VERSION "HNNBNNNYNNNNNNNNNNNNNNNNNNNNNNNNNNNNNNNNNN/4/%%%/4/'%**4NNN///"

NS_ :

BS_ :

BU_:  Airbag BAP_Tester ICAS1_Gateway ICAS1_KommunikationsServer LE1 LE2 Motor_BEV Schaltbetaetigung

BO_ 333 ACC_18: 32 ICAS1_Gateway
 SG_ ACC_18_CRC  : 0|8@1+ (1.000000,0.000000) [0.000000|255.000000] "" Motor_BEV
 SG_ ACC_18_BZ  : 8|4@1+ (1.000000,0.000000) [0.000000|15.000000] "" Motor_BEV
 SG_ ACC_limitierte_Anfahrdyn  : 12|1@1+ (1.000000,0.000000) [0.000000|1.000000] "" Motor_BEV
 SG_ ACC_nachtr_Stopp_Anf  : 13|1@1+ (1.000000,0.000000) [0.000000|1.000000] "" Vector__XXX
 SG_ ACC_DynErhoehung  : 14|1@1+ (1.000000,0.000000) [0.000000|1.000000] "" Motor_BEV
 SG_ ACC_Freilaufstrategie_TSK  : 15|1@1+ (1.000000,0.000000) [0.000000|1.000000] "" Motor_BEV
 SG_ ACC_zul_Regelabw_unten  : 16|6@1+ (0.024000,0.000000) [0.000000|1.512000] "Unit_MeterPerSeconSquar" Motor_BEV
 SG_ ACC_StartStopp_Info  : 22|2@1+ (1.000000,0.000000) [0.000000|3.000000] "" Vector__XXX
 SG_ ACC_Sollbeschleunigung_02  : 24|11@1+ (0.005000,-7.220000) [-7.220000|3.005000] "Unit_MeterPerSeconSquar" Motor_BEV
 SG_ ACC_zul_Regelabw_oben  : 35|5@1+ (0.062500,0.000000) [0.000000|1.937500] "Unit_MeterPerSeconSquar" Motor_BEV
 SG_ ACC_neg_Sollbeschl_Grad_02  : 40|8@1+ (0.050000,0.000000) [0.000000|12.750000] "Unit_MeterPerCubicSecon" Motor_BEV
 SG_ ACC_pos_Sollbeschl_Grad_02  : 48|8@1+ (0.050000,0.000000) [0.000000|12.750000] "Unit_MeterPerCubicSecon" Motor_BEV
 SG_ ACC_Anfahren  : 56|1@1+ (1.000000,0.000000) [0.000000|1.000000] "" Motor_BEV
 SG_ ACC_Anhalten  : 57|1@1+ (1.000000,0.000000) [0.000000|1.000000] "" Motor_BEV
 SG_ ACC_Typ  : 58|2@1+ (1.000000,0.000000) [0.000000|3.000000] "" Motor_BEV
 SG_ ACC_Status_ACC  : 60|3@1+ (1.000000,0.000000) [0.000000|7.000000] "" Motor_BEV
 SG_ ACC_Minimale_Bremsung  : 63|1@1+ (1.000000,0.000000) [0.000000|1.000000] "" Motor_BEV
 SG_ ACC_Anhalteweg  : 64|11@1+ (0.010000,0.000000) [0.000000|20.450000] "Unit_Meter" Vector__XXX
 SG_ ACC_Boost  : 75|1@1+ (1.000000,0.000000) [0.000000|1.000000] "" Vector__XXX
 SG_ ACC_Freilauf_Anf  : 76|1@1+ (1.000000,0.000000) [0.000000|1.000000] "" Vector__XXX
 SG_ ACC_Anforderung_HMS  : 77|3@1+ (1.000000,0.000000) [0.000000|7.000000] "" Vector__XXX
 SG_ ACC_Folgebeschl  : 80|8@1+ (0.030000,-4.600000) [-4.600000|2.990000] "Unit_MeterPerSeconSquar" Motor_BEV
 SG_ ACC_Freilauf_Info  : 88|2@1+ (1.000000,0.000000) [0.000000|3.000000] "" Motor_BEV
 SG_ ACC_Tempolimitassistent_Ein  : 90|1@1+ (1.000000,0.000000) [0.000000|1.000000] "" Vector__XXX
 SG_ ACC_FoD_Status  : 91|2@1+ (1.000000,0.000000) [0.000000|3.000000] "" Motor_BEV
 SG_ vESC_Verz_Anf  : 232|4@1+ (0.500000,0.000000) [0.000000|3.500000] "Unit_MeterPerSeconSquar" Vector__XXX
 SG_ RDR_v_ueber_Grund  : 236|12@1+ (0.100000,0.000000) [0.000000|409.000000] "Unit_KiloMeterPerHour" Vector__XXX
 SG_ RDR_v_ueber_Grund_Genauigkeit  : 248|6@1+ (0.100000,0.000000) [0.000000|6.000000] "Unit_KiloMeterPerHour" Vector__XXX
 SG_ RDR_v_ueber_Grund_Fahrtrichtung  : 254|2@1+ (1.000000,0.000000) [0.000000|3.000000] "" Vector__XXX

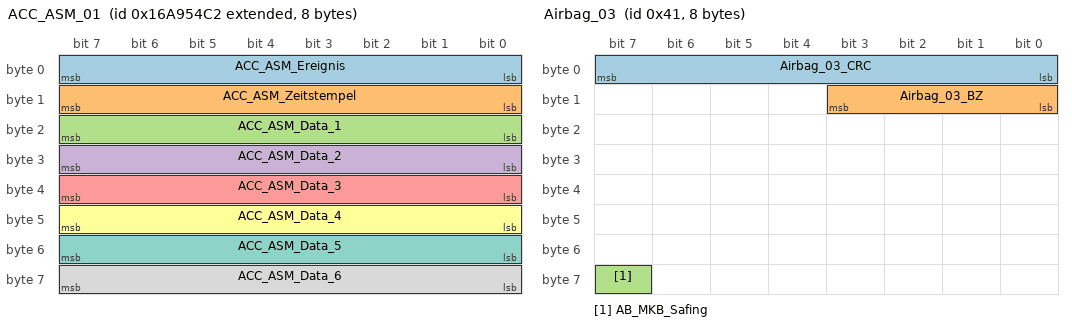
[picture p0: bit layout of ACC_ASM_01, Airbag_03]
BO_ 2527679682 ACC_ASM_01: 8 ICAS1_Gateway
 SG_ ACC_ASM_Ereignis  : 0|8@1+ (1.000000,0.000000) [1.000000|254.000000] "" Airbag
 SG_ ACC_ASM_Zeitstempel  : 8|8@1+ (0.080000,0.000000) [0.000000|20.320000] "Unit_Secon" Airbag
 SG_ ACC_ASM_Data_1  : 16|8@1+ (1.000000,0.000000) [0.000000|255.000000] "" Airbag
 SG_ ACC_ASM_Data_2  : 24|8@1+ (1.000000,0.000000) [0.000000|255.000000] "" Airbag
 SG_ ACC_ASM_Data_3  : 32|8@1+ (1.000000,0.000000) [0.000000|255.000000] "" Airbag
 SG_ ACC_ASM_Data_4  : 40|8@1+ (1.000000,0.000000) [0.000000|255.000000] "" Airbag
 SG_ ACC_ASM_Data_5  : 48|8@1+ (1.000000,0.000000) [0.000000|255.000000] "" Airbag
 SG_ ACC_ASM_Data_6  : 56|8@1+ (1.000000,0.000000) [0.000000|255.000000] "" Airbag

BO_ 64 Airbag_01: 8 Airbag
 SG_ Airbag_01_CRC  : 0|8@1+ (1.000000,0.000000) [0.000000|255.000000] "" ICAS1_Gateway LE1 LE2 Motor_BEV
 SG_ Airbag_01_BZ  : 8|4@1+ (1.000000,0.000000) [0.000000|15.000000] "" ICAS1_Gateway LE1 LE2 Motor_BEV
 SG_ AB_RGS_Anst  : 12|4@1+ (1.000000,0.000000) [0.000000|15.000000] "" ICAS1_Gateway ICAS1_KommunikationsServer
 SG_ AB_Front_Crash  : 16|1@1+ (1.000000,0.000000) [0.000000|1.000000] "" ICAS1_Gateway
 SG_ AB_Heck_Crash  : 17|1@1+ (1.000000,0.000000) [0.000000|1.000000] "" ICAS1_Gateway
 SG_ AB_SF_Crash  : 18|1@1+ (1.000000,0.000000) [0.000000|1.000000] "" ICAS1_Gateway
 SG_ AB_SB_Crash  : 19|1@1+ (1.000000,0.000000) [0.000000|1.000000] "" ICAS1_Gateway
 SG_ AB_Rollover_Crash  : 20|1@1+ (1.000000,0.000000) [0.000000|1.000000] "" ICAS1_Gateway
 SG_ AB_Crash_Int  : 21|3@1+ (1.000000,0.000000) [0.000000|7.000000] "" ICAS1_Gateway ICAS1_KommunikationsServer Motor_BEV
 SG_ AB_Lampe  : 24|1@1+ (1.000000,0.000000) [0.000000|1.000000] "" ICAS1_Gateway ICAS1_KommunikationsServer
 SG_ AB_Deaktiviert  : 25|1@1+ (1.000000,0.000000) [0.000000|1.000000] "" ICAS1_Gateway
 SG_ AB_VB_deaktiviert  : 26|1@1+ (1.000000,0.000000) [0.000000|1.000000] "" ICAS1_Gateway
 SG_ AB_Systemfehler  : 27|1@1+ (1.000000,0.000000) [0.000000|1.000000] "" ICAS1_Gateway ICAS1_KommunikationsServer
 SG_ AB_Diagnose  : 28|1@1+ (1.000000,0.000000) [0.000000|1.000000] "" ICAS1_Gateway
 SG_ AB_Stellgliedtest  : 29|1@1+ (1.000000,0.000000) [0.000000|1.000000] "" ICAS1_Gateway
 SG_ AB_Erh_Auf_VB  : 30|2@1+ (1.000000,0.000000) [0.000000|3.000000] "" ICAS1_Gateway
 SG_ AB_Gurtwarn_VF  : 32|1@1+ (1.000000,0.000000) [0.000000|1.000000] "" ICAS1_Gateway ICAS1_KommunikationsServer
 SG_ AB_Gurtwarn_VB  : 33|1@1+ (1.000000,0.000000) [0.000000|1.000000] "" ICAS1_Gateway ICAS1_KommunikationsServer
 SG_ AB_Anzeige_Fussg  : 34|2@1+ (1.000000,0.000000) [0.000000|3.000000] "" ICAS1_Gateway
 SG_ AB_Texte_AKS  : 36|2@1+ (1.000000,0.000000) [0.000000|3.000000] "" ICAS1_Gateway
 SG_ AB_PAO_Leuchte_Anf  : 38|1@1+ (1.000000,0.000000) [0.000000|1.000000] "" ICAS1_Gateway
 SG_ AB_MKB_gueltig  : 39|1@1+ (1.000000,0.000000) [0.000000|1.000000] "" ICAS1_Gateway
 SG_ AB_MKB_Anforderung  : 40|1@1+ (1.000000,0.000000) [0.000000|1.000000] "" ICAS1_Gateway
 SG_ AB_Versorgungsspannung  : 41|1@1+ (1.000000,0.000000) [0.000000|1.000000] "" ICAS1_Gateway
 SG_ AB_Deaktivierung_HV  : 42|3@1+ (1.000000,0.000000) [0.000000|7.000000] "" ICAS1_Gateway ICAS1_KommunikationsServer LE1 LE2 Motor_BEV
 SG_ AB_EDR_Trigger  : 45|2@1+ (1.000000,0.000000) [0.000000|3.000000] "" ICAS1_Gateway
 SG_ AB_Belegung_VF  : 47|2@1+ (1.000000,0.000000) [0.000000|3.000000] "" ICAS1_Gateway
 SG_ AB_Gurtschloss_FA_ext  : 49|3@1+ (1.000000,0.000000) [0.000000|7.000000] "" ICAS1_Gateway
 SG_ AB_Belegung_VF_ext  : 52|3@1+ (1.000000,0.000000) [0.000000|7.000000] "" ICAS1_Gateway
 SG_ ASM_Masterzeit  : 56|8@1+ (0.080000,0.000000) [0.000000|20.320000] "Unit_Secon" ICAS1_Gateway

BO_ 1312 Airbag_02: 8 Airbag
 SG_ Airbag_02_CRC  : 0|8@1+ (1.000000,0.000000) [0.000000|255.000000] "" ICAS1_Gateway Motor_BEV
 SG_ Airbag_02_BZ  : 8|4@1+ (1.000000,0.000000) [0.000000|15.000000] "" ICAS1_Gateway Motor_BEV
 SG_ LoGeWa_Event_Kombiwarnung  : 12|4@1+ (1.000000,0.000000) [0.000000|15.000000] "" ICAS1_Gateway
 SG_ AB_Anforderung_eCall  : 16|1@1+ (1.000000,0.000000) [0.000000|1.000000] "" ICAS1_Gateway
 SG_ AB_Anprall_Seite_Beifahrer  : 17|1@1+ (1.000000,0.000000) [0.000000|1.000000] "" ICAS1_Gateway ICAS1_KommunikationsServer
 SG_ AB_Anprall_Rollover  : 18|1@1+ (1.000000,0.000000) [0.000000|1.000000] "" ICAS1_Gateway ICAS1_KommunikationsServer
 SG_ AB_Anprall_FGS  : 19|1@1+ (1.000000,0.000000) [0.000000|1.000000] "" ICAS1_Gateway ICAS1_KommunikationsServer
 SG_ AB_Anprall_Front_Beifahrer  : 20|1@1+ (1.000000,0.000000) [0.000000|1.000000] "" ICAS1_Gateway ICAS1_KommunikationsServer
 SG_ AB_Anprall_Front_Fahrer  : 21|1@1+ (1.000000,0.000000) [0.000000|1.000000] "" ICAS1_Gateway ICAS1_KommunikationsServer
 SG_ AB_Anprall_Heck_Beifahrer  : 22|1@1+ (1.000000,0.000000) [0.000000|1.000000] "" ICAS1_Gateway ICAS1_KommunikationsServer
 SG_ AB_Anprall_Heck_Fahrer  : 23|1@1+ (1.000000,0.000000) [0.000000|1.000000] "" ICAS1_Gateway ICAS1_KommunikationsServer
 SG_ AB_Wickelklappung_Reihe2_MI  : 24|2@1+ (1.000000,0.000000) [0.000000|3.000000] "" ICAS1_Gateway
 SG_ AB_Belegung_VB  : 26|2@1+ (1.000000,0.000000) [0.000000|3.000000] "" ICAS1_Gateway
 SG_ AB_Abschaltanf_SIH_BF  : 28|1@1+ (1.000000,0.000000) [0.000000|1.000000] "" ICAS1_Gateway
 SG_ AB_Anprall_Seite_Fahrer  : 29|1@1+ (1.000000,0.000000) [0.000000|1.000000] "" ICAS1_Gateway ICAS1_KommunikationsServer
 SG_ SC_PAO_Schriftzug_Anf  : 30|2@1+ (1.000000,0.000000) [0.000000|3.000000] "" ICAS1_Gateway
 SG_ SC_PAO_ON_Anf  : 32|2@1+ (1.000000,0.000000) [0.000000|3.000000] "" ICAS1_Gateway
 SG_ SC_PAO_OFF_Anf  : 34|2@1+ (1.000000,0.000000) [0.000000|3.000000] "" ICAS1_Gateway
 SG_ AB_Crashschwere  : 36|3@1+ (1.000000,0.000000) [0.000000|7.000000] "" ICAS1_Gateway ICAS1_KommunikationsServer
 SG_ AB_Anforderung_USM  : 39|1@1+ (1.000000,0.000000) [0.000000|1.000000] "" ICAS1_Gateway
 SG_ AB_Gurtschloss_FA  : 40|2@1+ (1.000000,0.000000) [0.000000|3.000000] "" ICAS1_Gateway ICAS1_KommunikationsServer Motor_BEV
 SG_ AB_Gurtschloss_BF  : 42|2@1+ (1.000000,0.000000) [0.000000|3.000000] "" ICAS1_Gateway ICAS1_KommunikationsServer
 SG_ AB_Gurtschloss_Reihe2_FA  : 44|2@1+ (1.000000,0.000000) [0.000000|3.000000] "" ICAS1_Gateway ICAS1_KommunikationsServer
 SG_ AB_Gurtschloss_Reihe2_MI  : 46|2@1+ (1.000000,0.000000) [0.000000|3.000000] "" ICAS1_Gateway ICAS1_KommunikationsServer
 SG_ AB_Gurtschloss_Reihe2_BF  : 48|2@1+ (1.000000,0.000000) [0.000000|3.000000] "" ICAS1_Gateway ICAS1_KommunikationsServer
 SG_ AB_Gurtschloss_Reihe3_FA  : 50|2@1+ (1.000000,0.000000) [0.000000|3.000000] "" ICAS1_Gateway ICAS1_KommunikationsServer
 SG_ AB_Gurtschloss_Reihe3_MI  : 52|2@1+ (1.000000,0.000000) [0.000000|3.000000] "" ICAS1_Gateway ICAS1_KommunikationsServer
 SG_ AB_Gurtschloss_Reihe3_BF  : 54|2@1+ (1.000000,0.000000) [0.000000|3.000000] "" ICAS1_Gateway ICAS1_KommunikationsServer
 SG_ AB_Sitzpos_Sens_FA  : 56|2@1+ (1.000000,0.000000) [0.000000|3.000000] "" ICAS1_Gateway
 SG_ AB_Sitzpos_Sens_BF  : 58|2@1+ (1.000000,0.000000) [0.000000|3.000000] "" ICAS1_Gateway
 SG_ AB_Wickelklappung_Reihe2_BF  : 60|2@1+ (1.000000,0.000000) [0.000000|3.000000] "" ICAS1_Gateway
 SG_ AB_Wickelklappung_Reihe2_FA  : 62|2@1+ (1.000000,0.000000) [0.000000|3.000000] "" ICAS1_Gateway

BO_ 65 Airbag_03: 8 Airbag
 SG_ Airbag_03_CRC  : 0|8@1+ (1.000000,0.000000) [0.000000|255.000000] "" ICAS1_Gateway
 SG_ Airbag_03_BZ  : 8|4@1+ (1.000000,0.000000) [0.000000|15.000000] "" ICAS1_Gateway
 SG_ AB_MKB_Safing  : 63|1@1+ (1.000000,0.000000) [0.000000|1.000000] "" ICAS1_Gateway

BO_ 1349 Airbag_04: 8 Airbag
 SG_ AB_Gurtwarn_Reihe4_FA  : 14|2@1+ (1.000000,0.000000) [0.000000|3.000000] "" ICAS1_Gateway ICAS1_KommunikationsServer
 SG_ AB_Gurtwarn_Reihe4_BF  : 16|2@1+ (1.000000,0.000000) [0.000000|3.000000] "" ICAS1_Gateway ICAS1_KommunikationsServer
 SG_ AB_Gurtwarn_Reihe4_MI  : 18|2@1+ (1.000000,0.000000) [0.000000|3.000000] "" ICAS1_Gateway ICAS1_KommunikationsServer
 SG_ AB_Gurtwarn_Reihe2_FA  : 20|2@1+ (1.000000,0.000000) [0.000000|3.000000] "" ICAS1_Gateway ICAS1_KommunikationsServer
 SG_ AB_Gurtwarn_Reihe2_BF  : 22|2@1+ (1.000000,0.000000) [0.000000|3.000000] "" ICAS1_Gateway ICAS1_KommunikationsServer
 SG_ AbstWarn_MV_FAS_Fkt_Status  : 24|2@1+ (1.000000,0.000000) [0.000000|3.000000] "" ICAS1_Gateway
 SG_ WarnBrems_Charisma_Status  : 26|2@1+ (1.000000,0.000000) [0.000000|3.000000] "" ICAS1_Gateway
 SG_ WarnBrems_Charisma_FahrPr  : 28|4@1+ (1.000000,0.000000) [0.000000|15.000000] "" ICAS1_Gateway
 SG_ AB_Gurtwarn_Reihe2_MI  : 32|2@1+ (1.000000,0.000000) [0.000000|3.000000] "" ICAS1_Gateway ICAS1_KommunikationsServer
 SG_ AB_Gurtwarn_Reihe3_FA  : 34|2@1+ (1.000000,0.000000) [0.000000|3.000000] "" ICAS1_Gateway ICAS1_KommunikationsServer
 SG_ AB_Gurtwarn_Reihe3_MI  : 36|2@1+ (1.000000,0.000000) [0.000000|3.000000] "" ICAS1_Gateway ICAS1_KommunikationsServer
 SG_ AB_Gurtwarn_Reihe3_BF  : 38|2@1+ (1.000000,0.000000) [0.000000|3.000000] "" ICAS1_Gateway ICAS1_KommunikationsServer
 SG_ LGI_FAS_Fkt_Status  : 40|2@1+ (1.000000,0.000000) [0.000000|3.000000] "" ICAS1_Gateway
 SG_ PreCrash_FAS_Fkt_Status  : 42|3@1+ (1.000000,0.000000) [0.000000|7.000000] "" ICAS1_Gateway
 SG_ AB_SBR_hinten_verbau  : 48|2@1+ (1.000000,0.000000) [0.000000|3.000000] "" ICAS1_Gateway ICAS1_KommunikationsServer
 SG_ AWV_Einstellung_System_ASG  : 51|1@1+ (1.000000,0.000000) [0.000000|1.000000] "" ICAS1_Gateway
 SG_ AWV_Einstellung_Warnung_ASG  : 52|3@1+ (1.000000,0.000000) [0.000000|7.000000] "" ICAS1_Gateway
 SG_ SC_PreSense_Modus_Warnung_NV  : 55|3@1+ (1.000000,0.000000) [0.000000|7.000000] "" ICAS1_Gateway
 SG_ SC_PreSense_Modus_Warnung_MV  : 58|3@1+ (1.000000,0.000000) [0.000000|7.000000] "" ICAS1_Gateway
 SG_ SC_PreSense_Modus_System_MV  : 61|1@1+ (1.000000,0.000000) [0.000000|1.000000] "" ICAS1_Gateway
 SG_ SC_PreSense_Modus_System_NV  : 62|1@1+ (1.000000,0.000000) [0.000000|1.000000] "" ICAS1_Gateway
 SG_ SC_PreSense_Modus_System_KAS  : 63|1@1+ (1.000000,0.000000) [0.000000|1.000000] "" ICAS1_Gateway

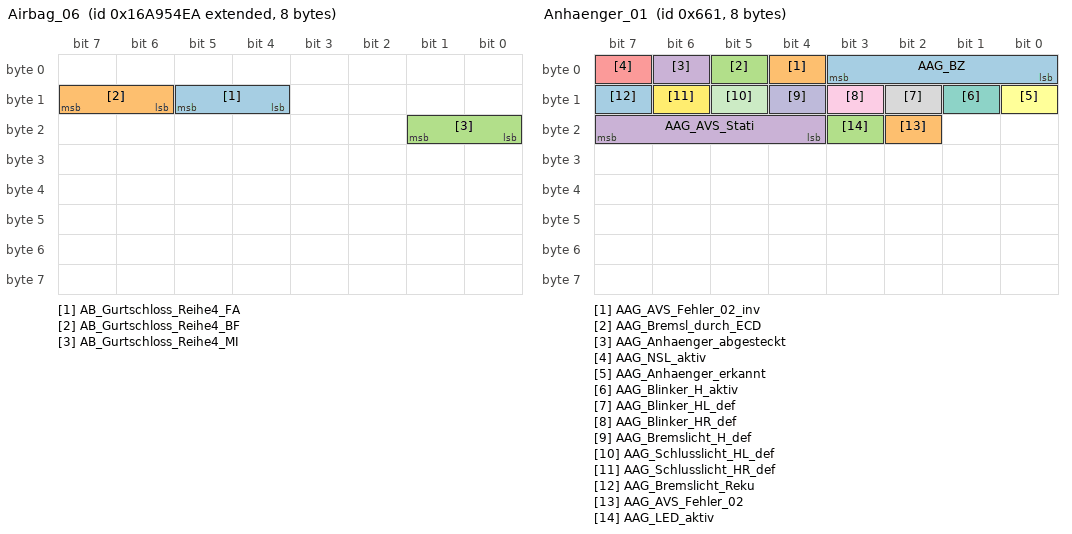
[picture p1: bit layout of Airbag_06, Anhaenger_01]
BO_ 2527679722 Airbag_06: 8 Airbag
 SG_ AB_Gurtschloss_Reihe4_FA  : 12|2@1+ (1.000000,0.000000) [0.000000|3.000000] "" ICAS1_Gateway ICAS1_KommunikationsServer
 SG_ AB_Gurtschloss_Reihe4_BF  : 14|2@1+ (1.000000,0.000000) [0.000000|3.000000] "" ICAS1_Gateway ICAS1_KommunikationsServer
 SG_ AB_Gurtschloss_Reihe4_MI  : 16|2@1+ (1.000000,0.000000) [0.000000|3.000000] "" ICAS1_Gateway ICAS1_KommunikationsServer

BO_ 1633 Anhaenger_01: 8 ICAS1_Gateway
 SG_ AAG_BZ  : 0|4@1+ (1.000000,0.000000) [0.000000|15.000000] "" Vector__XXX
 SG_ AAG_AVS_Fehler_02_inv  : 4|1@1+ (1.000000,0.000000) [0.000000|1.000000] "" Vector__XXX
 SG_ AAG_Bremsl_durch_ECD  : 5|1@1+ (1.000000,0.000000) [0.000000|1.000000] "" Motor_BEV
 SG_ AAG_Anhaenger_abgesteckt  : 6|1@1+ (1.000000,0.000000) [0.000000|1.000000] "" Motor_BEV
 SG_ AAG_NSL_aktiv  : 7|1@1+ (1.000000,0.000000) [0.000000|1.000000] "" Vector__XXX
 SG_ AAG_Anhaenger_erkannt  : 8|1@1+ (1.000000,0.000000) [0.000000|1.000000] "" Motor_BEV
 SG_ AAG_Blinker_H_aktiv  : 9|1@1+ (1.000000,0.000000) [0.000000|1.000000] "" Vector__XXX
 SG_ AAG_Blinker_HL_def  : 10|1@1+ (1.000000,0.000000) [0.000000|1.000000] "" Vector__XXX
 SG_ AAG_Blinker_HR_def  : 11|1@1+ (1.000000,0.000000) [0.000000|1.000000] "" Vector__XXX
 SG_ AAG_Bremslicht_H_def  : 12|1@1+ (1.000000,0.000000) [0.000000|1.000000] "" Motor_BEV
 SG_ AAG_Schlusslicht_HL_def  : 13|1@1+ (1.000000,0.000000) [0.000000|1.000000] "" Vector__XXX
 SG_ AAG_Schlusslicht_HR_def  : 14|1@1+ (1.000000,0.000000) [0.000000|1.000000] "" Vector__XXX
 SG_ AAG_Bremslicht_Reku  : 15|1@1+ (1.000000,0.000000) [0.000000|1.000000] "" Vector__XXX
 SG_ AAG_AVS_Fehler_02  : 18|1@1+ (1.000000,0.000000) [0.000000|1.000000] "" Vector__XXX
 SG_ AAG_LED_aktiv  : 19|1@1+ (1.000000,0.000000) [0.000000|1.000000] "" Vector__XXX
 SG_ AAG_AVS_Stati  : 20|4@1+ (1.000000,0.000000) [0.000000|15.000000] "" Vector__XXX

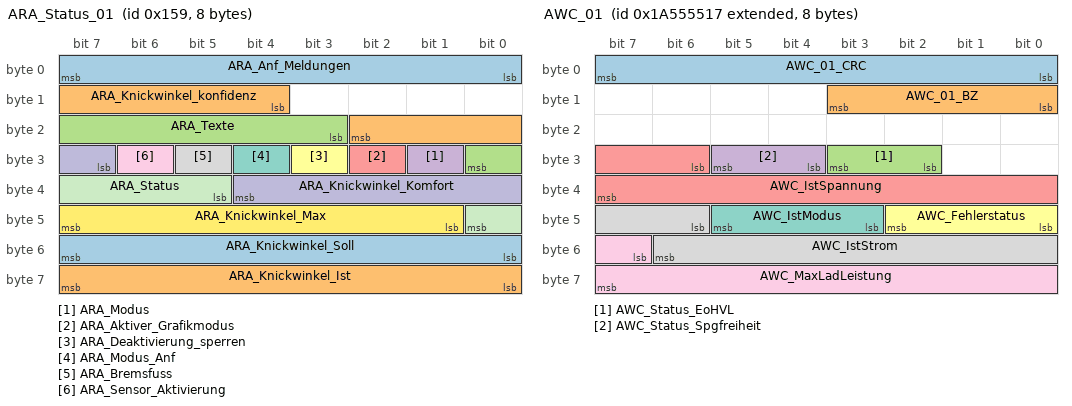
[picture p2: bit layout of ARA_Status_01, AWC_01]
BO_ 345 ARA_Status_01: 8 ICAS1_Gateway
 SG_ ARA_Anf_Meldungen  : 0|8@1+ (1.000000,0.000000) [0.000000|255.000000] "" Vector__XXX
 SG_ ARA_Knickwinkel_konfidenz  : 12|7@1+ (1.000000,0.000000) [0.000000|120.000000] "Unit_DegreOfArc" Vector__XXX
 SG_ ARA_Texte  : 19|6@1+ (1.000000,0.000000) [0.000000|63.000000] "" Vector__XXX
 SG_ ARA_Modus  : 25|1@1+ (1.000000,0.000000) [0.000000|1.000000] "" Vector__XXX
 SG_ ARA_Aktiver_Grafikmodus  : 26|1@1+ (1.000000,0.000000) [0.000000|1.000000] "" Vector__XXX
 SG_ ARA_Deaktivierung_sperren  : 27|1@1+ (1.000000,0.000000) [0.000000|1.000000] "" Vector__XXX
 SG_ ARA_Modus_Anf  : 28|1@1+ (1.000000,0.000000) [0.000000|1.000000] "" Vector__XXX
 SG_ ARA_Bremsfuss  : 29|1@1+ (1.000000,0.000000) [0.000000|1.000000] "" Vector__XXX
 SG_ ARA_Sensor_Aktivierung  : 30|1@1+ (1.000000,0.000000) [0.000000|1.000000] "" Vector__XXX
 SG_ ARA_Knickwinkel_Komfort  : 31|6@1+ (1.000000,0.000000) [0.000000|60.000000] "Unit_DegreOfArc" Vector__XXX
 SG_ ARA_Status  : 37|4@1+ (1.000000,0.000000) [0.000000|15.000000] "" Motor_BEV
 SG_ ARA_Knickwinkel_Max  : 41|7@1+ (1.000000,0.000000) [0.000000|120.000000] "Unit_DegreOfArc" Vector__XXX
 SG_ ARA_Knickwinkel_Soll  : 48|8@1+ (1.000000,-125.000000) [-125.000000|126.000000] "Unit_DegreOfArc" Vector__XXX
 SG_ ARA_Knickwinkel_Ist  : 56|8@1+ (1.000000,-125.000000) [-125.000000|126.000000] "Unit_DegreOfArc" Vector__XXX

BO_ 2589283607 AWC_01: 8 ICAS1_Gateway
 SG_ AWC_01_CRC  : 0|8@1+ (1.000000,0.000000) [0.000000|255.000000] "" Vector__XXX
 SG_ AWC_01_BZ  : 8|4@1+ (1.000000,0.000000) [0.000000|15.000000] "" Vector__XXX
 SG_ AWC_Status_EoHVL  : 26|2@1+ (1.000000,0.000000) [0.000000|3.000000] "" Motor_BEV
 SG_ AWC_Status_Spgfreiheit  : 28|2@1+ (1.000000,0.000000) [0.000000|3.000000] "" Vector__XXX
 SG_ AWC_IstSpannung  : 30|10@1+ (1.000000,0.000000) [0.000000|1021.000000] "Unit_Volt" Vector__XXX
 SG_ AWC_Fehlerstatus  : 40|3@1+ (1.000000,0.000000) [0.000000|7.000000] "" Vector__XXX
 SG_ AWC_IstModus  : 43|3@1+ (1.000000,0.000000) [0.000000|7.000000] "" Vector__XXX
 SG_ AWC_IstStrom  : 46|9@1+ (0.100000,0.000000) [0.000000|50.900000] "Unit_Amper" Vector__XXX
 SG_ AWC_MaxLadLeistung  : 55|9@1+ (25.000000,0.000000) [0.000000|12725.000000] "Unit_Watt" Vector__XXX

BO_ 219 AWV_03: 48 ICAS1_Gateway
 SG_ AWV_03_CRC  : 0|8@1+ (1.000000,0.000000) [0.000000|255.000000] "" Airbag
 SG_ AWV_03_BZ  : 8|4@1+ (1.000000,0.000000) [0.000000|15.000000] "" Airbag
 SG_ PCF_Freigabe  : 12|1@1+ (1.000000,0.000000) [0.000000|1.000000] "" Airbag
 SG_ SDF_PSF_Objektstatus  : 13|3@1+ (1.000000,0.000000) [0.000000|7.000000] "" Airbag
 SG_ SDF_PSF_CU_Status  : 16|1@1+ (1.000000,0.000000) [0.000000|1.000000] "" Airbag
 SG_ SDF_PSF_CW  : 17|7@1+ (1.000000,0.000000) [0.000000|100.000000] "" Airbag
 SG_ SDF_PSF_Fahrer_aktiv  : 24|1@1+ (1.000000,0.000000) [0.000000|1.000000] "" Airbag
 SG_ SDF_PSF_Guete  : 25|2@1+ (1.000000,0.000000) [0.000000|3.000000] "" Airbag
 SG_ SDF_PSF_Kollisionsueberdeckung  : 27|5@1+ (0.100000,0.000000) [0.100000|2.800000] "Unit_Meter" Airbag
 SG_ SDF_PSF_Time_To_Collision  : 32|8@1+ (0.010000,0.000000) [0.000000|2.500000] "Unit_Secon" Vector__XXX
 SG_ SDF_PSF_v_rel  : 40|8@1+ (0.400000,0.000000) [0.400000|101.200000] "Unit_MeterPerSecon" Airbag
 SG_ AWV_Eingriff_Sendeart  : 64|1@1+ (1.000000,0.000000) [0.000000|1.000000] "" Airbag
 SG_ AWV_Verz_Freigabe  : 65|1@1+ (1.000000,0.000000) [0.000000|1.000000] "" Airbag
 SG_ AWV_Verz_Anf  : 66|10@1+ (0.024000,-20.016000) [-20.016000|4.512000] "Unit_MeterPerSeconSquar" Airbag
 SG_ AWV_Anf_Prefill  : 76|1@1+ (1.000000,0.000000) [0.000000|1.000000] "" Airbag
 SG_ AWV_Ruckprofil  : 77|3@1+ (1.000000,0.000000) [0.000000|7.000000] "" Vector__XXX
 SG_ AWV_Time_to_collision  : 80|8@1+ (0.010000,0.000000) [0.000000|2.500000] "Unit_Secon" Airbag
 SG_ AWV_HBA_Param  : 88|2@1+ (1.000000,0.000000) [0.000000|3.000000] "" Vector__XXX
 SG_ AWV_Verz_Anf_ASIL  : 90|3@1+ (1.000000,0.000000) [0.000000|7.000000] "" Vector__XXX
 SG_ AWV_Time_to_brake  : 93|7@1+ (10.000000,0.000000) [0.000000|1240.000000] "Unit_MilliSecon" Vector__XXX
 SG_ AWV_Zielobjekttyp  : 100|4@1+ (1.000000,0.000000) [0.000000|15.000000] "" Airbag
 SG_ AWV_QFK_KruemmSoll  : 104|15@1+ (0.000007,0.000000) [0.000000|0.219539] "Unit_MeterInver" Vector__XXX
 SG_ AWV_QFK_KruemmSoll_VZ  : 119|1@1+ (1.000000,0.000000) [0.000000|1.000000] "" Vector__XXX
 SG_ AWV_QFK_Spuerb  : 120|8@1+ (0.400000,0.000000) [0.000000|100.000000] "Unit_PerCent" Vector__XXX
 SG_ AWV_QFK_AnfStat  : 128|4@1+ (1.000000,0.000000) [0.000000|15.000000] "" Airbag
 SG_ AWV_QFK_Signal1  : 132|10@1+ (1.000000,0.000000) [0.000000|1023.000000] "" Vector__XXX
 SG_ AWV_QFK_Art1  : 142|3@1+ (1.000000,0.000000) [0.000000|7.000000] "" Vector__XXX
 SG_ AWV_QFK_Art2  : 145|3@1+ (1.000000,0.000000) [0.000000|7.000000] "" Vector__XXX
 SG_ AWV_QFK_Signal2  : 148|10@1+ (1.000000,0.000000) [0.000000|1023.000000] "" Vector__XXX

BO_ 2536767264 BAP_Debug_Cmd: 8 BAP_Tester
 SG_ BAP_Debug_Cmd  : 0|16@1+ (1.000000,0.000000) [0.000000|65535.000000] "" Motor_BEV

BO_ 2536767280 BAP_Debug_Data: 8 Motor_BEV
 SG_ BAP_Debug_Data  : 0|64@1+ (1.000000,0.000000) [0.000000|18446744073709551616.000000] "" BAP_Tester

BO_ 2536717313 BAP_EfficiencyAssist_ASG_02: 8 ICAS1_Gateway
 SG_ BAP_EfficAssist_ASG_02_Header  : 0|64@1+ (1.000000,0.000000) [0.000000|18446744073709551616.000000] "" Motor_BEV

BO_ 2536717314 BAP_EfficiencyAssist_ASG_03: 8 ICAS1_Gateway
 SG_ BAP_EfficAssist_ASG_03_Header  : 0|8@1+ (1.000000,0.000000) [0.000000|255.000000] "" Motor_BEV

BO_ 2536717328 BAP_EfficiencyAssist_FSG_01: 8 Motor_BEV
 SG_ BAP_EfficAssist_FSG_01_Header  : 0|8@1+ (1.000000,0.000000) [0.000000|255.000000] "" ICAS1_Gateway

BO_ 2536709120 BAP_Hybrid_ASG_01: 8 ICAS1_Gateway
 SG_ BAP_Hybrid_ASG_01_Header  : 0|8@1+ (1.000000,0.000000) [0.000000|255.000000] "" Motor_BEV

BO_ 2536709136 BAP_Hybrid_FSG_01: 8 Motor_BEV
 SG_ BAP_Hybrid_FSG_01_Header  : 0|8@1+ (1.000000,0.000000) [0.000000|255.000000] "" ICAS1_Gateway

BO_ 869 BEM_05: 8 ICAS1_Gateway
 SG_ BEM_UBDM  : 0|8@1+ (0.050000,5.000000) [5.050000|17.700000] "Unit_Volt" Vector__XXX
 SG_ NVEM_Ladefreigabe  : 8|2@1+ (1.000000,0.000000) [0.000000|3.000000] "" Vector__XXX
 SG_ NVEM_FMAus_Info  : 10|2@1+ (1.000000,0.000000) [0.000000|3.000000] "" Vector__XXX
 SG_ NVEM_PTC_Sollstufe  : 12|2@1+ (1.000000,0.000000) [0.000000|3.000000] "" Vector__XXX
 SG_ NVEM_P_Generator_Status  : 15|1@1+ (1.000000,0.000000) [0.000000|1.000000] "" Vector__XXX
 SG_ BEM_P_Generator  : 16|8@1+ (50.000000,0.000000) [0.000000|12700.000000] "Unit_Watt" Vector__XXX
 SG_ BEM_n_LLA  : 24|2@1+ (1.000000,0.000000) [0.000000|3.000000] "" Vector__XXX
 SG_ BEM_01_Abschaltstufen  : 26|3@1+ (1.000000,0.000000) [0.000000|7.000000] "" Vector__XXX
 SG_ BEM_Anf_KL  : 29|1@1+ (1.000000,0.000000) [0.000000|1.000000] "" Vector__XXX
 SG_ BEM_StartStopp_Info  : 30|2@1+ (1.000000,0.000000) [0.000000|3.000000] "" Vector__XXX
 SG_ BEM_DFM  : 32|5@1+ (3.225000,0.025000) [0.025000|100.000000] "" Vector__XXX
 SG_ BEM_EMLIN_ungueltig  : 37|1@1+ (1.000000,0.000000) [0.000000|1.000000] "" Vector__XXX
 SG_ BEM_Batt_Ab  : 38|1@1+ (1.000000,0.000000) [0.000000|1.000000] "" Motor_BEV
 SG_ NVEM_FMAus_I_Verbrauch  : 39|5@1+ (5.000000,0.000000) [0.000000|145.000000] "Unit_Amper" Vector__XXX
 SG_ NVEM_Freilauf_Info  : 44|2@1+ (1.000000,0.000000) [0.000000|3.000000] "" Vector__XXX
 SG_ BEM_NV_NachladAnf  : 46|2@1+ (1.000000,0.000000) [0.000000|3.000000] "" Vector__XXX
 SG_ BEM_Segel_Info  : 48|2@1+ (1.000000,0.000000) [0.000000|3.000000] "" Vector__XXX
 SG_ BEM_HYB_DC_uSollLV  : 50|6@1+ (0.100000,10.600000) [10.600000|16.000000] "Unit_Volt" Vector__XXX
 SG_ BEM_HYB_DC_uMinLV  : 56|8@1+ (0.100000,0.000000) [0.000000|25.300000] "Unit_Volt" Vector__XXX

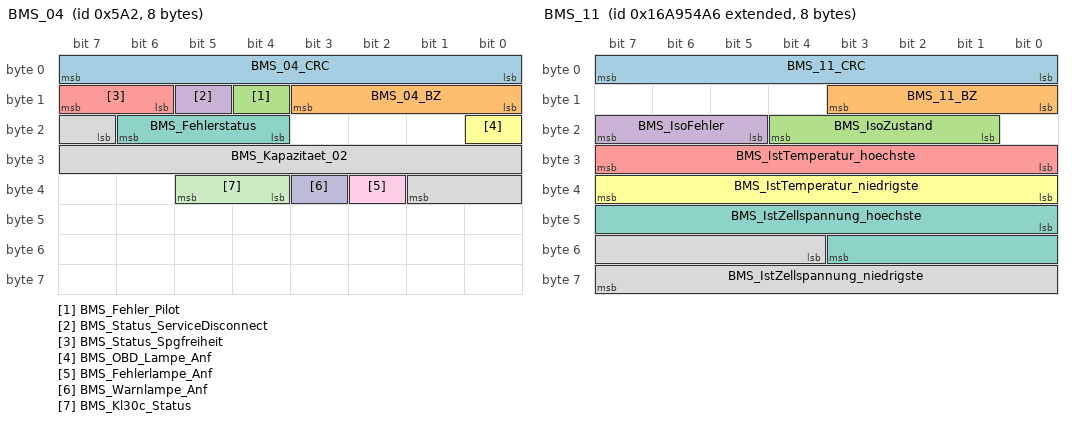
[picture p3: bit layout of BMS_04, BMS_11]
BO_ 1442 BMS_04: 8 ICAS1_Gateway
 SG_ BMS_04_CRC  : 0|8@1+ (1.000000,0.000000) [0.000000|255.000000] "" Vector__XXX
 SG_ BMS_04_BZ  : 8|4@1+ (1.000000,0.000000) [0.000000|15.000000] "" Vector__XXX
 SG_ BMS_Fehler_Pilot  : 12|1@1+ (1.000000,0.000000) [0.000000|1.000000] "" Vector__XXX
 SG_ BMS_Status_ServiceDisconnect  : 13|1@1+ (1.000000,0.000000) [0.000000|1.000000] "" Vector__XXX
 SG_ BMS_Status_Spgfreiheit  : 14|2@1+ (1.000000,0.000000) [0.000000|3.000000] "" Motor_BEV
 SG_ BMS_OBD_Lampe_Anf  : 16|1@1+ (1.000000,0.000000) [0.000000|1.000000] "" Motor_BEV
 SG_ BMS_Fehlerstatus  : 20|3@1+ (1.000000,0.000000) [0.000000|7.000000] "" Vector__XXX
 SG_ BMS_Kapazitaet_02  : 23|11@1+ (0.200000,0.000000) [0.000000|409.200000] "Unit_AmperHour" Vector__XXX
 SG_ BMS_Fehlerlampe_Anf  : 34|1@1+ (1.000000,0.000000) [0.000000|1.000000] "" Motor_BEV
 SG_ BMS_Warnlampe_Anf  : 35|1@1+ (1.000000,0.000000) [0.000000|1.000000] "" Motor_BEV
 SG_ BMS_Kl30c_Status  : 36|2@1+ (1.000000,0.000000) [0.000000|3.000000] "" Motor_BEV

BO_ 2527679654 BMS_11: 8 ICAS1_Gateway
 SG_ BMS_11_CRC  : 0|8@1+ (1.000000,0.000000) [0.000000|255.000000] "" Motor_BEV
 SG_ BMS_11_BZ  : 8|4@1+ (1.000000,0.000000) [0.000000|15.000000] "" Motor_BEV
 SG_ BMS_IsoZustand  : 17|4@1+ (1.000000,0.000000) [0.000000|15.000000] "" Motor_BEV
 SG_ BMS_IsoFehler  : 21|3@1+ (1.000000,0.000000) [0.000000|7.000000] "" Motor_BEV
 SG_ BMS_IstTemperatur_hoechste  : 24|8@1+ (0.500000,-40.000000) [-40.000000|86.000000] "Unit_DegreCelsi" Vector__XXX
 SG_ BMS_IstTemperatur_niedrigste  : 32|8@1+ (0.500000,-40.000000) [-40.000000|86.000000] "Unit_DegreCelsi" Vector__XXX
 SG_ BMS_IstZellspannung_hoechste  : 40|12@1+ (1.000000,1000.000000) [1000.000000|5091.000000] "Unit_MilliVolt" Vector__XXX
 SG_ BMS_IstZellspannung_niedrigste  : 52|12@1+ (1.000000,1000.000000) [1000.000000|5091.000000] "Unit_MilliVolt" Vector__XXX

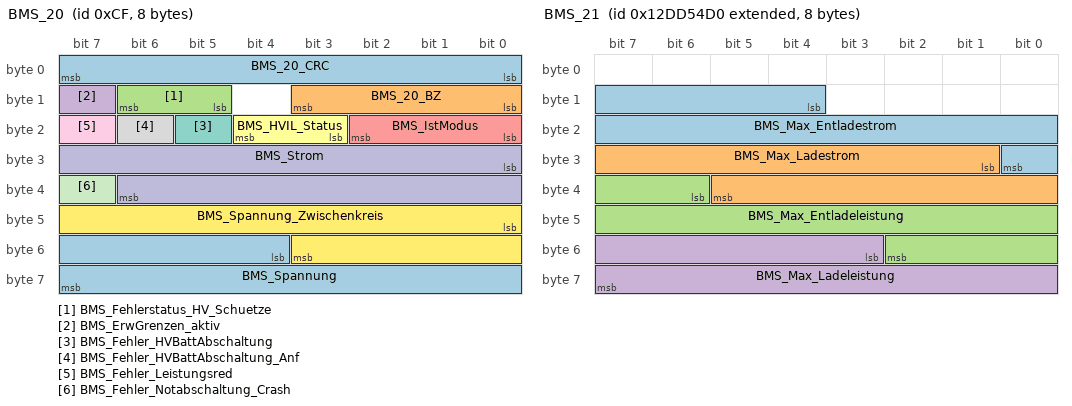
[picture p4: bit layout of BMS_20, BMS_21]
BO_ 207 BMS_20: 8 ICAS1_Gateway
 SG_ BMS_20_CRC  : 0|8@1+ (1.000000,0.000000) [0.000000|255.000000] "" Motor_BEV
 SG_ BMS_20_BZ  : 8|4@1+ (1.000000,0.000000) [0.000000|15.000000] "" Motor_BEV
 SG_ BMS_Fehlerstatus_HV_Schuetze  : 13|2@1+ (1.000000,0.000000) [0.000000|3.000000] "" Motor_BEV
 SG_ BMS_ErwGrenzen_aktiv  : 15|1@1+ (1.000000,0.000000) [0.000000|1.000000] "" Motor_BEV
 SG_ BMS_IstModus  : 16|3@1+ (1.000000,0.000000) [0.000000|7.000000] "" LE1 LE2 Motor_BEV
 SG_ BMS_HVIL_Status  : 19|2@1+ (1.000000,0.000000) [0.000000|3.000000] "" Motor_BEV
 SG_ BMS_Fehler_HVBattAbschaltung  : 21|1@1+ (1.000000,0.000000) [0.000000|1.000000] "" Motor_BEV
 SG_ BMS_Fehler_HVBattAbschaltung_Anf  : 22|1@1+ (1.000000,0.000000) [0.000000|1.000000] "" Motor_BEV
 SG_ BMS_Fehler_Leistungsred  : 23|1@1+ (1.000000,0.000000) [0.000000|1.000000] "" Motor_BEV
 SG_ BMS_Strom  : 24|15@1+ (0.100000,-1630.000000) [-1630.000000|1630.000000] "Unit_Amper" Motor_BEV
 SG_ BMS_Fehler_Notabschaltung_Crash  : 39|1@1+ (1.000000,0.000000) [0.000000|1.000000] "" Vector__XXX
 SG_ BMS_Spannung_Zwischenkreis  : 40|12@1+ (0.500000,-1000.000000) [-1000.000000|1000.000000] "Unit_Volt" Motor_BEV
 SG_ BMS_Spannung  : 52|12@1+ (0.250000,0.000000) [0.000000|1000.000000] "Unit_Volt" Motor_BEV

BO_ 2463978704 BMS_21: 8 ICAS1_Gateway
 SG_ BMS_Max_Entladestrom  : 12|13@1+ (0.200000,0.000000) [0.000000|1630.000000] "Unit_Amper" Motor_BEV
 SG_ BMS_Max_Ladestrom  : 25|13@1+ (0.200000,0.000000) [0.000000|1630.000000] "Unit_Amper" Motor_BEV
 SG_ BMS_Max_Entladeleistung  : 38|13@1+ (100.000000,0.000000) [0.000000|818000.000000] "Unit_Watt" Motor_BEV
 SG_ BMS_Max_Ladeleistung  : 51|13@1+ (100.000000,0.000000) [0.000000|818000.000000] "Unit_Watt" Motor_BEV

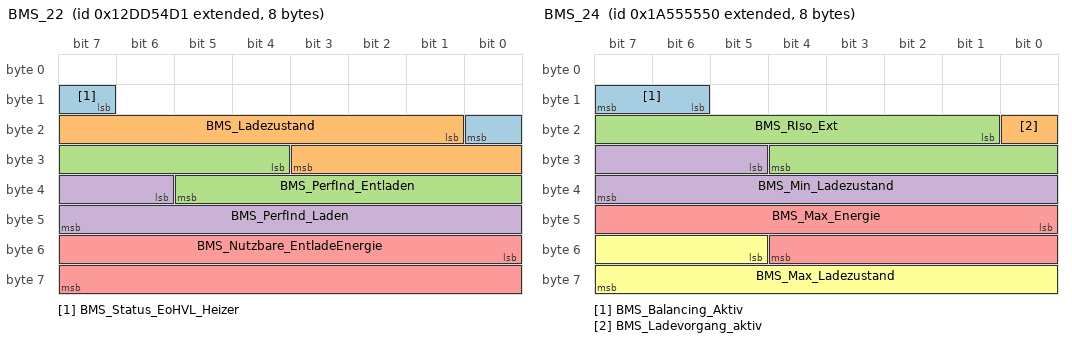
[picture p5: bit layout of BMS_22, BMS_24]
BO_ 2463978705 BMS_22: 8 ICAS1_Gateway
 SG_ BMS_Status_EoHVL_Heizer  : 15|2@1+ (1.000000,0.000000) [0.000000|3.000000] "" Motor_BEV
 SG_ BMS_Ladezustand  : 17|11@1+ (0.050000,0.000000) [0.000000|100.000000] "Unit_PerCent" Motor_BEV
 SG_ BMS_PerfInd_Entladen  : 28|10@1+ (0.200000,0.000000) [0.000000|200.000000] "Unit_PerCent" Motor_BEV
 SG_ BMS_PerfInd_Laden  : 38|10@1+ (0.200000,0.000000) [0.000000|200.000000] "Unit_PerCent" Motor_BEV
 SG_ BMS_Nutzbare_EntladeEnergie  : 48|16@1+ (5.000000,0.000000) [0.000000|327400.000000] "Unit_WattHour" Motor_BEV

BO_ 2589283664 BMS_24: 8 ICAS1_Gateway
 SG_ BMS_Balancing_Aktiv  : 14|2@1+ (1.000000,0.000000) [0.000000|3.000000] "" Vector__XXX
 SG_ BMS_Ladevorgang_aktiv  : 16|1@1+ (1.000000,0.000000) [0.000000|1.000000] "" Vector__XXX
 SG_ BMS_RIso_Ext  : 17|12@1+ (5.000000,0.000000) [0.000000|20465.000000] "Unit_KiloOhm" Motor_BEV
 SG_ BMS_Min_Ladezustand  : 29|11@1+ (0.050000,0.000000) [0.000000|100.000000] "Unit_PerCent" Motor_BEV
 SG_ BMS_Max_Energie  : 40|13@1+ (40.000000,0.000000) [0.000000|327400.000000] "Unit_WattHour" Motor_BEV
 SG_ BMS_Max_Ladezustand  : 53|11@1+ (0.050000,0.000000) [0.000000|100.000000] "Unit_PerCent" Motor_BEV

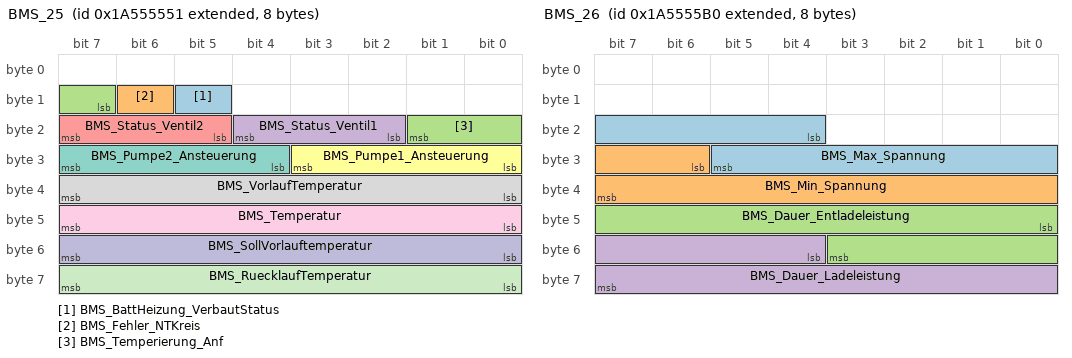
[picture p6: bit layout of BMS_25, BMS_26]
BO_ 2589283665 BMS_25: 8 ICAS1_Gateway
 SG_ BMS_BattHeizung_VerbautStatus  : 13|1@1+ (1.000000,0.000000) [0.000000|1.000000] "" Motor_BEV
 SG_ BMS_Fehler_NTKreis  : 14|1@1+ (1.000000,0.000000) [0.000000|1.000000] "" Vector__XXX
 SG_ BMS_Temperierung_Anf  : 15|3@1+ (1.000000,0.000000) [0.000000|7.000000] "" Motor_BEV
 SG_ BMS_Status_Ventil1  : 18|3@1+ (1.000000,0.000000) [0.000000|7.000000] "" Motor_BEV
 SG_ BMS_Status_Ventil2  : 21|3@1+ (1.000000,0.000000) [0.000000|7.000000] "" Motor_BEV
 SG_ BMS_Pumpe1_Ansteuerung  : 24|4@1+ (10.000000,0.000000) [0.000000|100.000000] "Unit_PerCent" Motor_BEV
 SG_ BMS_Pumpe2_Ansteuerung  : 28|4@1+ (10.000000,0.000000) [0.000000|100.000000] "Unit_PerCent" Motor_BEV
 SG_ BMS_VorlaufTemperatur  : 32|8@1+ (0.500000,-40.000000) [-40.000000|86.000000] "Unit_DegreCelsi" Motor_BEV
 SG_ BMS_Temperatur  : 40|8@1+ (0.500000,-40.000000) [-40.000000|86.500000] "Unit_DegreCelsi" Motor_BEV
 SG_ BMS_SollVorlauftemperatur  : 48|8@1+ (0.500000,-40.000000) [-40.000000|86.500000] "Unit_DegreCelsi" Motor_BEV
 SG_ BMS_RuecklaufTemperatur  : 56|8@1+ (0.500000,-40.000000) [-40.000000|86.000000] "Unit_DegreCelsi" Motor_BEV

BO_ 2589283760 BMS_26: 8 ICAS1_Gateway
 SG_ BMS_Max_Spannung  : 20|10@1+ (1.000000,0.000000) [0.000000|1000.000000] "Unit_Volt" Motor_BEV
 SG_ BMS_Min_Spannung  : 30|10@1+ (1.000000,0.000000) [0.000000|1000.000000] "Unit_Volt" Motor_BEV
 SG_ BMS_Dauer_Entladeleistung  : 40|12@1+ (200.000000,0.000000) [0.000000|818000.000000] "Unit_Watt" Motor_BEV
 SG_ BMS_Dauer_Ladeleistung  : 52|12@1+ (200.000000,0.000000) [0.000000|818000.000000] "Unit_Watt" Motor_BEV

BO_ 2463978646 Charisma_11: 24 ICAS1_Gateway
 SG_ CHA_Ziel_FahrPr_AGA  : 0|4@1+ (1.000000,0.000000) [0.000000|15.000000] "" Vector__XXX
 SG_ CHA_Ziel_FahrPr_ESP  : 4|4@1+ (1.000000,0.000000) [0.000000|15.000000] "" Motor_BEV
 SG_ CHA_Ziel_FahrPr_Freilauf  : 8|4@1+ (1.000000,0.000000) [0.000000|15.000000] "" Vector__XXX
 SG_ CHA_Fahrer_Umschaltung  : 14|1@1+ (1.000000,0.000000) [0.000000|1.000000] "" Motor_BEV
 SG_ CHA_Fahrer_Umschaltung_BMA  : 15|1@1+ (1.000000,0.000000) [0.000000|1.000000] "" Vector__XXX
 SG_ CHA_Ziel_FahrPr_MO  : 16|4@1+ (1.000000,0.000000) [0.000000|15.000000] "" Motor_BEV
 SG_ CHA_Ziel_FahrPr_GE  : 20|4@1+ (1.000000,0.000000) [0.000000|15.000000] "" Vector__XXX
 SG_ CHA_Ziel_FahrPr_ALR  : 24|4@1+ (1.000000,0.000000) [0.000000|15.000000] "" Motor_BEV
 SG_ CHA_Ziel_FahrPr_MO_BZS  : 28|4@1+ (1.000000,0.000000) [0.000000|15.000000] "" Vector__XXX
 SG_ CHA_Ziel_FahrPr_DR  : 32|4@1+ (1.000000,0.000000) [0.000000|15.000000] "" Vector__XXX
 SG_ CHA_Ziel_FahrPr_VAQ  : 36|4@1+ (1.000000,0.000000) [0.000000|15.000000] "" Vector__XXX
 SG_ CHA_Ziel_FahrPr_AFS  : 40|4@1+ (1.000000,0.000000) [0.000000|15.000000] "" Vector__XXX
 SG_ CHA_Ziel_FahrPr_PreCrash  : 44|4@1+ (1.000000,0.000000) [0.000000|15.000000] "" Airbag
 SG_ CHA_Ziel_FahrPr_EPS  : 48|4@1+ (1.000000,0.000000) [0.000000|15.000000] "" Vector__XXX
 SG_ CHA_Ziel_FahrPr_ACC  : 52|4@1+ (1.000000,0.000000) [0.000000|15.000000] "" Vector__XXX
 SG_ CHA_Ziel_FahrPr_SAK  : 56|4@1+ (1.000000,0.000000) [0.000000|15.000000] "" Vector__XXX
 SG_ CHA_Ziel_FahrPr_MO_StSt  : 60|4@1+ (1.000000,0.000000) [0.000000|15.000000] "" Vector__XXX
 SG_ CHA_Ziel_FahrPr_EBKV  : 64|4@1+ (1.000000,0.000000) [0.000000|15.000000] "" Vector__XXX
 SG_ CHA_Ziel_FahrPr_IL  : 68|4@1+ (1.000000,0.000000) [0.000000|15.000000] "" Vector__XXX
 SG_ CHA_Current_Mode  : 72|4@1+ (1.000000,0.000000) [0.000000|15.000000] "" Vector__XXX
 SG_ CHA_Ziel_FahrPr_QS  : 80|4@1+ (1.000000,0.000000) [0.000000|15.000000] "" Vector__XXX
 SG_ CHA_Ziel_FahrPr_SCU  : 84|4@1+ (1.000000,0.000000) [0.000000|15.000000] "" Vector__XXX
 SG_ CHA_Ziel_FahrPr_HAL  : 88|4@1+ (1.000000,0.000000) [0.000000|15.000000] "" Vector__XXX
 SG_ CHA_Ziel_FahrPr_NR  : 92|4@1+ (1.000000,0.000000) [0.000000|15.000000] "" Vector__XXX
 SG_ CHA_Ziel_FahrPr_AV  : 96|4@1+ (1.000000,0.000000) [0.000000|15.000000] "" Vector__XXX
 SG_ CHA_Ziel_FahrPr_MXB  : 100|4@1+ (1.000000,0.000000) [0.000000|15.000000] "" Vector__XXX
 SG_ CHA_Ziel_FahrPr_AFR  : 104|4@1+ (1.000000,0.000000) [0.000000|15.000000] "" Vector__XXX
 SG_ CHA_Ziel_FahrPr_HDC  : 108|4@1+ (1.000000,0.000000) [0.000000|15.000000] "" Vector__XXX
 SG_ CHA_Ziel_FahrPr_EAR  : 112|4@1+ (1.000000,0.000000) [0.000000|15.000000] "" Vector__XXX
 SG_ CHA_Ziel_FahrPr_AEB  : 116|4@1+ (1.000000,0.000000) [0.000000|15.000000] "" Vector__XXX
 SG_ CHA_Ziel_FahrPr_FCWO  : 120|4@1+ (1.000000,0.000000) [0.000000|15.000000] "" Vector__XXX
 SG_ CHA_Ziel_FahrPr_FCWP  : 124|4@1+ (1.000000,0.000000) [0.000000|15.000000] "" Vector__XXX
 SG_ CHA_Ziel_FahrPr_ToS_laengs  : 144|4@1+ (1.000000,0.000000) [0.000000|15.000000] "" Vector__XXX
 SG_ CHA_Ziel_FahrPr_ToS_quer  : 148|4@1+ (1.000000,0.000000) [0.000000|15.000000] "" Vector__XXX
 SG_ CHA_Ziel_FahrPr_mFDR  : 152|4@1+ (1.000000,0.000000) [0.000000|15.000000] "" Vector__XXX
 SG_ CHA_Ziel_FahrPr_Reku_ZwGas  : 156|4@1+ (1.000000,0.000000) [0.000000|15.000000] "" Vector__XXX
 SG_ CHA_Ziel_FahrPr_MO_Freilauf  : 160|4@1+ (1.000000,0.000000) [0.000000|15.000000] "" Vector__XXX
 SG_ CHA_Ziel_FahrPr_BMS  : 164|4@1+ (1.000000,0.000000) [0.000000|15.000000] "" Vector__XXX
 SG_ CHA_Current_Mode_BMA  : 168|4@1+ (1.000000,0.000000) [0.000000|15.000000] "" Vector__XXX
 SG_ CHA_Ziel_FahrPr_PDC  : 172|4@1+ (1.000000,0.000000) [0.000000|15.000000] "" Vector__XXX
 SG_ CHA_Ziel_FahrPr_HHC  : 176|4@1+ (1.000000,0.000000) [0.000000|15.000000] "" Vector__XXX
 SG_ CHA_Ziel_FahrPr_EDS  : 180|4@1+ (1.000000,0.000000) [0.000000|15.000000] "" Vector__XXX
 SG_ CHA_Ziel_FahrPr_PACC  : 184|4@1+ (1.000000,0.000000) [0.000000|15.000000] "" Vector__XXX
 SG_ CHA_Ziel_FahrPr_AGK  : 188|4@1+ (1.000000,0.000000) [0.000000|15.000000] "" Vector__XXX

BO_ 514 Daempfer_03: 32 ICAS1_Gateway
 SG_ DR_Aufbaubeschleunigung_HR  : 12|10@1+ (0.032700,-15.696000) [-15.696000|15.696000] "Unit_MeterPerSeconSquar" Motor_BEV
 SG_ DR_Aufbaubeschleunigung_VR  : 22|10@1+ (0.032700,-15.696000) [-15.696000|15.696000] "Unit_MeterPerSeconSquar" Motor_BEV
 SG_ DR_Aufbaubeschleunigung_VL  : 32|10@1+ (0.032700,-15.696000) [-15.696000|15.696000] "Unit_MeterPerSeconSquar" Motor_BEV
 SG_ DR_Aufbaubeschleunigung_HL  : 42|10@1+ (0.032700,-15.696000) [-15.696000|15.696000] "Unit_MeterPerSeconSquar" Motor_BEV
 SG_ DR_Funktionsstatus  : 52|2@1+ (1.000000,0.000000) [0.000000|3.000000] "" Vector__XXX
 SG_ DR_Drehwinkelsensortausch_VL  : 72|2@1+ (1.000000,0.000000) [1.000000|3.000000] "" Vector__XXX
 SG_ DR_Drehwinkelsensortausch_VR  : 74|2@1+ (1.000000,0.000000) [1.000000|3.000000] "" Vector__XXX
 SG_ DR_Drehwinkelsensortausch_HL  : 76|2@1+ (1.000000,0.000000) [1.000000|3.000000] "" Vector__XXX
 SG_ DR_Drehwinkelsensortausch_HR  : 78|2@1+ (1.000000,0.000000) [1.000000|3.000000] "" Vector__XXX
 SG_ DR_Drehwinkel_VL  : 80|12@1+ (0.088000,0.000000) [0.000000|359.920000] "" Vector__XXX
 SG_ DR_Drehwinkel_VR  : 92|12@1+ (0.088000,0.000000) [0.000000|359.920000] "" Vector__XXX
 SG_ DR_Drehwinkel_HL  : 104|12@1+ (0.088000,0.000000) [0.000000|359.920000] "" Vector__XXX
 SG_ DR_Drehwinkel_HR  : 116|12@1+ (0.088000,0.000000) [0.000000|359.920000] "" Vector__XXX

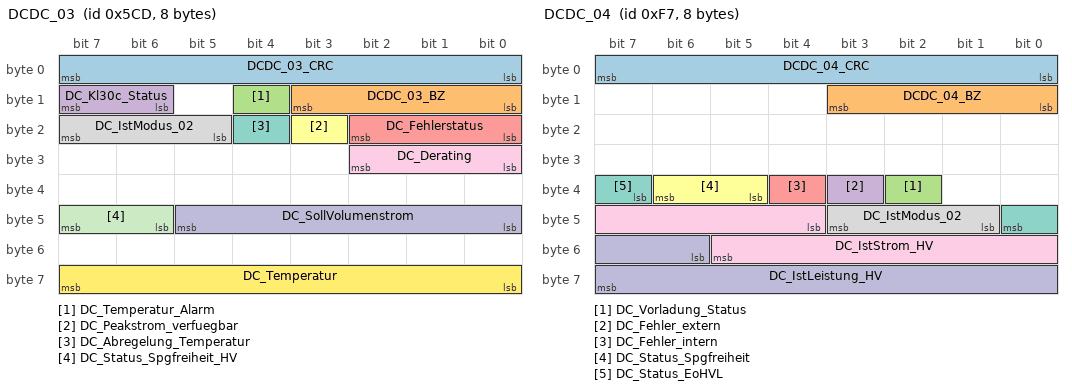
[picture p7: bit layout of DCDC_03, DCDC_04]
BO_ 1485 DCDC_03: 8 ICAS1_Gateway
 SG_ DCDC_03_CRC  : 0|8@1+ (1.000000,0.000000) [0.000000|255.000000] "" Motor_BEV
 SG_ DCDC_03_BZ  : 8|4@1+ (1.000000,0.000000) [0.000000|15.000000] "" Motor_BEV
 SG_ DC_Temperatur_Alarm  : 12|1@1+ (1.000000,0.000000) [0.000000|1.000000] "" Vector__XXX
 SG_ DC_Kl30c_Status  : 14|2@1+ (1.000000,0.000000) [0.000000|3.000000] "" Motor_BEV
 SG_ DC_Fehlerstatus  : 16|3@1+ (1.000000,0.000000) [0.000000|7.000000] "" Vector__XXX
 SG_ DC_Peakstrom_verfuegbar  : 19|1@1+ (1.000000,0.000000) [0.000000|1.000000] "" Vector__XXX
 SG_ DC_Abregelung_Temperatur  : 20|1@1+ (1.000000,0.000000) [0.000000|1.000000] "" Vector__XXX
 SG_ DC_IstModus_02  : 21|3@1+ (1.000000,0.000000) [0.000000|7.000000] "" Vector__XXX
 SG_ DC_Derating  : 24|3@1+ (1.000000,0.000000) [0.000000|7.000000] "" Vector__XXX
 SG_ DC_SollVolumenstrom  : 40|6@1+ (0.500000,0.000000) [0.000000|30.500000] "Unit_LiterPerMinut" Motor_BEV
 SG_ DC_Status_Spgfreiheit_HV  : 46|2@1+ (1.000000,0.000000) [0.000000|3.000000] "" Vector__XXX
 SG_ DC_Temperatur  : 56|8@1+ (1.000000,-40.000000) [-40.000000|213.000000] "Unit_DegreCelsi" Motor_BEV

BO_ 247 DCDC_04: 8 ICAS1_Gateway
 SG_ DCDC_04_CRC  : 0|8@1+ (1.000000,0.000000) [0.000000|255.000000] "" Vector__XXX
 SG_ DCDC_04_BZ  : 8|4@1+ (1.000000,0.000000) [0.000000|15.000000] "" Vector__XXX
 SG_ DC_Vorladung_Status  : 34|1@1+ (1.000000,0.000000) [0.000000|1.000000] "" Motor_BEV
 SG_ DC_Fehler_extern  : 35|1@1+ (1.000000,0.000000) [0.000000|1.000000] "" Motor_BEV
 SG_ DC_Fehler_intern  : 36|1@1+ (1.000000,0.000000) [0.000000|1.000000] "" Motor_BEV
 SG_ DC_Status_Spgfreiheit  : 37|2@1+ (1.000000,0.000000) [0.000000|3.000000] "" Motor_BEV
 SG_ DC_Status_EoHVL  : 39|2@1+ (1.000000,0.000000) [0.000000|3.000000] "" Motor_BEV
 SG_ DC_IstModus_02  : 41|3@1+ (1.000000,0.000000) [0.000000|7.000000] "" Motor_BEV
 SG_ DC_IstStrom_HV  : 44|10@1+ (0.100000,-51.100000) [-51.100000|51.000000] "Unit_Amper" Motor_BEV
 SG_ DC_IstLeistung_HV  : 54|10@1+ (10.000000,-4000.000000) [-4000.000000|6210.000000] "Unit_Watt" Motor_BEV

BO_ 2617027088 DEV_Airbag_ASM_01: 8 Airbag
 SG_ DEV_Airbag_ASM_01_Data  : 0|64@1+ (1.000000,0.000000) [0.000000|18446744073709551616.000000] "" Vector__XXX

BO_ 2617027072 DEV_Airbag_Resp_00: 8 Airbag
 SG_ DEV_Airbag_Resp_00_Data  : 0|64@1+ (1.000000,0.000000) [0.000000|18446744073709551616.000000] "" Vector__XXX

BO_ 2617027073 DEV_Airbag_Resp_01: 8 Airbag
 SG_ DEV_Airbag_Resp_01_Data  : 0|64@1+ (1.000000,0.000000) [0.000000|18446744073709551616.000000] "" Vector__XXX

BO_ 2617027074 DEV_Airbag_Resp_02: 8 Airbag
 SG_ DEV_Airbag_Resp_02_Data  : 0|64@1+ (1.000000,0.000000) [0.000000|18446744073709551616.000000] "" Vector__XXX

BO_ 2617027075 DEV_Airbag_Resp_03: 8 Airbag
 SG_ DEV_Airbag_Resp_03_Data  : 0|64@1+ (1.000000,0.000000) [0.000000|18446744073709551616.000000] "" Vector__XXX

BO_ 2617027076 DEV_Airbag_Resp_04: 8 Airbag
 SG_ DEV_Airbag_Resp_04_Data  : 0|64@1+ (1.000000,0.000000) [0.000000|18446744073709551616.000000] "" Vector__XXX

BO_ 2617027077 DEV_Airbag_Resp_05: 8 Airbag
 SG_ DEV_Airbag_Resp_05_Data  : 0|64@1+ (1.000000,0.000000) [0.000000|18446744073709551616.000000] "" Vector__XXX

BO_ 2617027078 DEV_Airbag_Resp_06: 8 Airbag
 SG_ DEV_Airbag_Resp_06_Data  : 0|64@1+ (1.000000,0.000000) [0.000000|18446744073709551616.000000] "" Vector__XXX

BO_ 2617027079 DEV_Airbag_Resp_07: 8 Airbag
 SG_ DEV_Airbag_Resp_07_Data  : 0|64@1+ (1.000000,0.000000) [0.000000|18446744073709551616.000000] "" Vector__XXX

BO_ 2617027080 DEV_Airbag_Resp_08: 8 Airbag
 SG_ DEV_Airbag_Resp_08_Data  : 0|64@1+ (1.000000,0.000000) [0.000000|18446744073709551616.000000] "" Vector__XXX

BO_ 2617027081 DEV_Airbag_Resp_09: 8 Airbag
 SG_ DEV_Airbag_Resp_09_Data  : 0|64@1+ (1.000000,0.000000) [0.000000|18446744073709551616.000000] "" Vector__XXX

BO_ 2617027082 DEV_Airbag_Resp_10: 8 Airbag
 SG_ DEV_Airbag_Resp_10_Data  : 0|64@1+ (1.000000,0.000000) [0.000000|18446744073709551616.000000] "" Vector__XXX

BO_ 2617027083 DEV_Airbag_Resp_11: 8 Airbag
 SG_ DEV_Airbag_Resp_11_Data  : 0|64@1+ (1.000000,0.000000) [0.000000|18446744073709551616.000000] "" Vector__XXX

BO_ 2617154048 DEV_Waehlhebel_Resp_00: 8 Schaltbetaetigung
 SG_ DEV_Waehlhebel_Resp_00_Data  : 0|64@1+ (1.000000,0.000000) [0.000000|18446744073709551616.000000] "" Vector__XXX

BO_ 2617154049 DEV_Waehlhebel_Resp_01: 8 Schaltbetaetigung
 SG_ DEV_Waehlhebel_Resp_01_Data  : 0|64@1+ (1.000000,0.000000) [0.000000|18446744073709551616.000000] "" Vector__XXX

BO_ 2617154050 DEV_Waehlhebel_Resp_02: 8 Schaltbetaetigung
 SG_ DEV_Waehlhebel_Resp_02_Data  : 0|64@1+ (1.000000,0.000000) [0.000000|18446744073709551616.000000] "" Vector__XXX

BO_ 2617154051 DEV_Waehlhebel_Resp_03: 8 Schaltbetaetigung
 SG_ DEV_Waehlhebel_Resp_03_Data  : 0|64@1+ (1.000000,0.000000) [0.000000|18446744073709551616.000000] "" Vector__XXX

BO_ 2617154052 DEV_Waehlhebel_Resp_04: 8 Schaltbetaetigung
 SG_ DEV_Waehlhebel_Resp_04_Data  : 0|64@1+ (1.000000,0.000000) [0.000000|18446744073709551616.000000] "" Vector__XXX

BO_ 2617154053 DEV_Waehlhebel_Resp_05: 8 Schaltbetaetigung
 SG_ DEV_Waehlhebel_Resp_05_Data  : 0|64@1+ (1.000000,0.000000) [0.000000|18446744073709551616.000000] "" Vector__XXX

BO_ 2549876269 Diag_Waehlhebel_Req: 8 Motor_BEV
 SG_ Diag_Waehlhebel_Req_Data  : 0|64@1+ (1.000000,0.000000) [0.000000|18446744073709551616.000000] "" Schaltbetaetigung

BO_ 2550007341 Diag_Waehlhebel_Resp: 8 Schaltbetaetigung
 SG_ Diag_Waehlhebel_Resp_Data  : 0|64@1+ (1.000000,0.000000) [0.000000|18446744073709551616.000000] "" Motor_BEV

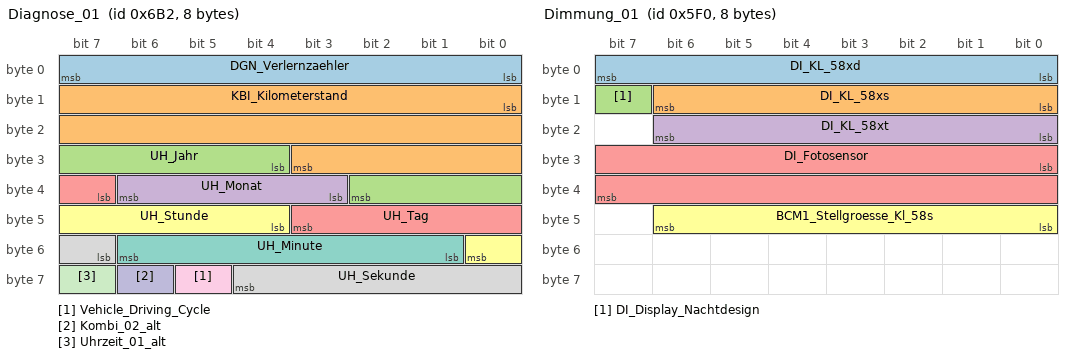
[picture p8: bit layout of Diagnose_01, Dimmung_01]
BO_ 1714 Diagnose_01: 8 ICAS1_Gateway
 SG_ DGN_Verlernzaehler  : 0|8@1+ (1.000000,0.000000) [0.000000|254.000000] "" Airbag LE1 LE2 Motor_BEV
 SG_ KBI_Kilometerstand  : 8|20@1+ (1.000000,0.000000) [0.000000|1048573.000000] "Unit_KiloMeter" Airbag LE1 LE2 Motor_BEV
 SG_ UH_Jahr  : 28|7@1+ (1.000000,2000.000000) [2000.000000|2127.000000] "Unit_Year" Airbag LE1 LE2 Motor_BEV
 SG_ UH_Monat  : 35|4@1+ (1.000000,0.000000) [1.000000|12.000000] "Unit_Month" Airbag LE1 LE2 Motor_BEV
 SG_ UH_Tag  : 39|5@1+ (1.000000,0.000000) [1.000000|31.000000] "Unit_Day" Airbag LE1 LE2 Motor_BEV
 SG_ UH_Stunde  : 44|5@1+ (1.000000,0.000000) [0.000000|23.000000] "Unit_Hours" Airbag LE1 LE2 Motor_BEV
 SG_ UH_Minute  : 49|6@1+ (1.000000,0.000000) [0.000000|59.000000] "Unit_Minut" Airbag LE1 LE2 Motor_BEV
 SG_ UH_Sekunde  : 55|6@1+ (1.000000,0.000000) [0.000000|59.000000] "Unit_Secon" Airbag LE1 LE2 Motor_BEV
 SG_ Vehicle_Driving_Cycle  : 61|1@1+ (1.000000,0.000000) [0.000000|1.000000] "" Airbag
 SG_ Kombi_02_alt  : 62|1@1+ (1.000000,0.000000) [0.000000|1.000000] "" Vector__XXX
 SG_ Uhrzeit_01_alt  : 63|1@1+ (1.000000,0.000000) [0.000000|1.000000] "" Vector__XXX

BO_ 851 DiETa_01: 8 ICAS1_Gateway
 SG_ DiETas_01_CRC  : 0|8@1+ (1.000000,0.000000) [0.000000|255.000000] "" Airbag
 SG_ DiETas_01_BZ  : 8|4@1+ (1.000000,0.000000) [0.000000|15.000000] "" Airbag
 SG_ DiETa_Reserve_Byte2_4  : 12|1@1+ (1.000000,0.000000) [0.000000|1.000000] "" Vector__XXX
 SG_ DiETa_Status  : 13|2@1+ (1.000000,0.000000) [0.000000|3.000000] "" Airbag
 SG_ DiETa_ResponseError  : 15|1@1+ (1.000000,0.000000) [0.000000|1.000000] "" Vector__XXX
 SG_ DiETa_Car  : 16|2@1+ (1.000000,0.000000) [0.000000|3.000000] "" Vector__XXX
 SG_ DiETa_Klima  : 18|2@1+ (1.000000,0.000000) [0.000000|3.000000] "" Vector__XXX
 SG_ DiETa_Mode  : 20|2@1+ (1.000000,0.000000) [0.000000|3.000000] "" Vector__XXX
 SG_ DiETa_Parken  : 22|2@1+ (1.000000,0.000000) [0.000000|3.000000] "" Vector__XXX
 SG_ DiETa_FSH_Taste  : 24|2@1+ (1.000000,0.000000) [0.000000|3.000000] "" Vector__XXX
 SG_ DiETa_HSH_Taste  : 26|2@1+ (1.000000,0.000000) [0.000000|3.000000] "" Vector__XXX
 SG_ DiETa_Warnblink_Taste  : 28|2@1+ (1.000000,0.000000) [0.000000|3.000000] "" Vector__XXX
 SG_ DiETa_FAS_Stufe  : 30|2@1+ (1.000000,0.000000) [0.000000|3.000000] "" Vector__XXX
 SG_ DiETa_PAO_ON_Status  : 32|2@1+ (1.000000,0.000000) [0.000000|3.000000] "" Airbag
 SG_ DiETa_PAO_OFF_Status  : 34|2@1+ (1.000000,0.000000) [0.000000|3.000000] "" Airbag
 SG_ DiETa_Defrost_Taste  : 36|2@1+ (1.000000,0.000000) [0.000000|3.000000] "" Vector__XXX
 SG_ DiETa_Reserve_Byte5_6  : 38|2@1+ (1.000000,0.000000) [0.000000|3.000000] "" Vector__XXX
 SG_ DiETa_Lock_Unlock_Taste  : 40|3@1+ (1.000000,0.000000) [0.000000|7.000000] "" Vector__XXX
 SG_ DiETa_Mode_roh  : 43|1@1+ (1.000000,0.000000) [0.000000|1.000000] "" Vector__XXX
 SG_ DiETa_Reserve_Byte6_3  : 44|4@1+ (1.000000,0.000000) [0.000000|15.000000] "" Vector__XXX
 SG_ DiETa_Reserve_Byte7  : 48|8@1+ (1.000000,0.000000) [0.000000|255.000000] "" Vector__XXX
 SG_ DiETa_Reserve_Byte8  : 56|8@1+ (1.000000,0.000000) [0.000000|255.000000] "" Vector__XXX

BO_ 1520 Dimmung_01: 8 ICAS1_Gateway
 SG_ DI_KL_58xd  : 0|8@1+ (1.000000,0.000000) [0.000000|253.000000] "" Airbag Schaltbetaetigung
 SG_ DI_KL_58xs  : 8|7@1+ (1.000000,0.000000) [0.000000|100.000000] "Unit_PerCent" Airbag
 SG_ DI_Display_Nachtdesign  : 15|1@1+ (1.000000,0.000000) [0.000000|1.000000] "" Vector__XXX
 SG_ DI_KL_58xt  : 16|7@1+ (1.000000,0.000000) [0.000000|100.000000] "Unit_PerCent" Airbag Schaltbetaetigung
 SG_ DI_Fotosensor  : 24|16@1+ (1.000000,0.000000) [0.000000|65535.000000] "" Vector__XXX
 SG_ BCM1_Stellgroesse_Kl_58s  : 40|7@1+ (1.000000,0.000000) [0.000000|100.000000] "" Vector__XXX

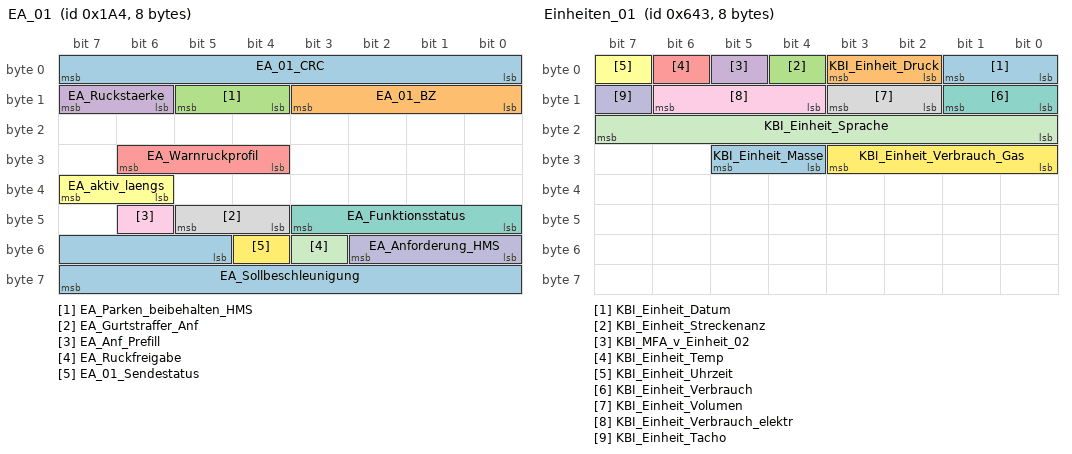
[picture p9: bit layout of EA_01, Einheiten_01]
BO_ 420 EA_01: 8 ICAS1_Gateway
 SG_ EA_01_CRC  : 0|8@1+ (1.000000,0.000000) [0.000000|255.000000] "" Motor_BEV
 SG_ EA_01_BZ  : 8|4@1+ (1.000000,0.000000) [0.000000|15.000000] "" Motor_BEV
 SG_ EA_Parken_beibehalten_HMS  : 12|2@1+ (1.000000,0.000000) [0.000000|3.000000] "" Vector__XXX
 SG_ EA_Ruckstaerke  : 14|2@1+ (1.000000,0.000000) [0.000000|3.000000] "" Vector__XXX
 SG_ EA_Warnruckprofil  : 28|3@1+ (1.000000,0.000000) [0.000000|7.000000] "" Vector__XXX
 SG_ EA_aktiv_laengs  : 38|2@1+ (1.000000,0.000000) [0.000000|3.000000] "" Motor_BEV
 SG_ EA_Funktionsstatus  : 40|4@1+ (1.000000,0.000000) [0.000000|15.000000] "" Motor_BEV
 SG_ EA_Gurtstraffer_Anf  : 44|2@1+ (1.000000,0.000000) [0.000000|3.000000] "" Airbag
 SG_ EA_Anf_Prefill  : 46|1@1+ (1.000000,0.000000) [0.000000|1.000000] "" Vector__XXX
 SG_ EA_Anforderung_HMS  : 48|3@1+ (1.000000,0.000000) [0.000000|7.000000] "" Vector__XXX
 SG_ EA_Ruckfreigabe  : 51|1@1+ (1.000000,0.000000) [0.000000|1.000000] "" Vector__XXX
 SG_ EA_01_Sendestatus  : 52|1@1+ (1.000000,0.000000) [0.000000|1.000000] "" Vector__XXX
 SG_ EA_Sollbeschleunigung  : 53|11@1+ (0.005000,-7.220000) [-7.220000|3.005000] "Unit_MeterPerSeconSquar" Motor_BEV

BO_ 374 EBKV_03: 8 ICAS1_Gateway
 SG_ EBKV_03_CRC  : 0|8@1+ (1.000000,0.000000) [0.000000|255.000000] "" Vector__XXX
 SG_ EBKV_03_BZ  : 8|4@1+ (1.000000,0.000000) [0.000000|15.000000] "" Vector__XXX
 SG_ EBKV_Activate_Fallback_ESP  : 12|1@1+ (1.000000,0.000000) [0.000000|1.000000] "" Vector__XXX
 SG_ EBKV_Restdruckabsenkung  : 13|3@1+ (1.000000,0.000000) [0.000000|7.000000] "" Vector__XXX
 SG_ EBKV_Status_02  : 16|4@1+ (1.000000,0.000000) [0.000000|15.000000] "" Vector__XXX
 SG_ EBKV_Diagnose  : 20|1@1+ (1.000000,0.000000) [0.000000|1.000000] "" Vector__XXX
 SG_ EBKV_Fahrer_bremst  : 21|1@1+ (1.000000,0.000000) [0.000000|1.000000] "" Motor_BEV
 SG_ EBKV_QBit_Fahrer_bremst  : 22|1@1+ (1.000000,0.000000) [0.000000|1.000000] "" Motor_BEV
 SG_ EBKV_Fahrer_bremst_deutlich  : 23|1@1+ (1.000000,0.000000) [0.000000|1.000000] "" Vector__XXX
 SG_ EBKV_OBD_Status  : 24|1@1+ (1.000000,0.000000) [0.000000|1.000000] "" Motor_BEV
 SG_ EBKV_VMM_Sek_Notstopp_Status  : 25|3@1+ (1.000000,0.000000) [0.000000|7.000000] "" Vector__XXX
 SG_ EBKV_Anforderung_HMS  : 28|3@1+ (1.000000,0.000000) [0.000000|7.000000] "" Vector__XXX
 SG_ SBS_Anforderung_GE  : 31|1@1+ (1.000000,0.000000) [0.000000|1.000000] "" Vector__XXX
 SG_ EPB_Status_ext  : 32|3@1+ (1.000000,0.000000) [0.000000|7.000000] "" Motor_BEV
 SG_ EBKV_Bremspedalweg  : 40|8@1+ (0.400000,-0.400000) [0.000000|101.200000] "Unit_PerCent" Motor_BEV
 SG_ EBKV_Kraftblending_Reserve  : 48|8@1+ (0.500000,0.000000) [0.000000|125.000000] "Unit_Bar" Vector__XXX
 SG_ EBKV_Aussteuerdruck  : 56|8@1+ (1.000000,0.000000) [0.000000|250.000000] "Unit_Bar" Vector__XXX

BO_ 1603 Einheiten_01: 8 ICAS1_KommunikationsServer
 SG_ KBI_Einheit_Datum  : 0|2@1+ (1.000000,0.000000) [0.000000|3.000000] "" Vector__XXX
 SG_ KBI_Einheit_Druck  : 2|2@1+ (1.000000,0.000000) [0.000000|3.000000] "" Vector__XXX
 SG_ KBI_Einheit_Streckenanz  : 4|1@1+ (1.000000,0.000000) [0.000000|1.000000] "" Vector__XXX
 SG_ KBI_MFA_v_Einheit_02  : 5|1@1+ (1.000000,0.000000) [0.000000|1.000000] "" Motor_BEV
 SG_ KBI_Einheit_Temp  : 6|1@1+ (1.000000,0.000000) [0.000000|1.000000] "" Vector__XXX
 SG_ KBI_Einheit_Uhrzeit  : 7|1@1+ (1.000000,0.000000) [0.000000|1.000000] "" Vector__XXX
 SG_ KBI_Einheit_Verbrauch  : 8|2@1+ (1.000000,0.000000) [0.000000|3.000000] "" Vector__XXX
 SG_ KBI_Einheit_Volumen  : 10|2@1+ (1.000000,0.000000) [0.000000|3.000000] "" Vector__XXX
 SG_ KBI_Einheit_Verbrauch_elektr  : 12|3@1+ (1.000000,0.000000) [0.000000|7.000000] "" Vector__XXX
 SG_ KBI_Einheit_Tacho  : 15|1@1+ (1.000000,0.000000) [0.000000|1.000000] "" Motor_BEV
 SG_ KBI_Einheit_Sprache  : 16|8@1+ (1.000000,0.000000) [0.000000|255.000000] "" Vector__XXX
 SG_ KBI_Einheit_Verbrauch_Gas  : 24|4@1+ (1.000000,0.000000) [0.000000|15.000000] "" Vector__XXX
 SG_ KBI_Einheit_Masse  : 28|2@1+ (1.000000,0.000000) [0.000000|3.000000] "" Vector__XXX

BO_ 192 EM1_01: 32 LE1
 SG_ EM1_01_CRC  : 0|8@1+ (1.000000,0.000000) [0.000000|255.000000] "" ICAS1_Gateway Motor_BEV
 SG_ EM1_01_BZ  : 8|4@1+ (1.000000,0.000000) [0.000000|15.000000] "" ICAS1_Gateway Motor_BEV
 SG_ EM1_Istmodus  : 12|4@1+ (1.000000,0.000000) [0.000000|15.000000] "" ICAS1_Gateway Motor_BEV
 SG_ EM1_IstMoment  : 16|12@1+ (0.500000,-1023.000000) [-1023.000000|1023.500000] "Unit_NewtoMeter" ICAS1_Gateway Motor_BEV
 SG_ EM1_Moment_AR_Eingriff  : 28|12@1+ (0.500000,-1023.000000) [-1023.000000|1023.500000] "Unit_NewtoMeter" ICAS1_Gateway Motor_BEV
 SG_ EM1_IstDrehzahl  : 40|15@1+ (1.000000,-10000.000000) [-10000.000000|22765.000000] "Unit_MinutInver" ICAS1_Gateway Motor_BEV
 SG_ EM1_AR_aktiv  : 55|1@1+ (1.000000,0.000000) [0.000000|1.000000] "" ICAS1_Gateway Motor_BEV
 SG_ EM1_IstSpannung  : 56|12@1+ (0.250000,0.000000) [0.000000|1023.250000] "Unit_Volt" ICAS1_Gateway Motor_BEV
 SG_ EM1_Strom_HV  : 68|12@1+ (0.500000,-1023.000000) [-1023.000000|1023.500000] "Unit_Amper" ICAS1_Gateway Motor_BEV
 SG_ EM1_Max_Moment  : 80|11@1+ (1.000000,-1023.000000) [-1023.000000|1022.000000] "Unit_NewtoMeter" ICAS1_Gateway Motor_BEV
 SG_ EM1_ErwGrenzen_aktiv  : 91|1@1+ (1.000000,0.000000) [0.000000|1.000000] "" ICAS1_Gateway Motor_BEV
 SG_ EM1_Min_Moment  : 92|11@1+ (1.000000,-1023.000000) [-1023.000000|1022.000000] "Unit_NewtoMeter" ICAS1_Gateway Motor_BEV
 SG_ EM1_Fehler_ElAntriebAbschaltung  : 103|1@1+ (1.000000,0.000000) [0.000000|1.000000] "" ICAS1_Gateway Motor_BEV
 SG_ EM1_Max_Moment_Lim  : 104|11@1+ (1.000000,-1023.000000) [-1023.000000|1022.000000] "Unit_NewtoMeter" ICAS1_Gateway Motor_BEV
 SG_ EM1_Fehler_Notabschaltung  : 115|1@1+ (1.000000,0.000000) [0.000000|1.000000] "" ICAS1_Gateway Motor_BEV
 SG_ EM1_Min_Moment_Lim  : 116|11@1+ (1.000000,-1023.000000) [-1023.000000|1022.000000] "Unit_NewtoMeter" ICAS1_Gateway Motor_BEV
 SG_ EM1_Status_DrzEingriff  : 127|2@1+ (1.000000,0.000000) [0.000000|3.000000] "" ICAS1_Gateway Motor_BEV
 SG_ EM1_Mom_DrzEingriff  : 129|11@1+ (1.000000,-1023.000000) [-1023.000000|1022.000000] "Unit_NewtoMeter" ICAS1_Gateway Motor_BEV

BO_ 2463978673 EM1_02: 32 LE1
 SG_ EM1_Status_Spgfreiheit  : 12|2@1+ (1.000000,0.000000) [0.000000|3.000000] "" Motor_BEV
 SG_ EM1_Status_EoHVL  : 14|2@1+ (1.000000,0.000000) [0.000000|3.000000] "" Motor_BEV
 SG_ EM1_Max_LeistungMech_Sockel  : 16|13@1+ (200.000000,-819000.000000) [-819000.000000|818800.000000] "Unit_Watt" Vector__XXX
 SG_ EM1_Max_Moment_Sockel  : 29|11@1+ (1.000000,-1023.000000) [-1023.000000|1022.000000] "Unit_NewtoMeter" Vector__XXX
 SG_ EM1_Min_LeistungMech_Sockel  : 40|13@1+ (200.000000,-819000.000000) [-819000.000000|818800.000000] "Unit_Watt" Vector__XXX
 SG_ EM1_Min_Moment_Sockel  : 53|11@1+ (1.000000,-1023.000000) [-1023.000000|1022.000000] "Unit_NewtoMeter" Vector__XXX
 SG_ EM1_PerfInd_MaxLeistung  : 64|10@1+ (0.200000,0.000000) [0.000000|200.000000] "Unit_PerCent" Motor_BEV
 SG_ EM1_PerfInd_MaxMoment  : 74|10@1+ (0.200000,0.000000) [0.000000|200.000000] "Unit_PerCent" Motor_BEV
 SG_ EM1_AnlernenElMotor_Anf  : 84|1@1+ (1.000000,0.000000) [0.000000|1.000000] "" Motor_BEV
 SG_ EM1_OBD_Lampe_Anf  : 85|1@1+ (1.000000,0.000000) [0.000000|1.000000] "" Motor_BEV
 SG_ EM1_Generator_Moment  : 86|10@1+ (1.000000,0.000000) [0.000000|1021.000000] "Unit_NewtoMeter" Motor_BEV
 SG_ EM1_PerfInd_Temperatur  : 96|8@1+ (0.800000,0.000000) [0.000000|200.000000] "Unit_PerCent" Motor_BEV
 SG_ EM1_MaxZul_Drehzahl  : 104|8@1+ (80.000000,0.000000) [0.000000|20240.000000] "Unit_RevPerMinute" Motor_BEV
 SG_ EM1_Min_Moment_Gesamt  : 112|11@1+ (1.000000,-1023.000000) [-1023.000000|1022.000000] "Unit_NewtoMeter" Motor_BEV
 SG_ EM1_Fehlerlampe_Anf  : 123|1@1+ (1.000000,0.000000) [0.000000|1.000000] "" Motor_BEV
 SG_ EM1_Max_Moment_Gesamt  : 124|11@1+ (1.000000,-1023.000000) [-1023.000000|1022.000000] "Unit_NewtoMeter" Motor_BEV
 SG_ EM1_Warnlampe_Anf  : 135|1@1+ (1.000000,0.000000) [0.000000|1.000000] "" Motor_BEV
 SG_ EM1_Rekuperation  : 136|15@1+ (10.000000,0.000000) [0.000000|327670.000000] "Unit_WattSecond" Motor_BEV
 SG_ EM1_Rekuperation_Ueberlauf  : 151|1@1+ (1.000000,0.000000) [0.000000|1.000000] "" Motor_BEV
 SG_ EM1_Verbrauch  : 152|15@1+ (10.000000,0.000000) [0.000000|327670.000000] "Unit_WattSecond" Motor_BEV
 SG_ EM1_Verbrauch_Ueberlauf  : 167|1@1+ (1.000000,0.000000) [0.000000|1.000000] "" Motor_BEV
 SG_ EM1_Fehler_AE  : 168|1@1+ (1.000000,0.000000) [0.000000|1.000000] "" Motor_BEV
 SG_ EM1_Fehler_Leistungsred  : 169|1@1+ (1.000000,0.000000) [0.000000|1.000000] "" Motor_BEV
 SG_ EM1_Fehler_ElAntriebFreilauf  : 170|1@1+ (1.000000,0.000000) [0.000000|1.000000] "" Motor_BEV
 SG_ EM1_PWR_SollVolumenstrom  : 171|6@1+ (0.500000,0.000000) [0.000000|30.500000] "Unit_LiterPerMinut" Motor_BEV

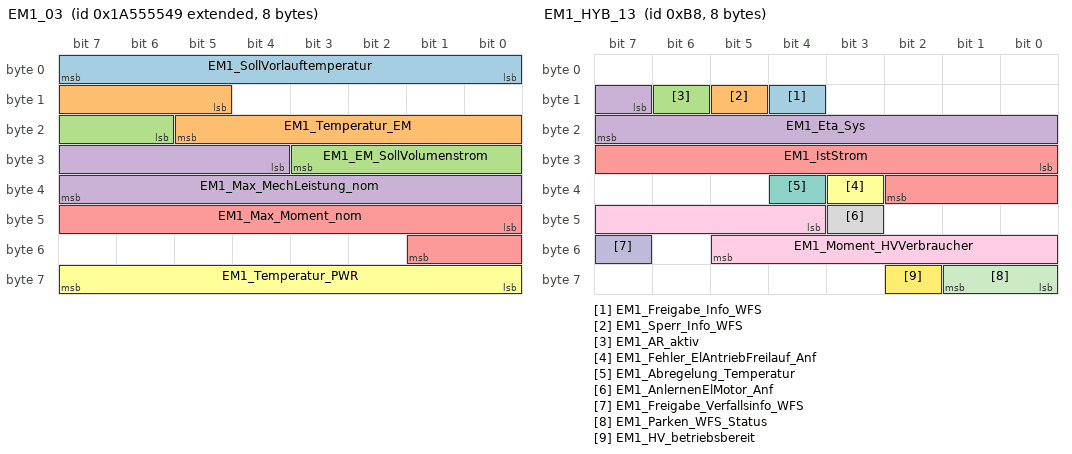
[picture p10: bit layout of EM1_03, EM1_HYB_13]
BO_ 2589283657 EM1_03: 8 LE1
 SG_ EM1_SollVorlauftemperatur  : 0|8@1+ (0.500000,-40.000000) [-40.000000|86.500000] "Unit_DegreCelsi" Motor_BEV
 SG_ EM1_Temperatur_EM  : 13|9@1+ (1.000000,-40.000000) [-40.000000|469.000000] "Unit_DegreCelsi" ICAS1_Gateway Motor_BEV
 SG_ EM1_EM_SollVolumenstrom  : 22|6@1+ (0.500000,0.000000) [0.000000|30.500000] "Unit_LiterPerMinut" Motor_BEV
 SG_ EM1_Max_MechLeistung_nom  : 28|12@1+ (200.000000,0.000000) [0.000000|818600.000000] "Unit_Watt" Motor_BEV
 SG_ EM1_Max_Moment_nom  : 40|10@1+ (1.000000,0.000000) [0.000000|1021.000000] "Unit_NewtoMeter" Motor_BEV
 SG_ EM1_Temperatur_PWR  : 56|8@1+ (1.000000,-40.000000) [-40.000000|213.000000] "Unit_DegreCelsi" ICAS1_Gateway Motor_BEV

BO_ 184 EM1_HYB_13: 8 LE1
 SG_ EM1_Freigabe_Info_WFS  : 12|1@1+ (1.000000,0.000000) [0.000000|1.000000] "" ICAS1_Gateway Motor_BEV
 SG_ EM1_Sperr_Info_WFS  : 13|1@1+ (1.000000,0.000000) [0.000000|1.000000] "" ICAS1_Gateway Motor_BEV
 SG_ EM1_AR_aktiv  : 14|1@1+ (1.000000,0.000000) [0.000000|1.000000] "" ICAS1_Gateway
 SG_ EM1_Eta_Sys  : 15|9@1+ (0.200000,0.000000) [0.000000|101.800000] "Unit_PerCent" ICAS1_Gateway
 SG_ EM1_IstStrom  : 24|11@1+ (1.000000,-1023.000000) [-1023.000000|1022.000000] "Unit_Amper" ICAS1_Gateway
 SG_ EM1_Fehler_ElAntriebFreilauf_Anf  : 35|1@1+ (1.000000,0.000000) [0.000000|1.000000] "" ICAS1_Gateway
 SG_ EM1_Abregelung_Temperatur  : 36|1@1+ (1.000000,0.000000) [0.000000|1.000000] "" ICAS1_Gateway
 SG_ EM1_AnlernenElMotor_Anf  : 43|1@1+ (1.000000,0.000000) [0.000000|1.000000] "" ICAS1_Gateway
 SG_ EM1_Moment_HVVerbraucher  : 44|10@1+ (1.000000,-511.000000) [-511.000000|511.000000] "Unit_NewtoMeter" ICAS1_Gateway
 SG_ EM1_Freigabe_Verfallsinfo_WFS  : 55|1@1+ (1.000000,0.000000) [0.000000|1.000000] "" ICAS1_Gateway Motor_BEV
 SG_ EM1_Parken_WFS_Status  : 56|2@1+ (1.000000,0.000000) [0.000000|3.000000] "" ICAS1_Gateway
 SG_ EM1_HV_betriebsbereit  : 58|1@1+ (1.000000,0.000000) [0.000000|1.000000] "" ICAS1_Gateway

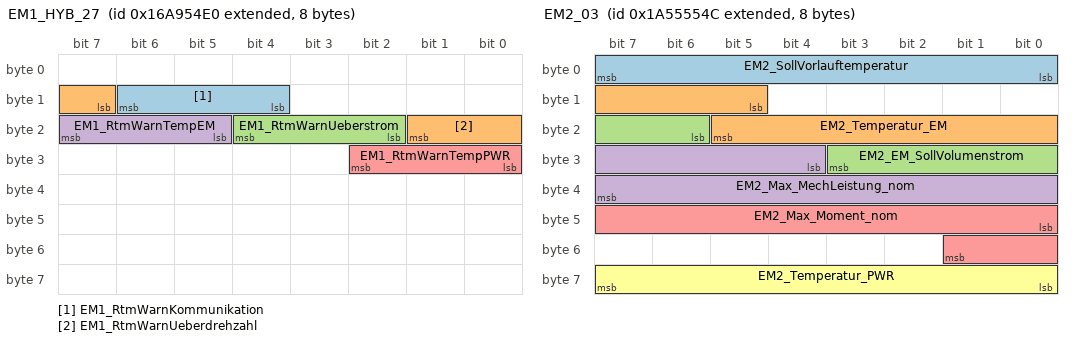
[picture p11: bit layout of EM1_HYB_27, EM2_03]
BO_ 2527679712 EM1_HYB_27: 8 LE1
 SG_ EM1_RtmWarnKommunikation  : 12|3@1+ (1.000000,0.000000) [0.000000|7.000000] "" Vector__XXX
 SG_ EM1_RtmWarnUeberdrehzahl  : 15|3@1+ (1.000000,0.000000) [0.000000|7.000000] "" ICAS1_Gateway
 SG_ EM1_RtmWarnUeberstrom  : 18|3@1+ (1.000000,0.000000) [0.000000|7.000000] "" ICAS1_Gateway
 SG_ EM1_RtmWarnTempEM  : 21|3@1+ (1.000000,0.000000) [0.000000|7.000000] "" ICAS1_Gateway
 SG_ EM1_RtmWarnTempPWR  : 24|3@1+ (1.000000,0.000000) [0.000000|7.000000] "" ICAS1_Gateway

BO_ 193 EM2_01: 32 LE2
 SG_ EM2_01_CRC  : 0|8@1+ (1.000000,0.000000) [0.000000|255.000000] "" Motor_BEV
 SG_ EM2_01_BZ  : 8|4@1+ (1.000000,0.000000) [0.000000|15.000000] "" Motor_BEV
 SG_ EM2_Istmodus  : 12|4@1+ (1.000000,0.000000) [0.000000|15.000000] "" ICAS1_Gateway Motor_BEV
 SG_ EM2_IstMoment  : 16|12@1+ (0.500000,-1023.000000) [-1023.000000|1023.500000] "Unit_NewtoMeter" ICAS1_Gateway Motor_BEV
 SG_ EM2_Moment_AR_Eingriff  : 28|12@1+ (0.500000,-1023.000000) [-1023.000000|1023.500000] "Unit_NewtoMeter" Motor_BEV
 SG_ EM2_IstDrehzahl  : 40|15@1+ (1.000000,-10000.000000) [-10000.000000|22765.000000] "Unit_MinutInver" ICAS1_Gateway Motor_BEV
 SG_ EM2_AR_aktiv  : 55|1@1+ (1.000000,0.000000) [0.000000|1.000000] "" Motor_BEV
 SG_ EM2_IstSpannung  : 56|12@1+ (0.250000,0.000000) [0.000000|1023.250000] "Unit_Volt" ICAS1_Gateway Motor_BEV
 SG_ EM2_Strom_HV  : 68|12@1+ (0.500000,-1023.000000) [-1023.000000|1023.500000] "Unit_Amper" ICAS1_Gateway Motor_BEV
 SG_ EM2_Max_Moment  : 80|11@1+ (1.000000,-1023.000000) [-1023.000000|1022.000000] "Unit_NewtoMeter" Motor_BEV
 SG_ EM2_ErwGrenzen_aktiv  : 91|1@1+ (1.000000,0.000000) [0.000000|1.000000] "" Motor_BEV
 SG_ EM2_Min_Moment  : 92|11@1+ (1.000000,-1023.000000) [-1023.000000|1022.000000] "Unit_NewtoMeter" Motor_BEV
 SG_ EM2_Fehler_ElAntriebAbschaltung  : 103|1@1+ (1.000000,0.000000) [0.000000|1.000000] "" Motor_BEV
 SG_ EM2_Max_Moment_Lim  : 104|11@1+ (1.000000,-1023.000000) [-1023.000000|1022.000000] "Unit_NewtoMeter" Motor_BEV
 SG_ EM2_Fehler_Notabschaltung  : 115|1@1+ (1.000000,0.000000) [0.000000|1.000000] "" ICAS1_Gateway Motor_BEV
 SG_ EM2_Min_Moment_Lim  : 116|11@1+ (1.000000,-1023.000000) [-1023.000000|1022.000000] "Unit_NewtoMeter" Motor_BEV
 SG_ EM2_Status_DrzEingriff  : 127|2@1+ (1.000000,0.000000) [0.000000|3.000000] "" ICAS1_Gateway Motor_BEV
 SG_ EM2_Mom_DrzEingriff  : 129|11@1+ (1.000000,-1023.000000) [-1023.000000|1022.000000] "Unit_NewtoMeter" Motor_BEV

BO_ 2463978674 EM2_02: 32 LE2
 SG_ EM2_Status_Spgfreiheit  : 12|2@1+ (1.000000,0.000000) [0.000000|3.000000] "" Motor_BEV
 SG_ EM2_Status_EoHVL  : 14|2@1+ (1.000000,0.000000) [0.000000|3.000000] "" Motor_BEV
 SG_ EM2_Max_LeistungMech_Sockel  : 16|13@1+ (200.000000,-819000.000000) [-819000.000000|818800.000000] "Unit_Watt" Vector__XXX
 SG_ EM2_Max_Moment_Sockel  : 29|11@1+ (1.000000,-1023.000000) [-1023.000000|1022.000000] "Unit_NewtoMeter" Vector__XXX
 SG_ EM2_Min_LeistungMech_Sockel  : 40|13@1+ (200.000000,-819000.000000) [-819000.000000|818800.000000] "Unit_Watt" Vector__XXX
 SG_ EM2_Min_Moment_Sockel  : 53|11@1+ (1.000000,-1023.000000) [-1023.000000|1022.000000] "Unit_NewtoMeter" Vector__XXX
 SG_ EM2_PerfInd_MaxLeistung  : 64|10@1+ (0.200000,0.000000) [0.000000|200.000000] "Unit_PerCent" Motor_BEV
 SG_ EM2_PerfInd_MaxMoment  : 74|10@1+ (0.200000,0.000000) [0.000000|200.000000] "Unit_PerCent" Motor_BEV
 SG_ EM2_AnlernenElMotor_Anf  : 84|1@1+ (1.000000,0.000000) [0.000000|1.000000] "" Motor_BEV
 SG_ EM2_OBD_Lampe_Anf  : 85|1@1+ (1.000000,0.000000) [0.000000|1.000000] "" Motor_BEV
 SG_ EM2_Generator_Moment  : 86|10@1+ (1.000000,0.000000) [0.000000|1021.000000] "Unit_NewtoMeter" Motor_BEV
 SG_ EM2_PerfInd_Temperatur  : 96|8@1+ (0.800000,0.000000) [0.000000|200.000000] "Unit_PerCent" Motor_BEV
 SG_ EM2_MaxZul_Drehzahl  : 104|8@1+ (80.000000,0.000000) [0.000000|20240.000000] "Unit_RevPerMinute" Motor_BEV
 SG_ EM2_Min_Moment_Gesamt  : 112|11@1+ (1.000000,-1023.000000) [-1023.000000|1022.000000] "Unit_NewtoMeter" Motor_BEV
 SG_ EM2_Fehlerlampe_Anf  : 123|1@1+ (1.000000,0.000000) [0.000000|1.000000] "" Motor_BEV
 SG_ EM2_Max_Moment_Gesamt  : 124|11@1+ (1.000000,-1023.000000) [-1023.000000|1022.000000] "Unit_NewtoMeter" Motor_BEV
 SG_ EM2_Warnlampe_Anf  : 135|1@1+ (1.000000,0.000000) [0.000000|1.000000] "" Motor_BEV
 SG_ EM2_Rekuperation  : 136|15@1+ (10.000000,0.000000) [0.000000|327670.000000] "Unit_WattSecond" Motor_BEV
 SG_ EM2_Rekuperation_Ueberlauf  : 151|1@1+ (1.000000,0.000000) [0.000000|1.000000] "" Motor_BEV
 SG_ EM2_Verbrauch  : 152|15@1+ (10.000000,0.000000) [0.000000|327670.000000] "Unit_WattSecond" Motor_BEV
 SG_ EM2_Verbrauch_Ueberlauf  : 167|1@1+ (1.000000,0.000000) [0.000000|1.000000] "" Motor_BEV
 SG_ EM2_Fehler_AE  : 168|1@1+ (1.000000,0.000000) [0.000000|1.000000] "" Motor_BEV
 SG_ EM2_Fehler_Leistungsred  : 169|1@1+ (1.000000,0.000000) [0.000000|1.000000] "" Motor_BEV
 SG_ EM2_Fehler_ElAntriebFreilauf  : 170|1@1+ (1.000000,0.000000) [0.000000|1.000000] "" Motor_BEV
 SG_ EM2_PWR_SollVolumenstrom  : 171|6@1+ (0.500000,0.000000) [0.000000|30.500000] "Unit_LiterPerMinut" Motor_BEV

BO_ 2589283660 EM2_03: 8 LE2
 SG_ EM2_SollVorlauftemperatur  : 0|8@1+ (0.500000,-40.000000) [-40.000000|86.500000] "Unit_DegreCelsi" Motor_BEV
 SG_ EM2_Temperatur_EM  : 13|9@1+ (1.000000,-40.000000) [-40.000000|469.000000] "Unit_DegreCelsi" ICAS1_Gateway Motor_BEV
 SG_ EM2_EM_SollVolumenstrom  : 22|6@1+ (0.500000,0.000000) [0.000000|30.500000] "Unit_LiterPerMinut" Motor_BEV
 SG_ EM2_Max_MechLeistung_nom  : 28|12@1+ (200.000000,0.000000) [0.000000|818600.000000] "Unit_Watt" Motor_BEV
 SG_ EM2_Max_Moment_nom  : 40|10@1+ (1.000000,0.000000) [0.000000|1021.000000] "Unit_NewtoMeter" Motor_BEV
 SG_ EM2_Temperatur_PWR  : 56|8@1+ (1.000000,-40.000000) [-40.000000|213.000000] "Unit_DegreCelsi" ICAS1_Gateway Motor_BEV

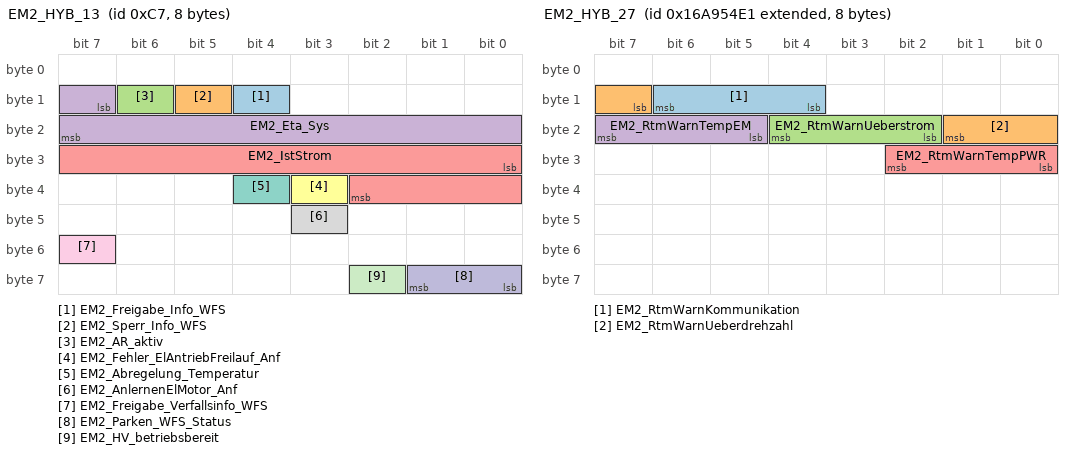
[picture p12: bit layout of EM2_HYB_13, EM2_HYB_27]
BO_ 199 EM2_HYB_13: 8 LE2
 SG_ EM2_Freigabe_Info_WFS  : 12|1@1+ (1.000000,0.000000) [0.000000|1.000000] "" ICAS1_Gateway Motor_BEV
 SG_ EM2_Sperr_Info_WFS  : 13|1@1+ (1.000000,0.000000) [0.000000|1.000000] "" ICAS1_Gateway Motor_BEV
 SG_ EM2_AR_aktiv  : 14|1@1+ (1.000000,0.000000) [0.000000|1.000000] "" ICAS1_Gateway
 SG_ EM2_Eta_Sys  : 15|9@1+ (0.200000,0.000000) [0.000000|101.800000] "Unit_PerCent" ICAS1_Gateway
 SG_ EM2_IstStrom  : 24|11@1+ (1.000000,-1023.000000) [-1023.000000|1022.000000] "Unit_Amper" ICAS1_Gateway
 SG_ EM2_Fehler_ElAntriebFreilauf_Anf  : 35|1@1+ (1.000000,0.000000) [0.000000|1.000000] "" ICAS1_Gateway
 SG_ EM2_Abregelung_Temperatur  : 36|1@1+ (1.000000,0.000000) [0.000000|1.000000] "" ICAS1_Gateway
 SG_ EM2_AnlernenElMotor_Anf  : 43|1@1+ (1.000000,0.000000) [0.000000|1.000000] "" ICAS1_Gateway
 SG_ EM2_Freigabe_Verfallsinfo_WFS  : 55|1@1+ (1.000000,0.000000) [0.000000|1.000000] "" ICAS1_Gateway Motor_BEV
 SG_ EM2_Parken_WFS_Status  : 56|2@1+ (1.000000,0.000000) [0.000000|3.000000] "" ICAS1_Gateway
 SG_ EM2_HV_betriebsbereit  : 58|1@1+ (1.000000,0.000000) [0.000000|1.000000] "" ICAS1_Gateway

BO_ 2527679713 EM2_HYB_27: 8 LE2
 SG_ EM2_RtmWarnKommunikation  : 12|3@1+ (1.000000,0.000000) [0.000000|7.000000] "" Vector__XXX
 SG_ EM2_RtmWarnUeberdrehzahl  : 15|3@1+ (1.000000,0.000000) [0.000000|7.000000] "" ICAS1_Gateway
 SG_ EM2_RtmWarnUeberstrom  : 18|3@1+ (1.000000,0.000000) [0.000000|7.000000] "" ICAS1_Gateway
 SG_ EM2_RtmWarnTempEM  : 21|3@1+ (1.000000,0.000000) [0.000000|7.000000] "" ICAS1_Gateway
 SG_ EM2_RtmWarnTempPWR  : 24|3@1+ (1.000000,0.000000) [0.000000|7.000000] "" ICAS1_Gateway

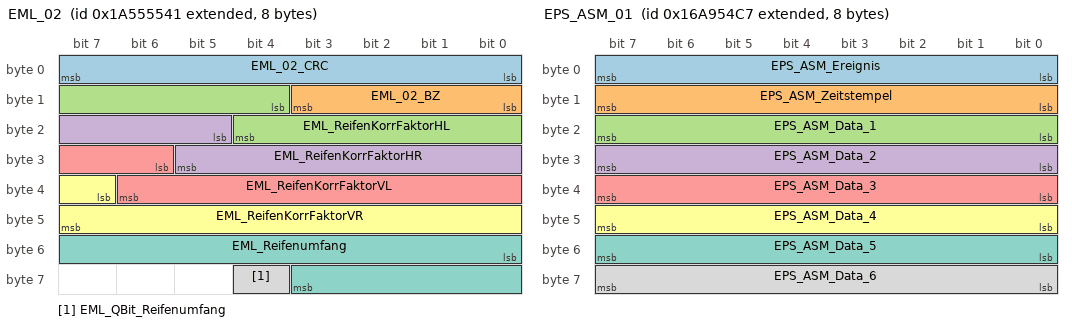
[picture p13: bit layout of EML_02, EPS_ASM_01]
BO_ 2589283649 EML_02: 8 ICAS1_Gateway
 SG_ EML_02_CRC  : 0|8@1+ (1.000000,0.000000) [0.000000|255.000000] "" Vector__XXX
 SG_ EML_02_BZ  : 8|4@1+ (1.000000,0.000000) [0.000000|15.000000] "" Vector__XXX
 SG_ EML_ReifenKorrFaktorHL  : 12|9@1+ (0.000488,0.850000) [0.850000|1.098535] "" Vector__XXX
 SG_ EML_ReifenKorrFaktorHR  : 21|9@1+ (0.000488,0.850000) [0.850000|1.098535] "" Vector__XXX
 SG_ EML_ReifenKorrFaktorVL  : 30|9@1+ (0.000488,0.850000) [0.850000|1.098535] "" Vector__XXX
 SG_ EML_ReifenKorrFaktorVR  : 39|9@1+ (0.000488,0.850000) [0.850000|1.098535] "" Vector__XXX
 SG_ EML_Reifenumfang  : 48|12@1+ (1.000000,0.000000) [0.000000|4095.000000] "Unit_MilliMeter" Motor_BEV
 SG_ EML_QBit_Reifenumfang  : 60|1@1+ (1.000000,0.000000) [0.000000|1.000000] "" Motor_BEV

BO_ 608 EML_07: 8 ICAS1_Gateway
 SG_ EML_AnzeigeGeschw  : 54|10@1+ (0.320000,0.000000) [0.000000|325.120000] "Unit_KiloMeterPerHour" Motor_BEV

BO_ 2589283751 Entfernungen_01: 8 ICAS1_KommunikationsServer
 SG_ KBI_Kilometerstand_HiRes_meter  : 32|32@1+ (1.000000,0.000000) [0.000000|4294967295.000000] "Unit_Meter" Motor_BEV

BO_ 2527679687 EPS_ASM_01: 8 ICAS1_Gateway
 SG_ EPS_ASM_Ereignis  : 0|8@1+ (1.000000,0.000000) [1.000000|254.000000] "Unit_None" Airbag
 SG_ EPS_ASM_Zeitstempel  : 8|8@1+ (0.080000,0.000000) [0.000000|20.320000] "Unit_None" Airbag
 SG_ EPS_ASM_Data_1  : 16|8@1+ (1.000000,0.000000) [0.000000|255.000000] "Unit_None" Airbag
 SG_ EPS_ASM_Data_2  : 24|8@1+ (1.000000,0.000000) [0.000000|255.000000] "Unit_None" Airbag
 SG_ EPS_ASM_Data_3  : 32|8@1+ (1.000000,0.000000) [0.000000|255.000000] "Unit_None" Airbag
 SG_ EPS_ASM_Data_4  : 40|8@1+ (1.000000,0.000000) [0.000000|255.000000] "Unit_None" Airbag
 SG_ EPS_ASM_Data_5  : 48|8@1+ (1.000000,0.000000) [0.000000|255.000000] "Unit_None" Airbag
 SG_ EPS_ASM_Data_6  : 56|8@1+ (1.000000,0.000000) [0.000000|255.000000] "Unit_None" Airbag

BO_ 258 ESC_50: 48 ICAS1_Gateway
 SG_ ESC_50_CRC  : 0|8@1+ (1.000000,0.000000) [0.000000|255.000000] "" Motor_BEV
 SG_ ESC_50_BZ  : 8|4@1+ (1.000000,0.000000) [0.000000|15.000000] "" Motor_BEV
 SG_ ESP_QBit_Gierrate  : 12|1@1+ (1.000000,0.000000) [0.000000|1.000000] "" Motor_BEV
 SG_ ESP_QBit_Laengsbeschl  : 13|1@1+ (1.000000,0.000000) [0.000000|1.000000] "" Motor_BEV
 SG_ ESP_QBit_Querb  : 14|1@1+ (1.000000,0.000000) [0.000000|1.000000] "" Motor_BEV
 SG_ ESP_Querbeschleunigung  : 16|8@1+ (0.010000,-1.270000) [-1.270000|1.270000] "Unit_ForceOfGravi" Airbag Motor_BEV
 SG_ ESP_Laengsbeschl  : 24|10@1+ (0.031250,-16.000000) [-16.000000|15.906250] "Unit_MeterPerSeconSquar" Airbag Motor_BEV
 SG_ ESC_Motorstartverzoegerung  : 34|1@1+ (1.000000,0.000000) [0.000000|1.000000] "" Vector__XXX
 SG_ ESC_SeitenwindAssistent_Eingriff  : 35|1@1+ (1.000000,0.000000) [0.000000|1.000000] "" Vector__XXX
 SG_ ESP_Anschleppstart_Freigabe  : 36|2@1+ (1.000000,0.000000) [0.000000|3.000000] "" Vector__XXX
 SG_ ESC_Unterdruckmangel_erkannt  : 38|1@1+ (1.000000,0.000000) [0.000000|1.000000] "" Vector__XXX
 SG_ ESP_Gierrate  : 40|14@1+ (0.010000,0.000000) [0.000000|163.820000] "Unit_DegreOfArcPerSecon" Airbag Motor_BEV
 SG_ ESP_VZ_Gierrate  : 54|1@1+ (1.000000,0.000000) [0.000000|1.000000] "" Airbag Motor_BEV
 SG_ ESP_Notbremsanzeige  : 55|1@1+ (1.000000,0.000000) [0.000000|1.000000] "" Vector__XXX
 SG_ ESP_SpannungsAnf  : 56|1@1+ (1.000000,0.000000) [0.000000|1.000000] "" Vector__XXX
 SG_ ESP_PLA_Abbruch  : 57|3@1+ (1.000000,0.000000) [0.000000|7.000000] "" Vector__XXX
 SG_ ESP_Status_ESP_PLA  : 60|4@1+ (1.000000,0.000000) [0.000000|15.000000] "" Vector__XXX
 SG_ ESP_QBit_Bremsdruck  : 76|1@1+ (1.000000,0.000000) [0.000000|1.000000] "" Airbag Motor_BEV
 SG_ ESP_QBit_Fahrer_bremst  : 77|1@1+ (1.000000,0.000000) [0.000000|1.000000] "" Vector__XXX
 SG_ ESP_Schwelle_Unterdruck  : 78|2@1+ (1.000000,0.000000) [0.000000|3.000000] "" Vector__XXX
 SG_ ESP_Bremsdruck  : 80|10@1+ (0.300000,-30.000000) [-30.000000|276.600000] "Unit_Bar" Motor_BEV
 SG_ ESP_Fahrer_bremst  : 90|1@1+ (1.000000,0.000000) [0.000000|1.000000] "" Vector__XXX
 SG_ ESP_Verz_TSK_aktiv  : 91|1@1+ (1.000000,0.000000) [0.000000|1.000000] "" Vector__XXX
 SG_ ESP_Lenkeingriff_ADS  : 92|1@1+ (1.000000,0.000000) [0.000000|1.000000] "" Vector__XXX
 SG_ ESP_Konsistenz_TSK  : 93|1@1+ (1.000000,0.000000) [0.000000|1.000000] "" Vector__XXX
 SG_ ESP_Bremsruck_AWV2  : 94|1@1+ (1.000000,0.000000) [0.000000|1.000000] "" Vector__XXX
 SG_ ESP_Konsistenz_AWV2  : 95|1@1+ (1.000000,0.000000) [0.000000|1.000000] "" Vector__XXX
 SG_ ECD_Fehler  : 96|1@1+ (1.000000,0.000000) [0.000000|1.000000] "" Vector__XXX
 SG_ ECD_nicht_verfuegbar  : 97|1@1+ (1.000000,0.000000) [0.000000|1.000000] "" Vector__XXX
 SG_ ESP_Status_Bremsentemp  : 98|1@1+ (1.000000,0.000000) [0.000000|1.000000] "" Vector__XXX
 SG_ ESP_Autohold_Standby  : 99|1@1+ (1.000000,0.000000) [0.000000|1.000000] "" Vector__XXX
 SG_ ESP_HDC_Standby  : 100|1@1+ (1.000000,0.000000) [0.000000|1.000000] "" Vector__XXX
 SG_ ESP_HBA_aktiv  : 101|1@1+ (1.000000,0.000000) [0.000000|1.000000] "" Vector__XXX
 SG_ ESP_Prefill_ausgeloest  : 102|1@1+ (1.000000,0.000000) [0.000000|1.000000] "" Vector__XXX
 SG_ ESP_Rueckwaertsfahrt_erkannt  : 103|1@1+ (1.000000,0.000000) [0.000000|1.000000] "" Vector__XXX
 SG_ ESP_Status_Anfahrhilfe  : 104|1@1+ (1.000000,0.000000) [0.000000|1.000000] "" Vector__XXX
 SG_ ESP_HDC_aktiv  : 105|1@1+ (1.000000,0.000000) [0.000000|1.000000] "" Vector__XXX
 SG_ ESP_StartStopp_Info  : 106|2@1+ (1.000000,0.000000) [0.000000|3.000000] "" Vector__XXX
 SG_ ESP_Eingr_HL  : 108|1@1+ (1.000000,0.000000) [0.000000|1.000000] "" Vector__XXX
 SG_ ESP_Eingr_HR  : 109|1@1+ (1.000000,0.000000) [0.000000|1.000000] "" Vector__XXX
 SG_ ESP_Eingr_VL  : 110|1@1+ (1.000000,0.000000) [0.000000|1.000000] "" Vector__XXX
 SG_ ESP_Eingr_VR  : 111|1@1+ (1.000000,0.000000) [0.000000|1.000000] "" Vector__XXX
 SG_ ESP_BKV_Unterdruck  : 112|8@1+ (4.000000,0.000000) [4.000000|1012.000000] "Unit_MilliBar" Vector__XXX
 SG_ ESP_Autohold_aktiv  : 120|1@1+ (1.000000,0.000000) [0.000000|1.000000] "" Vector__XXX
 SG_ ESP_FStatus_Anfahrhilfe  : 121|1@1+ (1.000000,0.000000) [0.000000|1.000000] "" Vector__XXX
 SG_ ESP_Verz_EPB_aktiv  : 122|1@1+ (1.000000,0.000000) [0.000000|1.000000] "" Vector__XXX
 SG_ ECD_Bremslicht  : 123|1@1+ (1.000000,0.000000) [0.000000|1.000000] "" Motor_BEV
 SG_ ESP_Verzoeg_EPB_verf  : 124|1@1+ (1.000000,0.000000) [0.000000|1.000000] "" Vector__XXX
 SG_ ESP_Status_Bremsdruck  : 125|1@1+ (1.000000,0.000000) [0.000000|1.000000] "" Vector__XXX
 SG_ ESP_Anforderung_EPB  : 126|2@1+ (1.000000,0.000000) [0.000000|3.000000] "" Vector__XXX
 SG_ ESP_ANB_CM_Rueckk_Umsetz  : 140|1@1+ (1.000000,0.000000) [0.000000|1.000000] "" Vector__XXX
 SG_ ESP_Konsistenz_ACC_Botschaft  : 141|1@1+ (1.000000,0.000000) [0.000000|1.000000] "" Vector__XXX
 SG_ ESP_Stillstandsphase_erschoepft  : 142|1@1+ (1.000000,0.000000) [0.000000|1.000000] "" Vector__XXX
 SG_ ESP_ZT_Rueckk_Umsetz  : 143|1@1+ (1.000000,0.000000) [0.000000|1.000000] "" Vector__XXX
 SG_ ESP_Tuerkontakt_Fahrertuer  : 144|1@1+ (1.000000,0.000000) [0.000000|1.000000] "" Vector__XXX
 SG_ ESP_Abrutschen_Stillstand  : 146|1@1+ (1.000000,0.000000) [0.000000|1.000000] "" Vector__XXX
 SG_ ESP_Fahrer_tritt_ZBR_Schw  : 147|1@1+ (1.000000,0.000000) [0.000000|1.000000] "" Vector__XXX
 SG_ ESP_QBit_v_ref  : 169|1@1+ (1.000000,0.000000) [0.000000|1.000000] "" Vector__XXX
 SG_ ESP_v_ref_Fahrtrichtung  : 170|2@1+ (1.000000,0.000000) [0.000000|3.000000] "" Motor_BEV
 SG_ ESC_Bremsdruckgradient  : 172|8@1+ (10.000000,0.000000) [0.000000|2500.000000] "Unit_BarPerSecon" Vector__XXX
 SG_ ESP_v_ref  : 180|12@1+ (0.125000,0.000000) [0.000000|511.500000] "Unit_KiloMeterPerHour" Airbag Motor_BEV
 SG_ ESC_Hydr_Fkt_aktiv  : 223|2@1+ (1.000000,0.000000) [0.000000|3.000000] "" Vector__XXX
 SG_ ESC_QBit_Fahrerbremswunsch  : 225|1@1+ (1.000000,0.000000) [0.000000|1.000000] "" Motor_BEV
 SG_ ESC_Fahrerbremswunsch  : 226|10@1+ (0.300000,-30.000000) [-30.000000|276.600000] "Unit_Bar" Motor_BEV
 SG_ ESCGeneratorSollMoment  : 236|12@1+ (3.000000,-12279.000000) [-12279.000000|0.000000] "" Motor_BEV
 SG_ ESC_Raddruck_max  : 248|8@1+ (1.000000,0.000000) [0.000000|250.000000] "Unit_Bar" Vector__XXX
 SG_ EPB_QBit_Pedalweg_Kuppl  : 269|1@1+ (1.000000,0.000000) [0.000000|1.000000] "" Vector__XXX
 SG_ EPB_Freig_Verzoeg_Anf  : 271|1@1+ (1.000000,0.000000) [0.000000|1.000000] "" Vector__XXX
 SG_ EPB_Verzoeg_Anf  : 272|8@1+ (0.048000,-7.968000) [-7.968000|4.224000] "Unit_MeterPerSeconSquar" Vector__XXX
 SG_ EPB_Pedalweg_Kuppl  : 288|8@1+ (0.400000,0.000000) [8.000000|92.000000] "Unit_PerCent" Vector__XXX
 SG_ EPB_DAA_Randbed_erf  : 305|1@1+ (1.000000,0.000000) [0.000000|1.000000] "" Vector__XXX
 SG_ EPB_Fehlerstatus_02  : 306|2@1+ (1.000000,0.000000) [0.000000|3.000000] "" Vector__XXX
 SG_ EPB_Schalterposition  : 308|2@1+ (1.000000,0.000000) [0.000000|3.000000] "" Airbag
 SG_ EPB_QBit_Schalterpos  : 310|1@1+ (1.000000,0.000000) [0.000000|1.000000] "" Vector__XXX
 SG_ EPB_Spannkraft  : 312|5@1+ (1.000000,0.000000) [0.000000|29.000000] "Unit_KiloNewto" Vector__XXX
 SG_ EPB_Status_02  : 317|3@1+ (1.000000,0.000000) [0.000000|7.000000] "" Motor_BEV
 SG_ EPB_Status  : 320|2@1+ (1.000000,0.000000) [0.000000|3.000000] "" Vector__XXX
 SG_ ESP_Status_Bremsentemp_02  : 322|2@1+ (1.000000,0.000000) [0.000000|3.000000] "" Motor_BEV

BO_ 252 ESC_51: 48 ICAS1_Gateway
 SG_ ESC_51_CRC  : 0|8@1+ (1.000000,0.000000) [0.000000|255.000000] "" Motor_BEV
 SG_ ESC_51_BZ  : 8|4@1+ (1.000000,0.000000) [0.000000|15.000000] "" Motor_BEV
 SG_ ESC_aktBr_Modus  : 12|2@1+ (1.000000,0.000000) [0.000000|3.000000] "" Vector__XXX
 SG_ ESC_Blending_Solldruck  : 14|10@1+ (0.250000,0.000000) [0.000000|250.000000] "Unit_Bar" Vector__XXX
 SG_ ESC_aktBr_Volumenstrom  : 24|16@1+ (0.007812,-252.000000) [-252.000000|252.000000] "Unit_MilliLiterPerSec" Vector__XXX
 SG_ ESC_EBKV_Kraftblending_Modus  : 40|2@1+ (1.000000,0.000000) [0.000000|3.000000] "" Vector__XXX
 SG_ ESC_Bremsdruck_Modell  : 42|10@1+ (0.250000,0.000000) [0.000000|250.000000] "Unit_Bar" Motor_BEV
 SG_ ESC_Bremsdruck_02  : 52|10@1+ (0.300000,-30.000000) [-30.000000|276.600000] "Unit_Bar" Vector__XXX
 SG_ ESC_QBit_Bremsdruck_02  : 62|1@1+ (1.000000,0.000000) [0.000000|1.000000] "" Vector__XXX
 SG_ ESP_HL_Radgeschw_02  : 64|16@1+ (0.007500,0.000000) [0.000000|491.490000] "Unit_KiloMeterPerHour" Airbag LE1 LE2 Motor_BEV
 SG_ ESP_HR_Radgeschw_02  : 80|16@1+ (0.007500,0.000000) [0.000000|491.490000] "Unit_KiloMeterPerHour" Airbag LE1 LE2 Motor_BEV
 SG_ ESP_VL_Radgeschw_02  : 96|16@1+ (0.007500,0.000000) [0.000000|491.490000] "Unit_KiloMeterPerHour" Airbag LE1 LE2 Motor_BEV
 SG_ ESP_VR_Radgeschw_02  : 112|16@1+ (0.007500,0.000000) [0.000000|491.490000] "Unit_KiloMeterPerHour" Airbag LE1 LE2 Motor_BEV
 SG_ ESP_FZR_uebersteuern  : 128|8@1+ (0.004000,0.000000) [0.000000|1.000000] "" Vector__XXX
 SG_ ESP_FZR_untersteuern  : 136|8@1+ (0.004000,0.000000) [0.000000|1.000000] "" Vector__XXX
 SG_ ESC_Anf_Mindestreku  : 144|1@1+ (1.000000,0.000000) [0.000000|1.000000] "" Motor_BEV
 SG_ ESC_GMV_aktiv  : 145|3@1+ (1.000000,0.000000) [0.000000|7.000000] "" Vector__XXX
 SG_ ESC_GMV_nicht_verfuegbar  : 148|1@1+ (1.000000,0.000000) [0.000000|1.000000] "" Vector__XXX
 SG_ ESC_Status_vRef_Stuetzeingriff  : 149|1@1+ (1.000000,0.000000) [0.000000|1.000000] "" Motor_BEV
 SG_ FDR_Allradverteilung_aktiv  : 150|1@1+ (1.000000,0.000000) [0.000000|1.000000] "" Vector__XXX
 SG_ FDR_Anf_Allradbetrieb  : 151|1@1+ (1.000000,0.000000) [0.000000|1.000000] "" Vector__XXX
 SG_ ESP_HL_Bremsmoment  : 152|8@1+ (20.000000,0.000000) [0.000000|5060.000000] "Unit_NewtoMeter" Motor_BEV
 SG_ ESP_HR_Bremsmoment  : 160|8@1+ (20.000000,0.000000) [0.000000|5060.000000] "Unit_NewtoMeter" Motor_BEV
 SG_ ESP_VR_Bremsmoment  : 168|8@1+ (40.000000,0.000000) [0.000000|10120.000000] "Unit_NewtoMeter" Motor_BEV
 SG_ ESP_VL_Bremsmoment  : 176|8@1+ (40.000000,0.000000) [0.000000|10120.000000] "Unit_NewtoMeter" Motor_BEV
 SG_ ESP_FDR_uebersteuern  : 184|8@1+ (0.004000,0.000000) [0.000000|1.000000] "" Motor_BEV
 SG_ ESP_FDR_untersteuern  : 192|8@1+ (0.004000,0.000000) [0.000000|1.000000] "" Motor_BEV
 SG_ TSMomBegrenzung  : 268|12@1+ (3.000000,-12279.000000) [-12279.000000|0.000000] "" Motor_BEV
 SG_ ESC_Allrad_Anteil_max_sek  : 280|9@1+ (0.200000,0.000000) [0.000000|100.000000] "Unit_PerCent" Motor_BEV
 SG_ ESC_Allrad_Anteil_min_sek  : 289|9@1+ (0.200000,0.000000) [0.000000|100.000000] "Unit_PerCent" Motor_BEV
 SG_ ESC_Status_Eingriff  : 298|2@1+ (1.000000,0.000000) [0.000000|3.000000] "" Motor_BEV
 SG_ ESC_Status_Eingriff_sek  : 300|2@1+ (1.000000,0.000000) [0.000000|3.000000] "" Motor_BEV
 SG_ ESC_MomRad_Eingriff  : 302|13@1+ (3.000000,-12279.000000) [-12279.000000|12279.000000] "Unit_None" Motor_BEV
 SG_ ESC_MomRad_Eingriff_sek  : 315|13@1+ (3.000000,-12279.000000) [-12279.000000|12279.000000] "Unit_None" Motor_BEV
 SG_ ESC_Achsdrehzahl_Max  : 328|14@1+ (0.400000,-800.000000) [-800.000000|5752.400000] "Unit_MinutInver" Motor_BEV
 SG_ ESC_Achsdrehzahl_Min  : 342|14@1+ (0.400000,-800.000000) [-800.000000|5752.400000] "Unit_MinutInver" Motor_BEV
 SG_ ESC_Achsdrehzahl_Max_sek  : 356|14@1+ (0.400000,-800.000000) [-800.000000|5752.400000] "Unit_MinutInver" Motor_BEV
 SG_ ESC_Achsdrehzahl_Min_sek  : 370|14@1+ (0.400000,-800.000000) [-800.000000|5752.400000] "Unit_MinutInver" Motor_BEV

BO_ 2463978647 ESC_52: 16 ICAS1_Gateway
 SG_ ESP_ACC_LDE  : 12|1@1+ (1.000000,0.000000) [0.000000|1.000000] "" Vector__XXX
 SG_ ESP_Allrad_Antrieb  : 13|1@1+ (1.000000,0.000000) [0.000000|1.000000] "" Vector__XXX
 SG_ ESP_Codierung_ADS  : 14|2@1+ (1.000000,0.000000) [0.000000|3.000000] "" Vector__XXX
 SG_ ESP_RTA_HL  : 16|8@1+ (0.048828,-6.201170) [-6.201170|6.152346] "Unit_PerCent" Motor_BEV
 SG_ ESP_RTA_HR  : 24|8@1+ (0.048828,-6.201170) [-6.201170|6.152346] "Unit_PerCent" Motor_BEV
 SG_ ESP_RTA_VR  : 32|8@1+ (0.048828,-6.201170) [-6.201170|6.152346] "Unit_PerCent" Motor_BEV
 SG_ OBD_Fehler_Radsensor_HL  : 40|4@1+ (1.000000,0.000000) [0.000000|15.000000] "" Motor_BEV
 SG_ OBD_Fehler_Radsensor_HR  : 44|4@1+ (1.000000,0.000000) [0.000000|15.000000] "" Motor_BEV
 SG_ OBD_Fehler_Radsensor_VL  : 48|4@1+ (1.000000,0.000000) [0.000000|15.000000] "" Motor_BEV
 SG_ OBD_Fehler_Radsensor_VR  : 52|4@1+ (1.000000,0.000000) [0.000000|15.000000] "" Motor_BEV
 SG_ ESP_Qualifizierung_Antriebsart  : 56|1@1+ (1.000000,0.000000) [0.000000|1.000000] "" Vector__XXX
 SG_ ESP_Offroad_Modus  : 57|1@1+ (1.000000,0.000000) [0.000000|1.000000] "" Vector__XXX
 SG_ ESP_MKB_ausloesbar  : 58|1@1+ (1.000000,0.000000) [0.000000|1.000000] "" Vector__XXX
 SG_ ESP_Stat_FallBack_eBKV  : 59|1@1+ (1.000000,0.000000) [0.000000|1.000000] "" Vector__XXX
 SG_ ESP_CM_Variante  : 60|1@1+ (1.000000,0.000000) [0.000000|1.000000] "" Vector__XXX
 SG_ ESP_OBD_Status  : 61|1@1+ (1.000000,0.000000) [0.000000|1.000000] "" Motor_BEV
 SG_ ESP_Rollenmodus_Deaktivieren  : 62|1@1+ (1.000000,0.000000) [0.000000|1.000000] "" Motor_BEV
 SG_ ESP_nachtr_Stopp_Anf  : 63|1@1+ (1.000000,0.000000) [0.000000|1.000000] "" Vector__XXX

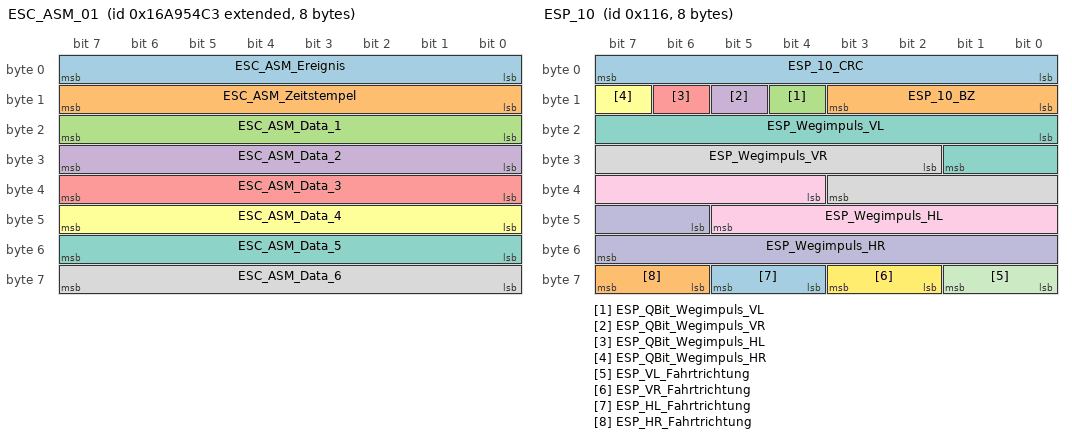
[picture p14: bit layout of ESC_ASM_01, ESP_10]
BO_ 2527679683 ESC_ASM_01: 8 ICAS1_Gateway
 SG_ ESC_ASM_Ereignis  : 0|8@1+ (1.000000,0.000000) [1.000000|254.000000] "Unit_None" Airbag
 SG_ ESC_ASM_Zeitstempel  : 8|8@1+ (0.080000,0.000000) [0.000000|20.320000] "Unit_Secon" Airbag
 SG_ ESC_ASM_Data_1  : 16|8@1+ (1.000000,0.000000) [0.000000|255.000000] "" Airbag
 SG_ ESC_ASM_Data_2  : 24|8@1+ (1.000000,0.000000) [0.000000|255.000000] "" Airbag
 SG_ ESC_ASM_Data_3  : 32|8@1+ (1.000000,0.000000) [0.000000|255.000000] "" Airbag
 SG_ ESC_ASM_Data_4  : 40|8@1+ (1.000000,0.000000) [0.000000|255.000000] "" Airbag
 SG_ ESC_ASM_Data_5  : 48|8@1+ (1.000000,0.000000) [0.000000|255.000000] "" Airbag
 SG_ ESC_ASM_Data_6  : 56|8@1+ (1.000000,0.000000) [0.000000|255.000000] "" Airbag

BO_ 278 ESP_10: 8 ICAS1_Gateway
 SG_ ESP_10_CRC  : 0|8@1+ (1.000000,0.000000) [0.000000|255.000000] "" Vector__XXX
 SG_ ESP_10_BZ  : 8|4@1+ (1.000000,0.000000) [0.000000|15.000000] "" Vector__XXX
 SG_ ESP_QBit_Wegimpuls_VL  : 12|1@1+ (1.000000,0.000000) [0.000000|1.000000] "" Motor_BEV
 SG_ ESP_QBit_Wegimpuls_VR  : 13|1@1+ (1.000000,0.000000) [0.000000|1.000000] "" Motor_BEV
 SG_ ESP_QBit_Wegimpuls_HL  : 14|1@1+ (1.000000,0.000000) [0.000000|1.000000] "" Motor_BEV
 SG_ ESP_QBit_Wegimpuls_HR  : 15|1@1+ (1.000000,0.000000) [0.000000|1.000000] "" Motor_BEV
 SG_ ESP_Wegimpuls_VL  : 16|10@1+ (1.000000,0.000000) [0.000000|1000.000000] "" Motor_BEV
 SG_ ESP_Wegimpuls_VR  : 26|10@1+ (1.000000,0.000000) [0.000000|1000.000000] "" Motor_BEV
 SG_ ESP_Wegimpuls_HL  : 36|10@1+ (1.000000,0.000000) [0.000000|1000.000000] "" Motor_BEV
 SG_ ESP_Wegimpuls_HR  : 46|10@1+ (1.000000,0.000000) [0.000000|1000.000000] "" Motor_BEV
 SG_ ESP_VL_Fahrtrichtung  : 56|2@1+ (1.000000,0.000000) [0.000000|3.000000] "" Motor_BEV
 SG_ ESP_VR_Fahrtrichtung  : 58|2@1+ (1.000000,0.000000) [0.000000|3.000000] "" Motor_BEV
 SG_ ESP_HL_Fahrtrichtung  : 60|2@1+ (1.000000,0.000000) [0.000000|3.000000] "" Motor_BEV
 SG_ ESP_HR_Fahrtrichtung  : 62|2@1+ (1.000000,0.000000) [0.000000|3.000000] "" Motor_BEV

CM_ SG_ 219 SDF_PSF_Objektstatus "Objektstatus";
CM_ SG_ 219 SDF_PSF_CU_Status "Kollisionsvermeidbarkeit";
CM_ SG_ 219 SDF_PSF_CW "Kollisionswahrscheinlichkeit";
CM_ SG_ 219 SDF_PSF_Fahrer_aktiv "Fahreraktivität";
CM_ SG_ 219 AWV_QFK_KruemmSoll "Krümmungsanforderung";
CM_ SG_ 869 BEM_Batt_Ab "Batterieverbindungskontrolle:
0x0: Batterie am Bordnetz
0x1: Batterie ab erkannt";
CM_ SG_ 2463978646 CHA_Ziel_FahrPr_ACC "MQB
Anforderung Ziel-Fahrprogramm ACC";
CM_ SG_ 514 DR_Aufbaubeschleunigung_HR "Aufbaubeschleunigungssensor
Auflösung 1g/300
Wertebereich -1,6g..1,6g
in m/s^2 übertragen.";
CM_ SG_ 514 DR_Aufbaubeschleunigung_VR "Aufbaubeschleunigungssensor
Auflösung 1g/300
Wertebereich -1,6g..1,6g
in m/s^2 übertragen.";
CM_ SG_ 514 DR_Aufbaubeschleunigung_VL "Aufbaubeschleunigungssensor
Auflösung 1g/300
Wertebereich -1,6g..1,6g
in m/s^2 übertragen.";
CM_ SG_ 514 DR_Aufbaubeschleunigung_HL "Aufbaubeschleunigungssensor
Auflösung 1g/300
Wertebereich -1,6g..1,6g
in m/s^2 übertragen.";
CM_ SG_ 2549876269 Diag_Waehlhebel_Req_Data "UDS-Diagnose
ISO-TP Datenkanal - FID2NA
Request Funktion 0x06 Diagnosezugriff vom DK4-Master auf DK1/2-Knoten 0x62D";
CM_ SG_ 2550007341 Diag_Waehlhebel_Resp_Data "UDS-Diganose
ISO-TP Datenkanal - FID2NA
Response DK1/2-Knoten 0x62D an Funktion 0x06 Diagnosezugriff vom DK4-Master";
CM_ SG_ 1714 Uhrzeit_01_alt "
";
CM_ SG_ 851 DiETa_Lock_Unlock_Taste "Lock-/Unlock-Taste";
CM_ SG_ 374 EBKV_QBit_Fahrer_bremst "
";
CM_ SG_ 184 EM1_Freigabe_Info_WFS "WFS-Freigabeinformation";
CM_ SG_ 184 EM1_Sperr_Info_WFS "WFS-Sperrinformation
";
CM_ SG_ 184 EM1_Freigabe_Verfallsinfo_WFS "WFS";
CM_ SG_ 199 EM2_Freigabe_Info_WFS "WFS-Freigabeinformation

";
CM_ SG_ 199 EM2_Sperr_Info_WFS "WFS-Sperrinformation
";
CM_ SG_ 199 EM2_Freigabe_Verfallsinfo_WFS "WFS";
CM_ SG_ 258 ESP_v_ref "MLBevo:
Signal wird nur von einem BOSCH ESP System zur Verfügung gestellt. Exklusives Signal vom BOSCH ESP zum BOSCH Airbag für ROSEII Funktion und für Fahrwerkregelsysteme.
Verwendung nur nach vorheriger Abstimmung mit den verantwortlichen EF Fachbere";
CM_ SG_ 258 EPB_Freig_Verzoeg_Anf "Verzögerungsanforderung	";
CM_ SG_ 278 ESP_10_BZ "Botschaftszähler

Wird im Projekt D4 und D4Hybrid nicht verwendet!  Wird im D4 PA verwendet";
BA_DEF_  "NmhMessageCount" INT 0 1024;
BA_DEF_  "VersionDay" INT 1 31;
BA_DEF_  "VersionMonth" INT 1 12;
BA_DEF_  "VersionWeek" INT 1 52;
BA_DEF_  "VersionYear" INT 0 99;
BA_DEF_  "Baudrate" INT 1 1000000;
BA_DEF_  "BaudrateCANFD" INT 1 16000000;
BA_DEF_ BU_ "GenNodAutoGenDsp" ENUM "No", "Yes";
BA_DEF_ BU_ "GenNodAutoGenSnd" ENUM "No", "Yes";
BA_DEF_ BU_ "GenNodSleepTime" INT 0 1000000;
BA_DEF_ BU_ "ILUsed" ENUM "No", "Yes";
BA_DEF_ BU_ "ECUVariantDefault" ENUM "No", "Yes";
BA_DEF_ BU_ "ECUVariantGroup" STRING;
BA_DEF_ BU_ "NodeLayerModules" STRING;
BA_DEF_ BU_ "NmhNode" ENUM "No", "Yes";
BA_DEF_ BU_ "NmNode" ENUM "No", "Yes";
BA_DEF_ BU_ "SamplePointMin" FLOAT 50.000000 99.900000;
BA_DEF_ BU_ "SamplePointMax" FLOAT 50.000000 99.900000;
BA_DEF_ BU_ "SyncJumpWidthMin" FLOAT 0.000000 50.000000;
BA_DEF_ BU_ "SyncJumpWidthMax" FLOAT 0.000000 50.000000;
BA_DEF_ BU_ "SyncJumpWidthCANFDMin" FLOAT 0.000000 50.000000;
BA_DEF_ BU_ "SyncJumpWidthCANFDMax" FLOAT 0.000000 50.000000;
BA_DEF_ BU_ "SamplePointCANFDMin" FLOAT 50.000000 99.900000;
BA_DEF_ BU_ "SamplePointCANFDMax" FLOAT 50.000000 99.900000;
BA_DEF_ BU_ "SSPOffsetCANFDMin" FLOAT 50.000000 99.900000;
BA_DEF_ BU_ "SSPOffsetCANFDMax" FLOAT 50.000000 99.900000;
BA_DEF_ BU_ "TimeQuantaMin" INT 4 257;
BA_DEF_ BU_ "TimeQuantaMax" INT 4 257;
BA_DEF_ BU_ "TimeQuantaCANFDMin" INT 4 257;
BA_DEF_ BU_ "TimeQuantaCANFDMax" INT 4 257;
BA_DEF_ BO_ "DiagRequest" ENUM "No", "Yes";
BA_DEF_ BO_ "DiagResponse" ENUM "No", "Yes";
BA_DEF_ BO_ "DiagState" ENUM "No", "Yes";
BA_DEF_ BO_ "GenMsgChkConstant" HEX 0 4095;
BA_DEF_ BO_ "GenMsgCycleTime" INT 0 65535;
BA_DEF_ BO_ "GenMsgCycleTimeFast" INT 0 65535;
BA_DEF_ BO_ "GenMsgDelayTime" INT 0 100000;
BA_DEF_ BO_ "GenMsgILSupport" ENUM "No", "Yes";
BA_DEF_ BO_ "GenMsgNrOfRepetition" INT 0 100;
BA_DEF_ BO_ "GenMsgPDUConstants" STRING;
BA_DEF_ BO_ "GenMsgSendType" ENUM "Cyclic", "not_used", "not_used", "not_used", "not_used", "not_used", "not_used", "IfActive", "NoMsgSendType";
BA_DEF_ BO_ "GenMsgStartDelayTime" INT 0 100000;
BA_DEF_ BO_ "NmMessage" ENUM "No", "Yes";
BA_DEF_ BO_ "NmhMessage" ENUM "No", "Yes";
BA_DEF_ BO_ "MsgType" ENUM "Application", "NM", "NMH", "TP2.0", "ISO-TP", "BAP", "EID", "KS";
BA_DEF_ BO_ "VAGTP20_API" HEX 0 255;
BA_DEF_ BO_ "VAGTP20_DynConnection" ENUM "No", "Yes";
BA_DEF_ BO_ "VAGTP20_DynSetup" ENUM "No", "Yes";
BA_DEF_ BO_ "VAGTP20_StatConnection" ENUM "No", "Yes";
BA_DEF_ BO_ "CANFD_BRS" ENUM "0", "1";
BA_DEF_ BO_ "VFrameFormat" ENUM "StandardCAN", "ExtendedCAN", "reserved", "reserved", "reserved", "reserved", "reserved", "reserved", "reserved", "reserved", "reserved", "reserved", "reserved", "reserved", "StandardCAN_FD", "ExtendedCAN_FD";
BA_DEF_ SG_ "GenSigSendType" ENUM "Cyclic", "OnWrite", "OnWriteWithRepetition", "OnChange", "OnChangeWithRepetition", "IfActive", "IfActiveWithRepetition", "NoSigSendType", "OnChangeAndIfActive", "OnChangeAndIfActiveWithRepetition";
BA_DEF_ SG_ "GenSigFuncType" ENUM "NoFunction", "MsgCounter", "CRC-8", "XOR", "XOR-2", "DatedBit", "SW-Kl15", "CHK", "Constant", "Protocol", "CRC-8-SAE_J1850";
BA_DEF_ SG_ "GenSigSwitchedByIgnition" ENUM "No", "Yes";
BA_DEF_DEF_  "NmhMessageCount" 1;
BA_DEF_DEF_  "VersionDay" 8;
BA_DEF_DEF_  "VersionMonth" 2;
BA_DEF_DEF_  "VersionWeek" 6;
BA_DEF_DEF_  "VersionYear" 18;
BA_DEF_DEF_  "Baudrate" 500000;
BA_DEF_DEF_  "BaudrateCANFD" 2000000;
BA_DEF_DEF_  "GenNodAutoGenDsp" "Yes";
BA_DEF_DEF_  "GenNodAutoGenSnd" "Yes";
BA_DEF_DEF_  "GenNodSleepTime" 0;
BA_DEF_DEF_  "ILUsed" "Yes";
BA_DEF_DEF_  "ECUVariantDefault" "Yes";
BA_DEF_DEF_  "ECUVariantGroup" "";
BA_DEF_DEF_  "NodeLayerModules" "";
BA_DEF_DEF_  "NmhNode" "Yes";
BA_DEF_DEF_  "NmNode" "No";
BA_DEF_DEF_  "SamplePointMin" 75.000000;
BA_DEF_DEF_  "SamplePointMax" 75.000000;
BA_DEF_DEF_  "SyncJumpWidthMin" 50.000000;
BA_DEF_DEF_  "SyncJumpWidthMax" 50.000000;
BA_DEF_DEF_  "SyncJumpWidthCANFDMin" 50.000000;
BA_DEF_DEF_  "SyncJumpWidthCANFDMax" 50.000000;
BA_DEF_DEF_  "SamplePointCANFDMin" 75.000000;
BA_DEF_DEF_  "SamplePointCANFDMax" 75.000000;
BA_DEF_DEF_  "SSPOffsetCANFDMin" 75.000000;
BA_DEF_DEF_  "SSPOffsetCANFDMax" 75.000000;
BA_DEF_DEF_  "TimeQuantaMin" 160;
BA_DEF_DEF_  "TimeQuantaMax" 160;
BA_DEF_DEF_  "TimeQuantaCANFDMin" 40;
BA_DEF_DEF_  "TimeQuantaCANFDMax" 40;
BA_DEF_DEF_  "DiagRequest" "No";
BA_DEF_DEF_  "DiagResponse" "No";
BA_DEF_DEF_  "DiagState" "No";
BA_DEF_DEF_  "GenMsgChkConstant" 0;
BA_DEF_DEF_  "GenMsgCycleTime" 0;
BA_DEF_DEF_  "GenMsgCycleTimeFast" 0;
BA_DEF_DEF_  "GenMsgDelayTime" 0;
BA_DEF_DEF_  "GenMsgILSupport" "No";
BA_DEF_DEF_  "GenMsgNrOfRepetition" 0;
BA_DEF_DEF_  "GenMsgPDUConstants" "";
BA_DEF_DEF_  "GenMsgSendType" "NoMsgSendType";
BA_DEF_DEF_  "GenMsgStartDelayTime" 0;
BA_DEF_DEF_  "NmMessage" "No";
BA_DEF_DEF_  "NmhMessage" "No";
BA_DEF_DEF_  "MsgType" "Application";
BA_DEF_DEF_  "VAGTP20_API" 0;
BA_DEF_DEF_  "VAGTP20_DynConnection" "No";
BA_DEF_DEF_  "VAGTP20_DynSetup" "No";
BA_DEF_DEF_  "VAGTP20_StatConnection" "No";
BA_DEF_DEF_  "CANFD_BRS" "1";
BA_DEF_DEF_  "VFrameFormat" "StandardCAN";
BA_DEF_DEF_  "GenSigSendType" "NoSigSendType";
BA_DEF_DEF_  "GenSigFuncType" "NoFunction";
BA_DEF_DEF_  "GenSigSwitchedByIgnition" "Yes";
BA_ "GenNodSleepTime" BU_ Airbag 4000;
BA_ "NodeLayerModules" BU_ Airbag "NMHigh.DLL";
BA_ "SamplePointMin" BU_ Airbag 80.000000;
BA_ "SamplePointMax" BU_ Airbag 80.000000;
BA_ "SyncJumpWidthMin" BU_ Airbag 16.000000;
BA_ "SyncJumpWidthMax" BU_ Airbag 16.000000;
BA_ "SyncJumpWidthCANFDMin" BU_ Airbag 6.000000;
BA_ "SyncJumpWidthCANFDMax" BU_ Airbag 6.000000;
BA_ "SamplePointCANFDMin" BU_ Airbag 70.000000;
BA_ "SamplePointCANFDMax" BU_ Airbag 70.000000;
BA_ "SSPOffsetCANFDMin" BU_ Airbag 70.000000;
BA_ "SSPOffsetCANFDMax" BU_ Airbag 70.000000;
BA_ "TimeQuantaMin" BU_ Airbag 80;
BA_ "TimeQuantaMax" BU_ Airbag 80;
BA_ "TimeQuantaCANFDMin" BU_ Airbag 20;
BA_ "TimeQuantaCANFDMax" BU_ Airbag 20;
BA_ "GenNodSleepTime" BU_ BAP_Tester 4000;
BA_ "ECUVariantGroup" BU_ BAP_Tester "BAP";
BA_ "NmhNode" BU_ BAP_Tester "No";
BA_ "SamplePointMin" BU_ BAP_Tester 80.000000;
BA_ "SamplePointMax" BU_ BAP_Tester 80.000000;
BA_ "SyncJumpWidthMin" BU_ BAP_Tester 16.000000;
BA_ "SyncJumpWidthMax" BU_ BAP_Tester 16.000000;
BA_ "SyncJumpWidthCANFDMin" BU_ BAP_Tester 6.000000;
BA_ "SyncJumpWidthCANFDMax" BU_ BAP_Tester 6.000000;
BA_ "SamplePointCANFDMin" BU_ BAP_Tester 70.000000;
BA_ "SamplePointCANFDMax" BU_ BAP_Tester 70.000000;
BA_ "SSPOffsetCANFDMin" BU_ BAP_Tester 70.000000;
BA_ "SSPOffsetCANFDMax" BU_ BAP_Tester 70.000000;
BA_ "TimeQuantaMin" BU_ BAP_Tester 80;
BA_ "TimeQuantaMax" BU_ BAP_Tester 80;
BA_ "TimeQuantaCANFDMin" BU_ BAP_Tester 20;
BA_ "TimeQuantaCANFDMax" BU_ BAP_Tester 20;
BA_ "GenNodSleepTime" BU_ ICAS1_Gateway 4000;
BA_ "ECUVariantGroup" BU_ ICAS1_Gateway "Gateway";
BA_ "NodeLayerModules" BU_ ICAS1_Gateway "NMHigh.DLL";
BA_ "SamplePointMin" BU_ ICAS1_Gateway 80.000000;
BA_ "SamplePointMax" BU_ ICAS1_Gateway 80.000000;
BA_ "SyncJumpWidthMin" BU_ ICAS1_Gateway 16.000000;
BA_ "SyncJumpWidthMax" BU_ ICAS1_Gateway 16.000000;
BA_ "SyncJumpWidthCANFDMin" BU_ ICAS1_Gateway 6.000000;
BA_ "SyncJumpWidthCANFDMax" BU_ ICAS1_Gateway 6.000000;
BA_ "SamplePointCANFDMin" BU_ ICAS1_Gateway 70.000000;
BA_ "SamplePointCANFDMax" BU_ ICAS1_Gateway 70.000000;
BA_ "SSPOffsetCANFDMin" BU_ ICAS1_Gateway 70.000000;
BA_ "SSPOffsetCANFDMax" BU_ ICAS1_Gateway 70.000000;
BA_ "TimeQuantaMin" BU_ ICAS1_Gateway 80;
BA_ "TimeQuantaMax" BU_ ICAS1_Gateway 80;
BA_ "TimeQuantaCANFDMin" BU_ ICAS1_Gateway 20;
BA_ "TimeQuantaCANFDMax" BU_ ICAS1_Gateway 20;
BA_ "GenNodSleepTime" BU_ ICAS1_KommunikationsServer 4000;
BA_ "NmhNode" BU_ ICAS1_KommunikationsServer "No";
BA_ "SamplePointMin" BU_ ICAS1_KommunikationsServer 80.000000;
BA_ "SamplePointMax" BU_ ICAS1_KommunikationsServer 80.000000;
BA_ "SyncJumpWidthMin" BU_ ICAS1_KommunikationsServer 16.000000;
BA_ "SyncJumpWidthMax" BU_ ICAS1_KommunikationsServer 16.000000;
BA_ "SyncJumpWidthCANFDMin" BU_ ICAS1_KommunikationsServer 6.000000;
BA_ "SyncJumpWidthCANFDMax" BU_ ICAS1_KommunikationsServer 6.000000;
BA_ "SamplePointCANFDMin" BU_ ICAS1_KommunikationsServer 70.000000;
BA_ "SamplePointCANFDMax" BU_ ICAS1_KommunikationsServer 70.000000;
BA_ "SSPOffsetCANFDMin" BU_ ICAS1_KommunikationsServer 70.000000;
BA_ "SSPOffsetCANFDMax" BU_ ICAS1_KommunikationsServer 70.000000;
BA_ "TimeQuantaMin" BU_ ICAS1_KommunikationsServer 80;
BA_ "TimeQuantaMax" BU_ ICAS1_KommunikationsServer 80;
BA_ "TimeQuantaCANFDMin" BU_ ICAS1_KommunikationsServer 20;
BA_ "TimeQuantaCANFDMax" BU_ ICAS1_KommunikationsServer 20;
BA_ "GenNodSleepTime" BU_ LE1 4000;
BA_ "ECUVariantDefault" BU_ LE1 "No";
BA_ "ECUVariantGroup" BU_ LE1 "EMotor";
BA_ "NodeLayerModules" BU_ LE1 "NMHigh.DLL";
BA_ "SamplePointMin" BU_ LE1 80.000000;
BA_ "SamplePointMax" BU_ LE1 80.000000;
BA_ "SyncJumpWidthMin" BU_ LE1 16.000000;
BA_ "SyncJumpWidthMax" BU_ LE1 16.000000;
BA_ "SyncJumpWidthCANFDMin" BU_ LE1 6.000000;
BA_ "SyncJumpWidthCANFDMax" BU_ LE1 6.000000;
BA_ "SamplePointCANFDMin" BU_ LE1 70.000000;
BA_ "SamplePointCANFDMax" BU_ LE1 70.000000;
BA_ "SSPOffsetCANFDMin" BU_ LE1 70.000000;
BA_ "SSPOffsetCANFDMax" BU_ LE1 70.000000;
BA_ "TimeQuantaMin" BU_ LE1 80;
BA_ "TimeQuantaMax" BU_ LE1 80;
BA_ "TimeQuantaCANFDMin" BU_ LE1 20;
BA_ "TimeQuantaCANFDMax" BU_ LE1 20;
BA_ "GenNodSleepTime" BU_ LE2 4000;
BA_ "NodeLayerModules" BU_ LE2 "NMHigh.DLL";
BA_ "SamplePointMin" BU_ LE2 80.000000;
BA_ "SamplePointMax" BU_ LE2 80.000000;
BA_ "SyncJumpWidthMin" BU_ LE2 16.000000;
BA_ "SyncJumpWidthMax" BU_ LE2 16.000000;
BA_ "SyncJumpWidthCANFDMin" BU_ LE2 6.000000;
BA_ "SyncJumpWidthCANFDMax" BU_ LE2 6.000000;
BA_ "SamplePointCANFDMin" BU_ LE2 70.000000;
BA_ "SamplePointCANFDMax" BU_ LE2 70.000000;
BA_ "SSPOffsetCANFDMin" BU_ LE2 70.000000;
BA_ "SSPOffsetCANFDMax" BU_ LE2 70.000000;
BA_ "TimeQuantaMin" BU_ LE2 80;
BA_ "TimeQuantaMax" BU_ LE2 80;
BA_ "TimeQuantaCANFDMin" BU_ LE2 20;
BA_ "TimeQuantaCANFDMax" BU_ LE2 20;
BA_ "GenNodSleepTime" BU_ Motor_BEV 4000;
BA_ "ECUVariantGroup" BU_ Motor_BEV "Motor";
BA_ "NodeLayerModules" BU_ Motor_BEV "NMHigh.DLL";
BA_ "SamplePointMin" BU_ Motor_BEV 80.000000;
BA_ "SamplePointMax" BU_ Motor_BEV 80.000000;
BA_ "SyncJumpWidthMin" BU_ Motor_BEV 16.000000;
BA_ "SyncJumpWidthMax" BU_ Motor_BEV 16.000000;
BA_ "SyncJumpWidthCANFDMin" BU_ Motor_BEV 6.000000;
BA_ "SyncJumpWidthCANFDMax" BU_ Motor_BEV 6.000000;
BA_ "SamplePointCANFDMin" BU_ Motor_BEV 70.000000;
BA_ "SamplePointCANFDMax" BU_ Motor_BEV 70.000000;
BA_ "SSPOffsetCANFDMin" BU_ Motor_BEV 70.000000;
BA_ "SSPOffsetCANFDMax" BU_ Motor_BEV 70.000000;
BA_ "TimeQuantaMin" BU_ Motor_BEV 80;
BA_ "TimeQuantaMax" BU_ Motor_BEV 80;
BA_ "TimeQuantaCANFDMin" BU_ Motor_BEV 20;
BA_ "TimeQuantaCANFDMax" BU_ Motor_BEV 20;
BA_ "GenNodSleepTime" BU_ Schaltbetaetigung 4000;
BA_ "ECUVariantGroup" BU_ Schaltbetaetigung "Waehlhebel";
BA_ "NodeLayerModules" BU_ Schaltbetaetigung "NMHigh.DLL";
BA_ "SamplePointMin" BU_ Schaltbetaetigung 80.000000;
BA_ "SamplePointMax" BU_ Schaltbetaetigung 80.000000;
BA_ "SyncJumpWidthMin" BU_ Schaltbetaetigung 16.000000;
BA_ "SyncJumpWidthMax" BU_ Schaltbetaetigung 16.000000;
BA_ "SyncJumpWidthCANFDMin" BU_ Schaltbetaetigung 6.000000;
BA_ "SyncJumpWidthCANFDMax" BU_ Schaltbetaetigung 6.000000;
BA_ "SamplePointCANFDMin" BU_ Schaltbetaetigung 70.000000;
BA_ "SamplePointCANFDMax" BU_ Schaltbetaetigung 70.000000;
BA_ "SSPOffsetCANFDMin" BU_ Schaltbetaetigung 70.000000;
BA_ "SSPOffsetCANFDMax" BU_ Schaltbetaetigung 70.000000;
BA_ "TimeQuantaMin" BU_ Schaltbetaetigung 80;
BA_ "TimeQuantaMax" BU_ Schaltbetaetigung 80;
BA_ "TimeQuantaCANFDMin" BU_ Schaltbetaetigung 20;
BA_ "TimeQuantaCANFDMax" BU_ Schaltbetaetigung 20;
BA_ "GenMsgCycleTime" BO_ 333 20;
BA_ "GenMsgILSupport" BO_ 333 "Yes";
BA_ "GenMsgPDUConstants" BO_ 333 "0x1a,0x65,0x81,0x96,0xc0,0xdf,0x11,0x92,0xd3,0x61,0xc6,0x95,0x8c,0x29,0x21,0xb5";
BA_ "GenMsgSendType" BO_ 333 "Cyclic";
BA_ "VFrameFormat" BO_ 333 "StandardCAN_FD";
BA_ "GenMsgCycleTime" BO_ 2527679682 2000;
BA_ "GenMsgDelayTime" BO_ 2527679682 100;
BA_ "GenMsgILSupport" BO_ 2527679682 "Yes";
BA_ "GenMsgSendType" BO_ 2527679682 "Cyclic";
BA_ "VFrameFormat" BO_ 2527679682 "ExtendedCAN_FD";
BA_ "GenMsgChkConstant" BO_ 64 64;
BA_ "GenMsgCycleTime" BO_ 64 40;
BA_ "GenMsgCycleTimeFast" BO_ 64 10;
BA_ "GenMsgDelayTime" BO_ 64 10;
BA_ "GenMsgILSupport" BO_ 64 "Yes";
BA_ "GenMsgNrOfRepetition" BO_ 64 5;
BA_ "GenMsgPDUConstants" BO_ 64 "0x40,0x40,0x40,0x40,0x40,0x40,0x40,0x40,0x40,0x40,0x40,0x40,0x40,0x40,0x40,0x40";
BA_ "GenMsgSendType" BO_ 64 "Cyclic";
BA_ "CANFD_BRS" BO_ 64 "0";
BA_ "GenMsgChkConstant" BO_ 1312 68;
BA_ "GenMsgCycleTime" BO_ 1312 200;
BA_ "GenMsgDelayTime" BO_ 1312 20;
BA_ "GenMsgILSupport" BO_ 1312 "Yes";
BA_ "GenMsgPDUConstants" BO_ 1312 "0x44,0x44,0x44,0x44,0x44,0x44,0x44,0x44,0x44,0x44,0x44,0x44,0x44,0x44,0x44,0x44";
BA_ "GenMsgSendType" BO_ 1312 "Cyclic";
BA_ "CANFD_BRS" BO_ 1312 "0";
BA_ "GenMsgCycleTime" BO_ 65 1000;
BA_ "GenMsgCycleTimeFast" BO_ 65 10;
BA_ "GenMsgDelayTime" BO_ 65 10;
BA_ "GenMsgILSupport" BO_ 65 "Yes";
BA_ "GenMsgNrOfRepetition" BO_ 65 5;
BA_ "GenMsgPDUConstants" BO_ 65 "0x93,0xb0,0x9d,0xf1,0x09,0xe8,0x88,0x5e,0x36,0xfa,0xa8,0xa1,0x67,0x84,0xca,0x4f";
BA_ "GenMsgSendType" BO_ 65 "Cyclic";
BA_ "CANFD_BRS" BO_ 65 "0";
BA_ "GenMsgCycleTime" BO_ 1349 200;
BA_ "GenMsgDelayTime" BO_ 1349 40;
BA_ "GenMsgILSupport" BO_ 1349 "Yes";
BA_ "GenMsgSendType" BO_ 1349 "Cyclic";
BA_ "CANFD_BRS" BO_ 1349 "0";
BA_ "GenMsgCycleTime" BO_ 2527679722 200;
BA_ "GenMsgILSupport" BO_ 2527679722 "Yes";
BA_ "GenMsgSendType" BO_ 2527679722 "Cyclic";
BA_ "CANFD_BRS" BO_ 2527679722 "0";
BA_ "VFrameFormat" BO_ 2527679722 "ExtendedCAN";
BA_ "GenMsgCycleTime" BO_ 1633 100;
BA_ "GenMsgILSupport" BO_ 1633 "Yes";
BA_ "GenMsgSendType" BO_ 1633 "Cyclic";
BA_ "VFrameFormat" BO_ 1633 "StandardCAN_FD";
BA_ "GenMsgCycleTime" BO_ 345 100;
BA_ "GenMsgDelayTime" BO_ 345 10;
BA_ "GenMsgILSupport" BO_ 345 "Yes";
BA_ "GenMsgSendType" BO_ 345 "Cyclic";
BA_ "VFrameFormat" BO_ 345 "StandardCAN_FD";
BA_ "GenMsgCycleTime" BO_ 2589283607 200;
BA_ "GenMsgDelayTime" BO_ 2589283607 100;
BA_ "GenMsgILSupport" BO_ 2589283607 "Yes";
BA_ "GenMsgNrOfRepetition" BO_ 2589283607 5;
BA_ "GenMsgPDUConstants" BO_ 2589283607 "0xfb,0xee,0x5d,0x2d,0xfa,0x85,0x27,0xd4,0xc9,0xc4,0xa5,0x45,0x5f,0x76,0xa3,0x89";
BA_ "GenMsgSendType" BO_ 2589283607 "Cyclic";
BA_ "VFrameFormat" BO_ 2589283607 "ExtendedCAN_FD";
BA_ "GenMsgCycleTime" BO_ 219 1000;
BA_ "GenMsgCycleTimeFast" BO_ 219 20;
BA_ "GenMsgDelayTime" BO_ 219 20;
BA_ "GenMsgILSupport" BO_ 219 "Yes";
BA_ "GenMsgNrOfRepetition" BO_ 219 5;
BA_ "GenMsgPDUConstants" BO_ 219 "0x09,0xfa,0xca,0x8e,0x62,0xd5,0xd1,0xf0,0x31,0xa0,0xaf,0xda,0x4d,0x1a,0x0a,0x97";
BA_ "GenMsgSendType" BO_ 219 "Cyclic";
BA_ "VFrameFormat" BO_ 219 "StandardCAN_FD";
BA_ "MsgType" BO_ 2536767264 "BAP";
BA_ "VFrameFormat" BO_ 2536767264 "ExtendedCAN_FD";
BA_ "MsgType" BO_ 2536767280 "BAP";
BA_ "VFrameFormat" BO_ 2536767280 "ExtendedCAN_FD";
BA_ "GenMsgCycleTimeFast" BO_ 2536717313 80;
BA_ "GenMsgSendType" BO_ 2536717313 "IfActive";
BA_ "MsgType" BO_ 2536717313 "BAP";
BA_ "VFrameFormat" BO_ 2536717313 "ExtendedCAN_FD";
BA_ "GenMsgCycleTimeFast" BO_ 2536717314 80;
BA_ "GenMsgSendType" BO_ 2536717314 "IfActive";
BA_ "MsgType" BO_ 2536717314 "BAP";
BA_ "VFrameFormat" BO_ 2536717314 "ExtendedCAN_FD";
BA_ "GenMsgCycleTime" BO_ 2536717328 1000;
BA_ "GenMsgCycleTimeFast" BO_ 2536717328 50;
BA_ "GenMsgSendType" BO_ 2536717328 "IfActive";
BA_ "MsgType" BO_ 2536717328 "BAP";
BA_ "VFrameFormat" BO_ 2536717328 "ExtendedCAN_FD";
BA_ "GenMsgCycleTimeFast" BO_ 2536709120 80;
BA_ "GenMsgSendType" BO_ 2536709120 "IfActive";
BA_ "MsgType" BO_ 2536709120 "BAP";
BA_ "VFrameFormat" BO_ 2536709120 "ExtendedCAN_FD";
BA_ "GenMsgCycleTime" BO_ 2536709136 1000;
BA_ "GenMsgCycleTimeFast" BO_ 2536709136 50;
BA_ "GenMsgSendType" BO_ 2536709136 "IfActive";
BA_ "MsgType" BO_ 2536709136 "BAP";
BA_ "VFrameFormat" BO_ 2536709136 "ExtendedCAN_FD";
BA_ "GenMsgCycleTime" BO_ 869 50;
BA_ "GenMsgILSupport" BO_ 869 "Yes";
BA_ "GenMsgSendType" BO_ 869 "Cyclic";
BA_ "VFrameFormat" BO_ 869 "StandardCAN_FD";
BA_ "GenMsgCycleTime" BO_ 1442 500;
BA_ "GenMsgCycleTimeFast" BO_ 1442 100;
BA_ "GenMsgDelayTime" BO_ 1442 20;
BA_ "GenMsgILSupport" BO_ 1442 "Yes";
BA_ "GenMsgNrOfRepetition" BO_ 1442 5;
BA_ "GenMsgPDUConstants" BO_ 1442 "0xeb,0x4c,0x44,0xaf,0x21,0x8d,0x01,0x58,0xfa,0x93,0xdb,0x89,0x15,0x10,0x4a,0x61";
BA_ "GenMsgSendType" BO_ 1442 "Cyclic";
BA_ "VFrameFormat" BO_ 1442 "StandardCAN_FD";
BA_ "GenMsgCycleTime" BO_ 2527679654 200;
BA_ "GenMsgILSupport" BO_ 2527679654 "Yes";
BA_ "GenMsgPDUConstants" BO_ 2527679654 "0x79,0xb9,0x67,0xad,0xd5,0xf7,0x70,0xaa,0x44,0x61,0x5a,0xdc,0x26,0xb4,0xd2,0xc3";
BA_ "GenMsgSendType" BO_ 2527679654 "Cyclic";
BA_ "VFrameFormat" BO_ 2527679654 "ExtendedCAN_FD";
BA_ "GenMsgCycleTime" BO_ 207 10;
BA_ "GenMsgILSupport" BO_ 207 "Yes";
BA_ "GenMsgPDUConstants" BO_ 207 "0xee,0x80,0x6e,0x4e,0x29,0xc6,0x92,0xc0,0x65,0xaa,0x3a,0xa1,0x8f,0xcd,0xe6,0x90";
BA_ "GenMsgSendType" BO_ 207 "Cyclic";
BA_ "VFrameFormat" BO_ 207 "StandardCAN_FD";
BA_ "GenMsgCycleTime" BO_ 2463978704 100;
BA_ "GenMsgILSupport" BO_ 2463978704 "Yes";
BA_ "GenMsgSendType" BO_ 2463978704 "Cyclic";
BA_ "VFrameFormat" BO_ 2463978704 "ExtendedCAN_FD";
BA_ "GenMsgCycleTime" BO_ 2463978705 100;
BA_ "GenMsgILSupport" BO_ 2463978705 "Yes";
BA_ "GenMsgSendType" BO_ 2463978705 "Cyclic";
BA_ "VFrameFormat" BO_ 2463978705 "ExtendedCAN_FD";
BA_ "GenMsgCycleTime" BO_ 2589283664 500;
BA_ "GenMsgILSupport" BO_ 2589283664 "Yes";
BA_ "GenMsgSendType" BO_ 2589283664 "Cyclic";
BA_ "VFrameFormat" BO_ 2589283664 "ExtendedCAN_FD";
BA_ "GenMsgCycleTime" BO_ 2589283665 500;
BA_ "GenMsgILSupport" BO_ 2589283665 "Yes";
BA_ "GenMsgSendType" BO_ 2589283665 "Cyclic";
BA_ "VFrameFormat" BO_ 2589283665 "ExtendedCAN_FD";
BA_ "GenMsgCycleTime" BO_ 2589283760 1000;
BA_ "GenMsgILSupport" BO_ 2589283760 "Yes";
BA_ "GenMsgSendType" BO_ 2589283760 "Cyclic";
BA_ "VFrameFormat" BO_ 2589283760 "ExtendedCAN_FD";
BA_ "GenMsgCycleTime" BO_ 2463978646 1000;
BA_ "GenMsgDelayTime" BO_ 2463978646 50;
BA_ "GenMsgILSupport" BO_ 2463978646 "Yes";
BA_ "GenMsgSendType" BO_ 2463978646 "Cyclic";
BA_ "VFrameFormat" BO_ 2463978646 "ExtendedCAN_FD";
BA_ "GenMsgCycleTime" BO_ 514 20;
BA_ "GenMsgILSupport" BO_ 514 "Yes";
BA_ "GenMsgSendType" BO_ 514 "Cyclic";
BA_ "VFrameFormat" BO_ 514 "StandardCAN_FD";
BA_ "GenMsgCycleTime" BO_ 1485 500;
BA_ "GenMsgCycleTimeFast" BO_ 1485 100;
BA_ "GenMsgDelayTime" BO_ 1485 50;
BA_ "GenMsgILSupport" BO_ 1485 "Yes";
BA_ "GenMsgNrOfRepetition" BO_ 1485 5;
BA_ "GenMsgPDUConstants" BO_ 1485 "0x93,0x04,0x18,0x69,0xce,0x8f,0xb1,0x53,0x40,0x2d,0xe4,0xca,0x90,0x25,0x79,0x8c";
BA_ "GenMsgSendType" BO_ 1485 "Cyclic";
BA_ "VFrameFormat" BO_ 1485 "StandardCAN_FD";
BA_ "GenMsgCycleTime" BO_ 247 10;
BA_ "GenMsgILSupport" BO_ 247 "Yes";
BA_ "GenMsgPDUConstants" BO_ 247 "0x5f,0xa0,0x44,0xd0,0x63,0x59,0x5b,0xa2,0x68,0x04,0x90,0x87,0x52,0x12,0xb4,0x9e";
BA_ "GenMsgSendType" BO_ 247 "Cyclic";
BA_ "VFrameFormat" BO_ 247 "StandardCAN_FD";
BA_ "MsgType" BO_ 2617027088 "EID";
BA_ "CANFD_BRS" BO_ 2617027088 "0";
BA_ "VFrameFormat" BO_ 2617027088 "ExtendedCAN";
BA_ "MsgType" BO_ 2617027072 "EID";
BA_ "CANFD_BRS" BO_ 2617027072 "0";
BA_ "VFrameFormat" BO_ 2617027072 "ExtendedCAN";
BA_ "MsgType" BO_ 2617027073 "EID";
BA_ "CANFD_BRS" BO_ 2617027073 "0";
BA_ "VFrameFormat" BO_ 2617027073 "ExtendedCAN";
BA_ "MsgType" BO_ 2617027074 "EID";
BA_ "CANFD_BRS" BO_ 2617027074 "0";
BA_ "VFrameFormat" BO_ 2617027074 "ExtendedCAN";
BA_ "MsgType" BO_ 2617027075 "EID";
BA_ "CANFD_BRS" BO_ 2617027075 "0";
BA_ "VFrameFormat" BO_ 2617027075 "ExtendedCAN";
BA_ "MsgType" BO_ 2617027076 "EID";
BA_ "CANFD_BRS" BO_ 2617027076 "0";
BA_ "VFrameFormat" BO_ 2617027076 "ExtendedCAN";
BA_ "MsgType" BO_ 2617027077 "EID";
BA_ "CANFD_BRS" BO_ 2617027077 "0";
BA_ "VFrameFormat" BO_ 2617027077 "ExtendedCAN";
BA_ "MsgType" BO_ 2617027078 "EID";
BA_ "CANFD_BRS" BO_ 2617027078 "0";
BA_ "VFrameFormat" BO_ 2617027078 "ExtendedCAN";
BA_ "MsgType" BO_ 2617027079 "EID";
BA_ "CANFD_BRS" BO_ 2617027079 "0";
BA_ "VFrameFormat" BO_ 2617027079 "ExtendedCAN";
BA_ "MsgType" BO_ 2617027080 "EID";
BA_ "CANFD_BRS" BO_ 2617027080 "0";
BA_ "VFrameFormat" BO_ 2617027080 "ExtendedCAN";
BA_ "MsgType" BO_ 2617027081 "EID";
BA_ "CANFD_BRS" BO_ 2617027081 "0";
BA_ "VFrameFormat" BO_ 2617027081 "ExtendedCAN";
BA_ "MsgType" BO_ 2617027082 "EID";
BA_ "CANFD_BRS" BO_ 2617027082 "0";
BA_ "VFrameFormat" BO_ 2617027082 "ExtendedCAN";
BA_ "MsgType" BO_ 2617027083 "EID";
BA_ "CANFD_BRS" BO_ 2617027083 "0";
BA_ "VFrameFormat" BO_ 2617027083 "ExtendedCAN";
BA_ "MsgType" BO_ 2617154048 "EID";
BA_ "VFrameFormat" BO_ 2617154048 "ExtendedCAN_FD";
BA_ "MsgType" BO_ 2617154049 "EID";
BA_ "VFrameFormat" BO_ 2617154049 "ExtendedCAN_FD";
BA_ "MsgType" BO_ 2617154050 "EID";
BA_ "VFrameFormat" BO_ 2617154050 "ExtendedCAN_FD";
BA_ "MsgType" BO_ 2617154051 "EID";
BA_ "VFrameFormat" BO_ 2617154051 "ExtendedCAN_FD";
BA_ "MsgType" BO_ 2617154052 "EID";
BA_ "VFrameFormat" BO_ 2617154052 "ExtendedCAN_FD";
BA_ "MsgType" BO_ 2617154053 "EID";
BA_ "VFrameFormat" BO_ 2617154053 "ExtendedCAN_FD";
BA_ "DiagRequest" BO_ 2549876269 "Yes";
BA_ "MsgType" BO_ 2549876269 "ISO-TP";
BA_ "VFrameFormat" BO_ 2549876269 "ExtendedCAN_FD";
BA_ "DiagResponse" BO_ 2550007341 "Yes";
BA_ "MsgType" BO_ 2550007341 "ISO-TP";
BA_ "VFrameFormat" BO_ 2550007341 "ExtendedCAN_FD";
BA_ "GenMsgCycleTime" BO_ 1714 1000;
BA_ "GenMsgILSupport" BO_ 1714 "Yes";
BA_ "GenMsgSendType" BO_ 1714 "Cyclic";
BA_ "VFrameFormat" BO_ 1714 "StandardCAN_FD";
BA_ "GenMsgCycleTime" BO_ 851 80;
BA_ "GenMsgILSupport" BO_ 851 "Yes";
BA_ "GenMsgPDUConstants" BO_ 851 "0x3a,0x97,0x6b,0x70,0x1e,0x84,0xe1,0xb4,0xde,0xb8,0x03,0xe7,0x33,0x20,0x3f,0x7c";
BA_ "GenMsgSendType" BO_ 851 "Cyclic";
BA_ "VFrameFormat" BO_ 851 "StandardCAN_FD";
BA_ "GenMsgCycleTime" BO_ 1520 200;
BA_ "GenMsgDelayTime" BO_ 1520 50;
BA_ "GenMsgILSupport" BO_ 1520 "Yes";
BA_ "GenMsgSendType" BO_ 1520 "Cyclic";
BA_ "VFrameFormat" BO_ 1520 "StandardCAN_FD";
BA_ "GenMsgCycleTime" BO_ 420 500;
BA_ "GenMsgCycleTimeFast" BO_ 420 20;
BA_ "GenMsgDelayTime" BO_ 420 20;
BA_ "GenMsgILSupport" BO_ 420 "Yes";
BA_ "GenMsgNrOfRepetition" BO_ 420 5;
BA_ "GenMsgPDUConstants" BO_ 420 "0x69,0xbb,0x54,0xe6,0x4e,0x46,0x8d,0x7b,0xea,0x87,0xe9,0xb3,0x63,0xce,0xf8,0xbf";
BA_ "GenMsgSendType" BO_ 420 "Cyclic";
BA_ "VFrameFormat" BO_ 420 "StandardCAN_FD";
BA_ "GenMsgCycleTime" BO_ 374 20;
BA_ "GenMsgILSupport" BO_ 374 "Yes";
BA_ "GenMsgPDUConstants" BO_ 374 "0x3c,0x60,0xeb,0x76,0x91,0x27,0x04,0x02,0xa4,0x3a,0x3f,0xa8,0x24,0x32,0x38,0x51";
BA_ "GenMsgSendType" BO_ 374 "Cyclic";
BA_ "VFrameFormat" BO_ 374 "StandardCAN_FD";
BA_ "GenMsgCycleTime" BO_ 1603 1000;
BA_ "GenMsgDelayTime" BO_ 1603 100;
BA_ "GenMsgILSupport" BO_ 1603 "Yes";
BA_ "GenMsgSendType" BO_ 1603 "Cyclic";
BA_ "VFrameFormat" BO_ 1603 "StandardCAN_FD";
BA_ "GenMsgCycleTime" BO_ 192 10;
BA_ "GenMsgILSupport" BO_ 192 "Yes";
BA_ "GenMsgPDUConstants" BO_ 192 "0x2f,0x44,0x72,0xd3,0x07,0xf2,0x39,0x09,0x8d,0x6f,0x57,0x20,0x37,0xf9,0x9b,0xfa";
BA_ "GenMsgSendType" BO_ 192 "Cyclic";
BA_ "VFrameFormat" BO_ 192 "StandardCAN_FD";
BA_ "GenMsgCycleTime" BO_ 2463978673 100;
BA_ "GenMsgILSupport" BO_ 2463978673 "Yes";
BA_ "GenMsgSendType" BO_ 2463978673 "Cyclic";
BA_ "VFrameFormat" BO_ 2463978673 "ExtendedCAN_FD";
BA_ "GenMsgCycleTime" BO_ 2589283657 500;
BA_ "GenMsgILSupport" BO_ 2589283657 "Yes";
BA_ "GenMsgSendType" BO_ 2589283657 "Cyclic";
BA_ "VFrameFormat" BO_ 2589283657 "ExtendedCAN_FD";
BA_ "GenMsgCycleTime" BO_ 184 500;
BA_ "GenMsgDelayTime" BO_ 184 20;
BA_ "GenMsgILSupport" BO_ 184 "Yes";
BA_ "GenMsgSendType" BO_ 184 "Cyclic";
BA_ "VFrameFormat" BO_ 184 "StandardCAN_FD";
BA_ "GenMsgCycleTime" BO_ 2527679712 1000;
BA_ "GenMsgILSupport" BO_ 2527679712 "Yes";
BA_ "GenMsgSendType" BO_ 2527679712 "Cyclic";
BA_ "VFrameFormat" BO_ 2527679712 "ExtendedCAN_FD";
BA_ "GenMsgCycleTime" BO_ 193 10;
BA_ "GenMsgILSupport" BO_ 193 "Yes";
BA_ "GenMsgPDUConstants" BO_ 193 "0xd7,0x12,0x85,0x7e,0x0b,0x34,0xfa,0x16,0x7a,0x25,0x2d,0x8f,0x04,0x8e,0x5d,0x35";
BA_ "GenMsgSendType" BO_ 193 "Cyclic";
BA_ "VFrameFormat" BO_ 193 "StandardCAN_FD";
BA_ "GenMsgCycleTime" BO_ 2463978674 100;
BA_ "GenMsgILSupport" BO_ 2463978674 "Yes";
BA_ "GenMsgSendType" BO_ 2463978674 "Cyclic";
BA_ "VFrameFormat" BO_ 2463978674 "ExtendedCAN_FD";
BA_ "GenMsgCycleTime" BO_ 2589283660 500;
BA_ "GenMsgILSupport" BO_ 2589283660 "Yes";
BA_ "GenMsgSendType" BO_ 2589283660 "Cyclic";
BA_ "VFrameFormat" BO_ 2589283660 "ExtendedCAN_FD";
BA_ "GenMsgCycleTime" BO_ 199 500;
BA_ "GenMsgDelayTime" BO_ 199 20;
BA_ "GenMsgILSupport" BO_ 199 "Yes";
BA_ "GenMsgSendType" BO_ 199 "Cyclic";
BA_ "VFrameFormat" BO_ 199 "StandardCAN_FD";
BA_ "GenMsgCycleTime" BO_ 2527679713 1000;
BA_ "GenMsgILSupport" BO_ 2527679713 "Yes";
BA_ "GenMsgSendType" BO_ 2527679713 "Cyclic";
BA_ "VFrameFormat" BO_ 2527679713 "ExtendedCAN_FD";
BA_ "GenMsgCycleTime" BO_ 2589283649 200;
BA_ "GenMsgILSupport" BO_ 2589283649 "Yes";
BA_ "GenMsgPDUConstants" BO_ 2589283649 "0x3e,0xb4,0x25,0xc1,0x31,0x1f,0xf1,0xd7,0xb1,0xbe,0xcc,0xe0,0x0f,0x46,0x51,0xb2";
BA_ "GenMsgSendType" BO_ 2589283649 "Cyclic";
BA_ "VFrameFormat" BO_ 2589283649 "ExtendedCAN_FD";
BA_ "GenMsgCycleTime" BO_ 608 50;
BA_ "GenMsgILSupport" BO_ 608 "Yes";
BA_ "GenMsgSendType" BO_ 608 "Cyclic";
BA_ "VFrameFormat" BO_ 608 "StandardCAN_FD";
BA_ "GenMsgCycleTime" BO_ 2589283751 500;
BA_ "GenMsgILSupport" BO_ 2589283751 "Yes";
BA_ "GenMsgSendType" BO_ 2589283751 "Cyclic";
BA_ "VFrameFormat" BO_ 2589283751 "ExtendedCAN_FD";
BA_ "GenMsgCycleTime" BO_ 2527679687 2000;
BA_ "GenMsgDelayTime" BO_ 2527679687 100;
BA_ "GenMsgILSupport" BO_ 2527679687 "Yes";
BA_ "GenMsgSendType" BO_ 2527679687 "Cyclic";
BA_ "VFrameFormat" BO_ 2527679687 "ExtendedCAN_FD";
BA_ "GenMsgCycleTime" BO_ 258 20;
BA_ "GenMsgILSupport" BO_ 258 "Yes";
BA_ "GenMsgPDUConstants" BO_ 258 "0xd7,0x12,0x85,0x7e,0x0b,0x34,0xfa,0x16,0x7a,0x25,0x2d,0x8f,0x04,0x8e,0x5d,0x35";
BA_ "GenMsgSendType" BO_ 258 "Cyclic";
BA_ "VFrameFormat" BO_ 258 "StandardCAN_FD";
BA_ "GenMsgCycleTime" BO_ 252 10;
BA_ "GenMsgILSupport" BO_ 252 "Yes";
BA_ "GenMsgPDUConstants" BO_ 252 "0x77,0x5c,0xa0,0x89,0x4b,0x7c,0xbb,0xd6,0x1f,0x6c,0x4f,0xf6,0x20,0x2b,0x43,0xdd";
BA_ "GenMsgSendType" BO_ 252 "Cyclic";
BA_ "VFrameFormat" BO_ 252 "StandardCAN_FD";
BA_ "GenMsgCycleTime" BO_ 2463978647 100;
BA_ "GenMsgILSupport" BO_ 2463978647 "Yes";
BA_ "GenMsgSendType" BO_ 2463978647 "Cyclic";
BA_ "VFrameFormat" BO_ 2463978647 "ExtendedCAN_FD";
BA_ "GenMsgCycleTime" BO_ 2527679683 2000;
BA_ "GenMsgDelayTime" BO_ 2527679683 100;
BA_ "GenMsgILSupport" BO_ 2527679683 "Yes";
BA_ "GenMsgSendType" BO_ 2527679683 "Cyclic";
BA_ "VFrameFormat" BO_ 2527679683 "ExtendedCAN_FD";
BA_ "GenMsgChkConstant" BO_ 278 172;
BA_ "GenMsgCycleTime" BO_ 278 20;
BA_ "GenMsgILSupport" BO_ 278 "Yes";
BA_ "GenMsgPDUConstants" BO_ 278 "0xac,0xac,0xac,0xac,0xac,0xac,0xac,0xac,0xac,0xac,0xac,0xac,0xac,0xac,0xac,0xac";
BA_ "GenMsgSendType" BO_ 278 "Cyclic";
BA_ "VFrameFormat" BO_ 278 "StandardCAN_FD";
BA_ "GenMsgCycleTime" BO_ 333 20;
BA_ "GenMsgILSupport" BO_ 333 "Yes";
BA_ "GenMsgPDUConstants" BO_ 333 "0x1a,0x65,0x81,0x96,0xc0,0xdf,0x11,0x92,0xd3,0x61,0xc6,0x95,0x8c,0x29,0x21,0xb5";
BA_ "GenMsgSendType" BO_ 333 "Cyclic";
BA_ "VFrameFormat" BO_ 333 "StandardCAN_FD";
BA_ "GenMsgCycleTime" BO_ 2527679682 2000;
BA_ "GenMsgDelayTime" BO_ 2527679682 100;
BA_ "GenMsgILSupport" BO_ 2527679682 "Yes";
BA_ "GenMsgSendType" BO_ 2527679682 "Cyclic";
BA_ "VFrameFormat" BO_ 2527679682 "ExtendedCAN_FD";
BA_ "GenMsgChkConstant" BO_ 64 64;
BA_ "GenMsgCycleTime" BO_ 64 40;
BA_ "GenMsgCycleTimeFast" BO_ 64 10;
BA_ "GenMsgDelayTime" BO_ 64 10;
BA_ "GenMsgILSupport" BO_ 64 "Yes";
BA_ "GenMsgNrOfRepetition" BO_ 64 5;
BA_ "GenMsgPDUConstants" BO_ 64 "0x40,0x40,0x40,0x40,0x40,0x40,0x40,0x40,0x40,0x40,0x40,0x40,0x40,0x40,0x40,0x40";
BA_ "GenMsgSendType" BO_ 64 "Cyclic";
BA_ "CANFD_BRS" BO_ 64 "0";
BA_ "GenMsgChkConstant" BO_ 1312 68;
BA_ "GenMsgCycleTime" BO_ 1312 200;
BA_ "GenMsgDelayTime" BO_ 1312 20;
BA_ "GenMsgILSupport" BO_ 1312 "Yes";
BA_ "GenMsgPDUConstants" BO_ 1312 "0x44,0x44,0x44,0x44,0x44,0x44,0x44,0x44,0x44,0x44,0x44,0x44,0x44,0x44,0x44,0x44";
BA_ "GenMsgSendType" BO_ 1312 "Cyclic";
BA_ "CANFD_BRS" BO_ 1312 "0";
BA_ "GenMsgCycleTime" BO_ 65 1000;
BA_ "GenMsgCycleTimeFast" BO_ 65 10;
BA_ "GenMsgDelayTime" BO_ 65 10;
BA_ "GenMsgILSupport" BO_ 65 "Yes";
BA_ "GenMsgNrOfRepetition" BO_ 65 5;
BA_ "GenMsgPDUConstants" BO_ 65 "0x93,0xb0,0x9d,0xf1,0x09,0xe8,0x88,0x5e,0x36,0xfa,0xa8,0xa1,0x67,0x84,0xca,0x4f";
BA_ "GenMsgSendType" BO_ 65 "Cyclic";
BA_ "CANFD_BRS" BO_ 65 "0";
BA_ "GenMsgCycleTime" BO_ 1349 200;
BA_ "GenMsgDelayTime" BO_ 1349 40;
BA_ "GenMsgILSupport" BO_ 1349 "Yes";
BA_ "GenMsgSendType" BO_ 1349 "Cyclic";
BA_ "CANFD_BRS" BO_ 1349 "0";
BA_ "GenMsgCycleTime" BO_ 2527679722 200;
BA_ "GenMsgILSupport" BO_ 2527679722 "Yes";
BA_ "GenMsgSendType" BO_ 2527679722 "Cyclic";
BA_ "CANFD_BRS" BO_ 2527679722 "0";
BA_ "VFrameFormat" BO_ 2527679722 "ExtendedCAN";
BA_ "GenMsgCycleTime" BO_ 1633 100;
BA_ "GenMsgILSupport" BO_ 1633 "Yes";
BA_ "GenMsgSendType" BO_ 1633 "Cyclic";
BA_ "VFrameFormat" BO_ 1633 "StandardCAN_FD";
BA_ "GenMsgCycleTime" BO_ 345 100;
BA_ "GenMsgDelayTime" BO_ 345 10;
BA_ "GenMsgILSupport" BO_ 345 "Yes";
BA_ "GenMsgSendType" BO_ 345 "Cyclic";
BA_ "VFrameFormat" BO_ 345 "StandardCAN_FD";
BA_ "GenMsgCycleTime" BO_ 2589283607 200;
BA_ "GenMsgDelayTime" BO_ 2589283607 100;
BA_ "GenMsgILSupport" BO_ 2589283607 "Yes";
BA_ "GenMsgNrOfRepetition" BO_ 2589283607 5;
BA_ "GenMsgPDUConstants" BO_ 2589283607 "0xfb,0xee,0x5d,0x2d,0xfa,0x85,0x27,0xd4,0xc9,0xc4,0xa5,0x45,0x5f,0x76,0xa3,0x89";
BA_ "GenMsgSendType" BO_ 2589283607 "Cyclic";
BA_ "VFrameFormat" BO_ 2589283607 "ExtendedCAN_FD";
BA_ "GenMsgCycleTime" BO_ 219 1000;
BA_ "GenMsgCycleTimeFast" BO_ 219 20;
BA_ "GenMsgDelayTime" BO_ 219 20;
BA_ "GenMsgILSupport" BO_ 219 "Yes";
BA_ "GenMsgNrOfRepetition" BO_ 219 5;
BA_ "GenMsgPDUConstants" BO_ 219 "0x09,0xfa,0xca,0x8e,0x62,0xd5,0xd1,0xf0,0x31,0xa0,0xaf,0xda,0x4d,0x1a,0x0a,0x97";
BA_ "GenMsgSendType" BO_ 219 "Cyclic";
BA_ "VFrameFormat" BO_ 219 "StandardCAN_FD";
BA_ "MsgType" BO_ 2536767264 "BAP";
BA_ "VFrameFormat" BO_ 2536767264 "ExtendedCAN_FD";
BA_ "MsgType" BO_ 2536767280 "BAP";
BA_ "VFrameFormat" BO_ 2536767280 "ExtendedCAN_FD";
BA_ "GenMsgCycleTimeFast" BO_ 2536717313 80;
BA_ "GenMsgSendType" BO_ 2536717313 "IfActive";
BA_ "MsgType" BO_ 2536717313 "BAP";
BA_ "VFrameFormat" BO_ 2536717313 "ExtendedCAN_FD";
BA_ "GenMsgCycleTimeFast" BO_ 2536717314 80;
BA_ "GenMsgSendType" BO_ 2536717314 "IfActive";
BA_ "MsgType" BO_ 2536717314 "BAP";
BA_ "VFrameFormat" BO_ 2536717314 "ExtendedCAN_FD";
BA_ "GenMsgCycleTime" BO_ 2536717328 1000;
BA_ "GenMsgCycleTimeFast" BO_ 2536717328 50;
BA_ "GenMsgSendType" BO_ 2536717328 "IfActive";
BA_ "MsgType" BO_ 2536717328 "BAP";
BA_ "VFrameFormat" BO_ 2536717328 "ExtendedCAN_FD";
BA_ "GenMsgCycleTimeFast" BO_ 2536709120 80;
BA_ "GenMsgSendType" BO_ 2536709120 "IfActive";
BA_ "MsgType" BO_ 2536709120 "BAP";
BA_ "VFrameFormat" BO_ 2536709120 "ExtendedCAN_FD";
BA_ "GenMsgCycleTime" BO_ 2536709136 1000;
BA_ "GenMsgCycleTimeFast" BO_ 2536709136 50;
BA_ "GenMsgSendType" BO_ 2536709136 "IfActive";
BA_ "MsgType" BO_ 2536709136 "BAP";
BA_ "VFrameFormat" BO_ 2536709136 "ExtendedCAN_FD";
BA_ "GenMsgCycleTime" BO_ 869 50;
BA_ "GenMsgILSupport" BO_ 869 "Yes";
BA_ "GenMsgSendType" BO_ 869 "Cyclic";
BA_ "VFrameFormat" BO_ 869 "StandardCAN_FD";
BA_ "GenMsgCycleTime" BO_ 1442 500;
BA_ "GenMsgCycleTimeFast" BO_ 1442 100;
BA_ "GenMsgDelayTime" BO_ 1442 20;
BA_ "GenMsgILSupport" BO_ 1442 "Yes";
BA_ "GenMsgNrOfRepetition" BO_ 1442 5;
BA_ "GenMsgPDUConstants" BO_ 1442 "0xeb,0x4c,0x44,0xaf,0x21,0x8d,0x01,0x58,0xfa,0x93,0xdb,0x89,0x15,0x10,0x4a,0x61";
BA_ "GenMsgSendType" BO_ 1442 "Cyclic";
BA_ "VFrameFormat" BO_ 1442 "StandardCAN_FD";
BA_ "GenMsgCycleTime" BO_ 2527679654 200;
BA_ "GenMsgILSupport" BO_ 2527679654 "Yes";
BA_ "GenMsgPDUConstants" BO_ 2527679654 "0x79,0xb9,0x67,0xad,0xd5,0xf7,0x70,0xaa,0x44,0x61,0x5a,0xdc,0x26,0xb4,0xd2,0xc3";
BA_ "GenMsgSendType" BO_ 2527679654 "Cyclic";
BA_ "VFrameFormat" BO_ 2527679654 "ExtendedCAN_FD";
BA_ "GenMsgCycleTime" BO_ 207 10;
BA_ "GenMsgILSupport" BO_ 207 "Yes";
BA_ "GenMsgPDUConstants" BO_ 207 "0xee,0x80,0x6e,0x4e,0x29,0xc6,0x92,0xc0,0x65,0xaa,0x3a,0xa1,0x8f,0xcd,0xe6,0x90";
BA_ "GenMsgSendType" BO_ 207 "Cyclic";
BA_ "VFrameFormat" BO_ 207 "StandardCAN_FD";
BA_ "GenMsgCycleTime" BO_ 2463978704 100;
BA_ "GenMsgILSupport" BO_ 2463978704 "Yes";
BA_ "GenMsgSendType" BO_ 2463978704 "Cyclic";
BA_ "VFrameFormat" BO_ 2463978704 "ExtendedCAN_FD";
BA_ "GenMsgCycleTime" BO_ 2463978705 100;
BA_ "GenMsgILSupport" BO_ 2463978705 "Yes";
BA_ "GenMsgSendType" BO_ 2463978705 "Cyclic";
BA_ "VFrameFormat" BO_ 2463978705 "ExtendedCAN_FD";
BA_ "GenMsgCycleTime" BO_ 2589283664 500;
BA_ "GenMsgILSupport" BO_ 2589283664 "Yes";
BA_ "GenMsgSendType" BO_ 2589283664 "Cyclic";
BA_ "VFrameFormat" BO_ 2589283664 "ExtendedCAN_FD";
BA_ "GenMsgCycleTime" BO_ 2589283665 500;
BA_ "GenMsgILSupport" BO_ 2589283665 "Yes";
BA_ "GenMsgSendType" BO_ 2589283665 "Cyclic";
BA_ "VFrameFormat" BO_ 2589283665 "ExtendedCAN_FD";
BA_ "GenMsgCycleTime" BO_ 2589283760 1000;
BA_ "GenMsgILSupport" BO_ 2589283760 "Yes";
BA_ "GenMsgSendType" BO_ 2589283760 "Cyclic";
BA_ "VFrameFormat" BO_ 2589283760 "ExtendedCAN_FD";
BA_ "GenMsgCycleTime" BO_ 2463978646 1000;
BA_ "GenMsgDelayTime" BO_ 2463978646 50;
BA_ "GenMsgILSupport" BO_ 2463978646 "Yes";
BA_ "GenMsgSendType" BO_ 2463978646 "Cyclic";
BA_ "VFrameFormat" BO_ 2463978646 "ExtendedCAN_FD";
BA_ "GenMsgCycleTime" BO_ 514 20;
BA_ "GenMsgILSupport" BO_ 514 "Yes";
BA_ "GenMsgSendType" BO_ 514 "Cyclic";
BA_ "VFrameFormat" BO_ 514 "StandardCAN_FD";
BA_ "GenMsgCycleTime" BO_ 1485 500;
BA_ "GenMsgCycleTimeFast" BO_ 1485 100;
BA_ "GenMsgDelayTime" BO_ 1485 50;
BA_ "GenMsgILSupport" BO_ 1485 "Yes";
BA_ "GenMsgNrOfRepetition" BO_ 1485 5;
BA_ "GenMsgPDUConstants" BO_ 1485 "0x93,0x04,0x18,0x69,0xce,0x8f,0xb1,0x53,0x40,0x2d,0xe4,0xca,0x90,0x25,0x79,0x8c";
BA_ "GenMsgSendType" BO_ 1485 "Cyclic";
BA_ "VFrameFormat" BO_ 1485 "StandardCAN_FD";
BA_ "GenMsgCycleTime" BO_ 247 10;
BA_ "GenMsgILSupport" BO_ 247 "Yes";
BA_ "GenMsgPDUConstants" BO_ 247 "0x5f,0xa0,0x44,0xd0,0x63,0x59,0x5b,0xa2,0x68,0x04,0x90,0x87,0x52,0x12,0xb4,0x9e";
BA_ "GenMsgSendType" BO_ 247 "Cyclic";
BA_ "VFrameFormat" BO_ 247 "StandardCAN_FD";
BA_ "MsgType" BO_ 2617027088 "EID";
BA_ "CANFD_BRS" BO_ 2617027088 "0";
BA_ "VFrameFormat" BO_ 2617027088 "ExtendedCAN";
BA_ "MsgType" BO_ 2617027072 "EID";
BA_ "CANFD_BRS" BO_ 2617027072 "0";
BA_ "VFrameFormat" BO_ 2617027072 "ExtendedCAN";
BA_ "MsgType" BO_ 2617027073 "EID";
BA_ "CANFD_BRS" BO_ 2617027073 "0";
BA_ "VFrameFormat" BO_ 2617027073 "ExtendedCAN";
BA_ "MsgType" BO_ 2617027074 "EID";
BA_ "CANFD_BRS" BO_ 2617027074 "0";
BA_ "VFrameFormat" BO_ 2617027074 "ExtendedCAN";
BA_ "MsgType" BO_ 2617027075 "EID";
BA_ "CANFD_BRS" BO_ 2617027075 "0";
BA_ "VFrameFormat" BO_ 2617027075 "ExtendedCAN";
BA_ "MsgType" BO_ 2617027076 "EID";
BA_ "CANFD_BRS" BO_ 2617027076 "0";
BA_ "VFrameFormat" BO_ 2617027076 "ExtendedCAN";
BA_ "MsgType" BO_ 2617027077 "EID";
BA_ "CANFD_BRS" BO_ 2617027077 "0";
BA_ "VFrameFormat" BO_ 2617027077 "ExtendedCAN";
BA_ "MsgType" BO_ 2617027078 "EID";
BA_ "CANFD_BRS" BO_ 2617027078 "0";
BA_ "VFrameFormat" BO_ 2617027078 "ExtendedCAN";
BA_ "MsgType" BO_ 2617027079 "EID";
BA_ "CANFD_BRS" BO_ 2617027079 "0";
BA_ "VFrameFormat" BO_ 2617027079 "ExtendedCAN";
BA_ "MsgType" BO_ 2617027080 "EID";
BA_ "CANFD_BRS" BO_ 2617027080 "0";
BA_ "VFrameFormat" BO_ 2617027080 "ExtendedCAN";
BA_ "MsgType" BO_ 2617027081 "EID";
BA_ "CANFD_BRS" BO_ 2617027081 "0";
BA_ "VFrameFormat" BO_ 2617027081 "ExtendedCAN";
BA_ "MsgType" BO_ 2617027082 "EID";
BA_ "CANFD_BRS" BO_ 2617027082 "0";
BA_ "VFrameFormat" BO_ 2617027082 "ExtendedCAN";
BA_ "MsgType" BO_ 2617027083 "EID";
BA_ "CANFD_BRS" BO_ 2617027083 "0";
BA_ "VFrameFormat" BO_ 2617027083 "ExtendedCAN";
BA_ "MsgType" BO_ 2617154048 "EID";
BA_ "VFrameFormat" BO_ 2617154048 "ExtendedCAN_FD";
BA_ "MsgType" BO_ 2617154049 "EID";
BA_ "VFrameFormat" BO_ 2617154049 "ExtendedCAN_FD";
BA_ "MsgType" BO_ 2617154050 "EID";
BA_ "VFrameFormat" BO_ 2617154050 "ExtendedCAN_FD";
BA_ "MsgType" BO_ 2617154051 "EID";
BA_ "VFrameFormat" BO_ 2617154051 "ExtendedCAN_FD";
BA_ "MsgType" BO_ 2617154052 "EID";
BA_ "VFrameFormat" BO_ 2617154052 "ExtendedCAN_FD";
BA_ "MsgType" BO_ 2617154053 "EID";
BA_ "VFrameFormat" BO_ 2617154053 "ExtendedCAN_FD";
BA_ "DiagRequest" BO_ 2549876269 "Yes";
BA_ "MsgType" BO_ 2549876269 "ISO-TP";
BA_ "VFrameFormat" BO_ 2549876269 "ExtendedCAN_FD";
BA_ "DiagResponse" BO_ 2550007341 "Yes";
BA_ "MsgType" BO_ 2550007341 "ISO-TP";
BA_ "VFrameFormat" BO_ 2550007341 "ExtendedCAN_FD";
BA_ "GenMsgCycleTime" BO_ 1714 1000;
BA_ "GenMsgILSupport" BO_ 1714 "Yes";
BA_ "GenMsgSendType" BO_ 1714 "Cyclic";
BA_ "VFrameFormat" BO_ 1714 "StandardCAN_FD";
BA_ "GenMsgCycleTime" BO_ 851 80;
BA_ "GenMsgILSupport" BO_ 851 "Yes";
BA_ "GenMsgPDUConstants" BO_ 851 "0x3a,0x97,0x6b,0x70,0x1e,0x84,0xe1,0xb4,0xde,0xb8,0x03,0xe7,0x33,0x20,0x3f,0x7c";
BA_ "GenMsgSendType" BO_ 851 "Cyclic";
BA_ "VFrameFormat" BO_ 851 "StandardCAN_FD";
BA_ "GenMsgCycleTime" BO_ 1520 200;
BA_ "GenMsgDelayTime" BO_ 1520 50;
BA_ "GenMsgILSupport" BO_ 1520 "Yes";
BA_ "GenMsgSendType" BO_ 1520 "Cyclic";
BA_ "VFrameFormat" BO_ 1520 "StandardCAN_FD";
BA_ "GenMsgCycleTime" BO_ 420 500;
BA_ "GenMsgCycleTimeFast" BO_ 420 20;
BA_ "GenMsgDelayTime" BO_ 420 20;
BA_ "GenMsgILSupport" BO_ 420 "Yes";
BA_ "GenMsgNrOfRepetition" BO_ 420 5;
BA_ "GenMsgPDUConstants" BO_ 420 "0x69,0xbb,0x54,0xe6,0x4e,0x46,0x8d,0x7b,0xea,0x87,0xe9,0xb3,0x63,0xce,0xf8,0xbf";
BA_ "GenMsgSendType" BO_ 420 "Cyclic";
BA_ "VFrameFormat" BO_ 420 "StandardCAN_FD";
BA_ "GenMsgCycleTime" BO_ 374 20;
BA_ "GenMsgILSupport" BO_ 374 "Yes";
BA_ "GenMsgPDUConstants" BO_ 374 "0x3c,0x60,0xeb,0x76,0x91,0x27,0x04,0x02,0xa4,0x3a,0x3f,0xa8,0x24,0x32,0x38,0x51";
BA_ "GenMsgSendType" BO_ 374 "Cyclic";
BA_ "VFrameFormat" BO_ 374 "StandardCAN_FD";
BA_ "GenMsgCycleTime" BO_ 1603 1000;
BA_ "GenMsgDelayTime" BO_ 1603 100;
BA_ "GenMsgILSupport" BO_ 1603 "Yes";
BA_ "GenMsgSendType" BO_ 1603 "Cyclic";
BA_ "VFrameFormat" BO_ 1603 "StandardCAN_FD";
BA_ "GenMsgCycleTime" BO_ 192 10;
BA_ "GenMsgILSupport" BO_ 192 "Yes";
BA_ "GenMsgPDUConstants" BO_ 192 "0x2f,0x44,0x72,0xd3,0x07,0xf2,0x39,0x09,0x8d,0x6f,0x57,0x20,0x37,0xf9,0x9b,0xfa";
BA_ "GenMsgSendType" BO_ 192 "Cyclic";
BA_ "VFrameFormat" BO_ 192 "StandardCAN_FD";
BA_ "GenMsgCycleTime" BO_ 2463978673 100;
BA_ "GenMsgILSupport" BO_ 2463978673 "Yes";
BA_ "GenMsgSendType" BO_ 2463978673 "Cyclic";
BA_ "VFrameFormat" BO_ 2463978673 "ExtendedCAN_FD";
BA_ "GenMsgCycleTime" BO_ 2589283657 500;
BA_ "GenMsgILSupport" BO_ 2589283657 "Yes";
BA_ "GenMsgSendType" BO_ 2589283657 "Cyclic";
BA_ "VFrameFormat" BO_ 2589283657 "ExtendedCAN_FD";
BA_ "GenMsgCycleTime" BO_ 184 500;
BA_ "GenMsgDelayTime" BO_ 184 20;
BA_ "GenMsgILSupport" BO_ 184 "Yes";
BA_ "GenMsgSendType" BO_ 184 "Cyclic";
BA_ "VFrameFormat" BO_ 184 "StandardCAN_FD";
BA_ "GenMsgCycleTime" BO_ 2527679712 1000;
BA_ "GenMsgILSupport" BO_ 2527679712 "Yes";
BA_ "GenMsgSendType" BO_ 2527679712 "Cyclic";
BA_ "VFrameFormat" BO_ 2527679712 "ExtendedCAN_FD";
BA_ "GenMsgCycleTime" BO_ 193 10;
BA_ "GenMsgILSupport" BO_ 193 "Yes";
BA_ "GenMsgPDUConstants" BO_ 193 "0xd7,0x12,0x85,0x7e,0x0b,0x34,0xfa,0x16,0x7a,0x25,0x2d,0x8f,0x04,0x8e,0x5d,0x35";
BA_ "GenMsgSendType" BO_ 193 "Cyclic";
BA_ "VFrameFormat" BO_ 193 "StandardCAN_FD";
BA_ "GenMsgCycleTime" BO_ 2463978674 100;
BA_ "GenMsgILSupport" BO_ 2463978674 "Yes";
BA_ "GenMsgSendType" BO_ 2463978674 "Cyclic";
BA_ "VFrameFormat" BO_ 2463978674 "ExtendedCAN_FD";
BA_ "GenMsgCycleTime" BO_ 2589283660 500;
BA_ "GenMsgILSupport" BO_ 2589283660 "Yes";
BA_ "GenMsgSendType" BO_ 2589283660 "Cyclic";
BA_ "VFrameFormat" BO_ 2589283660 "ExtendedCAN_FD";
BA_ "GenMsgCycleTime" BO_ 199 500;
BA_ "GenMsgDelayTime" BO_ 199 20;
BA_ "GenMsgILSupport" BO_ 199 "Yes";
BA_ "GenMsgSendType" BO_ 199 "Cyclic";
BA_ "VFrameFormat" BO_ 199 "StandardCAN_FD";
BA_ "GenMsgCycleTime" BO_ 2527679713 1000;
BA_ "GenMsgILSupport" BO_ 2527679713 "Yes";
BA_ "GenMsgSendType" BO_ 2527679713 "Cyclic";
BA_ "VFrameFormat" BO_ 2527679713 "ExtendedCAN_FD";
BA_ "GenMsgCycleTime" BO_ 2589283649 200;
BA_ "GenMsgILSupport" BO_ 2589283649 "Yes";
BA_ "GenMsgPDUConstants" BO_ 2589283649 "0x3e,0xb4,0x25,0xc1,0x31,0x1f,0xf1,0xd7,0xb1,0xbe,0xcc,0xe0,0x0f,0x46,0x51,0xb2";
BA_ "GenMsgSendType" BO_ 2589283649 "Cyclic";
BA_ "VFrameFormat" BO_ 2589283649 "ExtendedCAN_FD";
BA_ "GenMsgCycleTime" BO_ 608 50;
BA_ "GenMsgILSupport" BO_ 608 "Yes";
BA_ "GenMsgSendType" BO_ 608 "Cyclic";
BA_ "VFrameFormat" BO_ 608 "StandardCAN_FD";
BA_ "GenMsgCycleTime" BO_ 2589283751 500;
BA_ "GenMsgILSupport" BO_ 2589283751 "Yes";
BA_ "GenMsgSendType" BO_ 2589283751 "Cyclic";
BA_ "VFrameFormat" BO_ 2589283751 "ExtendedCAN_FD";
BA_ "GenMsgCycleTime" BO_ 2527679687 2000;
BA_ "GenMsgDelayTime" BO_ 2527679687 100;
BA_ "GenMsgILSupport" BO_ 2527679687 "Yes";
BA_ "GenMsgSendType" BO_ 2527679687 "Cyclic";
BA_ "VFrameFormat" BO_ 2527679687 "ExtendedCAN_FD";
BA_ "GenMsgCycleTime" BO_ 258 20;
BA_ "GenMsgILSupport" BO_ 258 "Yes";
BA_ "GenMsgPDUConstants" BO_ 258 "0xd7,0x12,0x85,0x7e,0x0b,0x34,0xfa,0x16,0x7a,0x25,0x2d,0x8f,0x04,0x8e,0x5d,0x35";
BA_ "GenMsgSendType" BO_ 258 "Cyclic";
BA_ "VFrameFormat" BO_ 258 "StandardCAN_FD";
BA_ "GenMsgCycleTime" BO_ 252 10;
BA_ "GenMsgILSupport" BO_ 252 "Yes";
BA_ "GenMsgPDUConstants" BO_ 252 "0x77,0x5c,0xa0,0x89,0x4b,0x7c,0xbb,0xd6,0x1f,0x6c,0x4f,0xf6,0x20,0x2b,0x43,0xdd";
BA_ "GenMsgSendType" BO_ 252 "Cyclic";
BA_ "VFrameFormat" BO_ 252 "StandardCAN_FD";
BA_ "GenMsgCycleTime" BO_ 2463978647 100;
BA_ "GenMsgILSupport" BO_ 2463978647 "Yes";
BA_ "GenMsgSendType" BO_ 2463978647 "Cyclic";
BA_ "VFrameFormat" BO_ 2463978647 "ExtendedCAN_FD";
BA_ "GenMsgCycleTime" BO_ 2527679683 2000;
BA_ "GenMsgDelayTime" BO_ 2527679683 100;
BA_ "GenMsgILSupport" BO_ 2527679683 "Yes";
BA_ "GenMsgSendType" BO_ 2527679683 "Cyclic";
BA_ "VFrameFormat" BO_ 2527679683 "ExtendedCAN_FD";
BA_ "GenMsgChkConstant" BO_ 278 172;
BA_ "GenMsgCycleTime" BO_ 278 20;
BA_ "GenMsgILSupport" BO_ 278 "Yes";
BA_ "GenMsgPDUConstants" BO_ 278 "0xac,0xac,0xac,0xac,0xac,0xac,0xac,0xac,0xac,0xac,0xac,0xac,0xac,0xac,0xac,0xac";
BA_ "GenMsgSendType" BO_ 278 "Cyclic";
BA_ "VFrameFormat" BO_ 278 "StandardCAN_FD";
VAL_ 333 ACC_limitierte_Anfahrdyn 0 "keine_Limitierung" 1 "Limitierung_Anfahrdynamik_angefordert";
VAL_ 333 ACC_nachtr_Stopp_Anf 0 "nicht_angefordert" 1 "angefordert";
VAL_ 333 ACC_DynErhoehung 0 "normale_Verzoegerungsdynamik" 1 "erhoehte_Verzoegerungsdynamik";
VAL_ 333 ACC_Freilaufstrategie_TSK 0 "Freilaufstr_nicht_angefordert" 1 "Freilaufstr_angefordert";
VAL_ 333 ACC_StartStopp_Info 0 "Motorlauf_langfristig_nicht_notwendig_Stoppfreigabe" 1 "Motoranlauf_nicht_zwingend_notwendig_Stoppverbot_keine_Startanforderung" 2 "Motoranlauf_zwingend_notwendig_Startanforderung" 3 "Systemfehler";
VAL_ 333 ACC_Sollbeschleunigung_02 2046 "Neutralwert" 2047 "Fehler";
VAL_ 333 ACC_Anfahren 0 "keine_Anforderung_Anfahren" 1 "Anforderung_Anfahren";
VAL_ 333 ACC_Anhalten 0 "kein_Anhalten_gewuenscht" 1 "Anhalten_gewuenscht";
VAL_ 333 ACC_Typ 0 "Basis_ACC" 1 "ACC_mit_FollowToStop" 2 "ACC_mit_StopAndGo" 3 "ACC_nicht_codiert";
VAL_ 333 ACC_Status_ACC 0 "ACC_OFF_Hauptschalter_aus" 1 "ACC_INIT" 2 "ACC_STANDBY" 3 "ACC_AKTIV_regelt" 4 "ACC_OVERRIDE" 5 "ACC_Abschaltreaktion" 6 "reversibler_Fehler_im_ACC_System" 7 "irreversibler_Fehler_im_ACC_System";
VAL_ 333 ACC_Minimale_Bremsung 0 "Anforderung_Minimale_Bremsung_nicht_aktiv" 1 "Anforderung_Minimale_Bremsung_aktiv";
VAL_ 333 ACC_Anhalteweg 2046 "Neutralwert" 2047 "Fehler";
VAL_ 333 ACC_Boost 0 "Boost_nicht_aktiv" 1 "Boost_aktiv";
VAL_ 333 ACC_Freilauf_Anf 0 "keine Freilauf-Anforderung" 1 "Freilauf-Anforderung";
VAL_ 333 ACC_Anforderung_HMS 0 "keine_Anforderung" 1 "halten" 2 "parken" 3 "halten_Standby" 4 "anfahren" 5 "Loesen_ueber_Rampe";
VAL_ 333 ACC_Folgebeschl 254 "Neutralwert";
VAL_ 333 ACC_Freilauf_Info 0 "Freilauf_freigegeben" 1 "kein_Uebergang_in_Freilauf_zulaessig" 2 "Freilauf_nicht_freigegeben" 3 "Freilauf_Anforderung";
VAL_ 333 ACC_Tempolimitassistent_Ein 0 "Tempolimitassistent_aus" 1 "Tempolimitassistent_ein";
VAL_ 333 ACC_FoD_Status 0 "Init" 1 "Funktion_inaktiv" 2 "Funktion_aktiv";
VAL_ 333 vESC_Verz_Anf 8 "Neutralwert" 9 "Init" 10 "Fehler";
VAL_ 333 RDR_v_ueber_Grund 4091 "Init" 4092 "temporaer_nicht_verfuegbar" 4093 "Fehler";
VAL_ 333 RDR_v_ueber_Grund_Genauigkeit 61 "groesser_6km_h" 62 "Init" 63 "Fehler";
VAL_ 333 RDR_v_ueber_Grund_Fahrtrichtung 0 "vorwaerts" 1 "rueckwaerts" 2 "init_unbekannt";
VAL_ 2527679682 ACC_ASM_Ereignis 0 "No_Event" 255 "ASM_Trigger";
VAL_ 2527679682 ACC_ASM_Zeitstempel 255 "Init";
VAL_ 64 AB_RGS_Anst 4 "aktiv_Niveau_1" 5 "aktiv_Niveau_2" 6 "aktiv_Niveau_3" 7 "aktiv_Niveau_4" 8 "deaktiviert";
VAL_ 64 AB_Front_Crash 0 "kein_Front_Crash" 1 "Front_Crash";
VAL_ 64 AB_Heck_Crash 0 "kein_Heck_Crash" 1 "Heck_Crash";
VAL_ 64 AB_SF_Crash 0 "kein_Seiten_Crash_Fahrer" 1 "Seiten_Crash_Fahrer";
VAL_ 64 AB_SB_Crash 0 "kein_Seiten_Crash_Beifahrer" 1 "Seiten_Crash_Beifahrer";
VAL_ 64 AB_Rollover_Crash 0 "kein_Rollover" 1 "Rollover";
VAL_ 64 AB_Crash_Int 0 "kein_Crash" 1 "Crash_Intensitaet_1" 2 "Crash_Intensitaet_2_(nur_Stellgliedtest_MLB_B8)" 3 "Crash_Intensitaet_2_(nur_D4_C7_Colorado_NF_PAG__Crash_im_MLB_B8)" 4 "Crash_Intensitaet_3_(alt_VW/AUDI__Stellgliedtest_MLB_B8)" 5 "Crash_Intensitaet_3_(alt_PAG)" 7 "Crash_Intensitaet_3";
VAL_ 64 AB_Lampe 0 "Aus" 1 "Ein";
VAL_ 64 AB_Deaktiviert 0 "aktiv" 1 "deaktiviert";
VAL_ 64 AB_VB_deaktiviert 0 "Beifahrerairbag_aktiv" 1 "Beifahrerairbag_deaktiviert";
VAL_ 64 AB_Systemfehler 0 "kein_Fehler" 1 "Airbag_Systemfehler";
VAL_ 64 AB_Diagnose 0 "nicht_in_Diagnose" 1 "in_Diagnose";
VAL_ 64 AB_Stellgliedtest 0 "nicht_im_Stellgliedtest" 1 "Airbag_im_Stellgliedtest";
VAL_ 64 AB_Erh_Auf_VB 0 "keine_Anzeige" 1 "Beifahrerairbag_deaktiviert" 2 "Beifahrerairbag_aktiviert" 3 "nicht_definiert";
VAL_ 64 AB_Gurtwarn_VF 0 "keine_Warnung" 1 "Gurtwarnung_ausloesen";
VAL_ 64 AB_Gurtwarn_VB 0 "keine_Warnung" 1 "Gurtwarnung_ausloesen";
VAL_ 64 AB_Anzeige_Fussg 0 "keine_FSG_Aktion_ausgeloest" 1 "Motorhaube_offen" 2 "Systemfehler";
VAL_ 64 AB_Texte_AKS 0 "keine_AKS_Ausloesung" 1 "AKS_ausgeloest" 2 "AKS_Systemfehler";
VAL_ 64 AB_PAO_Leuchte_Anf 0 "Leuchte_ausschalten" 1 "Leuchte_einschalten";
VAL_ 64 AB_MKB_gueltig 0 "Multikollisionsbremsung_nicht_freigeschaltet" 1 "Multikollisionsbremsung_freigeschaltet";
VAL_ 64 AB_MKB_Anforderung 0 "Multikollisionsbremsung_nicht_angefordert" 1 "Multikollisionsbremsung_angefordert";
VAL_ 64 AB_Versorgungsspannung 0 "plausibel" 1 "unplausibel";
VAL_ 64 AB_Deaktivierung_HV 0 "keine_Deaktivierung" 1 "Deaktivierung_1" 2 "Deaktivierung_2" 3 "Deaktivierung_3" 4 "Deaktivierung_4" 5 "Deaktivierung_5" 6 "Deaktivierung_6" 7 "Fehler";
VAL_ 64 AB_EDR_Trigger 0 "No_Event" 1 "Start_Event" 2 "NonDeployment_Event" 3 "Deployment_Event";
VAL_ 64 AB_Belegung_VF 0 "nicht_verfuegbar" 1 "Fehler" 2 "nicht_belegt" 3 "belegt";
VAL_ 64 AB_Gurtschloss_FA_ext 0 "nicht_verbaut" 1 "reserviert" 2 "nicht_gesteckt" 3 "gesteckt" 4 "dauerhaft_nicht_gesteckt" 5 "dauerhaft_gesteckt" 6 "Init" 7 "Fehler";
VAL_ 64 AB_Belegung_VF_ext 0 "nicht_verbaut" 1 "reserviert" 2 "nicht_belegt" 3 "belegt" 4 "dauerhaft_nicht_belegt" 5 "dauerhaft_belegt" 6 "Init" 7 "Fehler";
VAL_ 64 ASM_Masterzeit 255 "Init";
VAL_ 1312 LoGeWa_Event_Kombiwarnung 0 "Init" 1 "Unfall" 2 "Traktionsverlust" 3 "Panne" 4 "Sichtbehinderung" 5 "Aquaplaning";
VAL_ 1312 AB_Anforderung_eCall 0 "keine_Anforderung" 1 "Anforderung";
VAL_ 1312 AB_Anprall_Seite_Beifahrer 0 "kein_Anprall" 1 "Anprall_erkannt";
VAL_ 1312 AB_Anprall_Rollover 0 "kein_Anprall" 1 "Anprall_erkannt";
VAL_ 1312 AB_Anprall_FGS 0 "kein_Anprall" 1 "Anprall_erkannt";
VAL_ 1312 AB_Anprall_Front_Beifahrer 0 "kein_Anprall" 1 "Anprall_erkannt";
VAL_ 1312 AB_Anprall_Front_Fahrer 0 "kein_Anprall" 1 "Anprall_erkannt";
VAL_ 1312 AB_Anprall_Heck_Beifahrer 0 "kein_Anprall" 1 "Anprall_erkannt";
VAL_ 1312 AB_Anprall_Heck_Fahrer 0 "kein_Anprall" 1 "Anprall_erkannt";
VAL_ 1312 AB_Wickelklappung_Reihe2_MI 0 "nicht_verbaut" 1 "nicht_verfuegbar__Fehler_oder_Init" 2 "nicht_verriegelt" 3 "verriegelt";
VAL_ 1312 AB_Belegung_VB 0 "nicht_verfuegbar" 1 "Fehler" 2 "nicht_belegt" 3 "belegt";
VAL_ 1312 AB_Abschaltanf_SIH_BF 0 "Normalbetrieb" 1 "Abschaltung_angefordert";
VAL_ 1312 AB_Anprall_Seite_Fahrer 0 "kein_Anprall" 1 "Anprall_erkannt";
VAL_ 1312 SC_PAO_Schriftzug_Anf 0 "LED aus" 1 "LED an" 2 "LED blinken" 3 "reserviert";
VAL_ 1312 SC_PAO_ON_Anf 0 "LED aus" 1 "LED an" 2 "LED blinken" 3 "reserviert";
VAL_ 1312 SC_PAO_OFF_Anf 0 "LED aus" 1 "LED an" 2 "LED blinken" 3 "reserviert";
VAL_ 1312 AB_Crashschwere 0 "kein_Ereignis" 1 "Crashschwere_1" 2 "Crashschwere_2" 3 "Crashschwere_3" 4 "Crashschwere_4" 5 "Crashschwere_5" 6 "Crashschwere_2_bis_5" 7 "Fehler";
VAL_ 1312 AB_Anforderung_USM 0 "keine_Anforderung" 1 "Anforderung";
VAL_ 1312 AB_Gurtschloss_FA 0 "nicht_verbaut" 1 "nicht_verfügbar (Fehler oder Init)" 2 "nicht_gesteckt" 3 "gesteckt";
VAL_ 1312 AB_Gurtschloss_BF 0 "nicht_verbaut" 1 "nicht_verfügbar (Fehler oder Init)" 2 "nicht_gesteckt" 3 "gesteckt";
VAL_ 1312 AB_Gurtschloss_Reihe2_FA 0 "nicht_verbaut" 1 "nicht_verfügbar (Fehler oder Init)" 2 "nicht_gesteckt" 3 "gesteckt";
VAL_ 1312 AB_Gurtschloss_Reihe2_MI 0 "nicht_verbaut" 1 "nicht_verfügbar (Fehler oder Init)" 2 "nicht_gesteckt" 3 "gesteckt";
VAL_ 1312 AB_Gurtschloss_Reihe2_BF 0 "nicht_verbaut" 1 "nicht_verfügbar (Fehler oder Init)" 2 "nicht_gesteckt" 3 "gesteckt";
VAL_ 1312 AB_Gurtschloss_Reihe3_FA 0 "nicht_verbaut" 1 "nicht_verfügbar (Fehler oder Init)" 2 "nicht_gesteckt" 3 "gesteckt";
VAL_ 1312 AB_Gurtschloss_Reihe3_MI 0 "nicht_verbaut" 1 "nicht_verfügbar (Fehler oder Init)" 2 "nicht_gesteckt" 3 "gesteckt";
VAL_ 1312 AB_Gurtschloss_Reihe3_BF 0 "nicht_verbaut" 1 "nicht_verfügbar (Fehler oder Init)" 2 "nicht_gesteckt" 3 "gesteckt";
VAL_ 1312 AB_Sitzpos_Sens_FA 0 "nicht verfügbar" 1 "Fehler" 2 "Sitz nicht vorne" 3 "Sitz vorne";
VAL_ 1312 AB_Sitzpos_Sens_BF 0 "nicht verfügbar" 1 "Fehler" 2 "Sitz nicht vorne" 3 "Sitz vorne";
VAL_ 1312 AB_Wickelklappung_Reihe2_BF 0 "nicht_verbaut" 1 "nicht_verfuegbar__Fehler_oder_Init" 2 "nicht_verriegelt" 3 "verriegelt";
VAL_ 1312 AB_Wickelklappung_Reihe2_FA 0 "nicht_verbaut" 1 "nicht_verfuegbar__Fehler_oder_Init" 2 "nicht_verriegelt" 3 "verriegelt";
VAL_ 65 AB_MKB_Safing 0 "Multikollisionsbremsung_nicht_bestaetigt" 1 "Multikollisionsbremsung_bestaetigt";
VAL_ 1349 AB_Gurtwarn_Reihe4_FA 0 "nicht_verbaut" 1 "keine_Gurtwarnung_Sitz_leer" 2 "keine_Gurtwarnung_Sitz_belegt" 3 "Gurtwarnung_Sitz_belegt";
VAL_ 1349 AB_Gurtwarn_Reihe4_BF 0 "nicht_verbaut" 1 "keine_Gurtwarnung_Sitz_leer" 2 "keine_Gurtwarnung_Sitz_belegt" 3 "Gurtwarnung_Sitz_belegt";
VAL_ 1349 AB_Gurtwarn_Reihe4_MI 0 "nicht_verbaut" 1 "keine_Gurtwarnung_Sitz_leer" 2 "keine_Gurtwarnung_Sitz_belegt" 3 "Gurtwarnung_Sitz_belegt";
VAL_ 1349 AB_Gurtwarn_Reihe2_FA 0 "nicht_verbaut" 1 "keine_Gurtwarnung_Sitz_leer" 2 "keine_Gurtwarnung_Sitz_belegt" 3 "Gurtwarnung_Sitz_belegt";
VAL_ 1349 AB_Gurtwarn_Reihe2_BF 0 "nicht_verbaut" 1 "keine_Gurtwarnung_Sitz_leer" 2 "keine_Gurtwarnung_Sitz_belegt" 3 "Gurtwarnung_Sitz_belegt";
VAL_ 1349 AbstWarn_MV_FAS_Fkt_Status 0 "Init" 1 "Funktion_Ist_Ein" 2 "Funktion_Ist_Aus" 3 "Fehler";
VAL_ 1349 WarnBrems_Charisma_Status 0 "Init" 1 "verfügbar" 2 "nicht verfügbar" 3 "asynchron durch Fahrerwunsch";
VAL_ 1349 WarnBrems_Charisma_FahrPr 0 "keine_Funktion" 1 "Programm_1" 2 "Programm_2" 3 "Programm_3" 4 "Programm_4" 5 "Programm_5" 6 "Programm_6" 7 "Programm_7" 8 "Programm_8" 9 "Programm_9" 10 "Programm_10" 11 "Programm_11" 12 "Programm_12" 13 "Programm_13" 14 "Programm_14" 15 "Programm_15";
VAL_ 1349 AB_Gurtwarn_Reihe2_MI 0 "nicht_verbaut" 1 "keine_Gurtwarnung_Sitz_leer" 2 "keine_Gurtwarnung_Sitz_belegt" 3 "Gurtwarnung_Sitz_belegt";
VAL_ 1349 AB_Gurtwarn_Reihe3_FA 0 "nicht_verbaut" 1 "keine_Gurtwarnung_Sitz_leer" 2 "keine_Gurtwarnung_Sitz_belegt" 3 "Gurtwarnung_Sitz_belegt";
VAL_ 1349 AB_Gurtwarn_Reihe3_MI 0 "nicht_verbaut" 1 "keine_Gurtwarnung_Sitz_leer" 2 "keine_Gurtwarnung_Sitz_belegt" 3 "Gurtwarnung_Sitz_belegt";
VAL_ 1349 AB_Gurtwarn_Reihe3_BF 0 "nicht_verbaut" 1 "keine_Gurtwarnung_Sitz_leer" 2 "keine_Gurtwarnung_Sitz_belegt" 3 "Gurtwarnung_Sitz_belegt";
VAL_ 1349 LGI_FAS_Fkt_Status 0 "Init" 1 "Funktion_Ist_Ein" 2 "Funktion_Ist_Aus" 3 "Fehler";
VAL_ 1349 PreCrash_FAS_Fkt_Status 0 "Init" 1 "Funktion_Ist_Ein" 2 "Funktion_Ist_Aus" 3 "Fehler";
VAL_ 1349 AB_SBR_hinten_verbau 0 "ohne_SBR_hinten" 1 "mit_SBR_hinten" 2 "nicht_definiert" 3 "Init";
VAL_ 1349 AWV_Einstellung_System_ASG 0 "deaktiviert" 1 "aktiviert";
VAL_ 1349 AWV_Einstellung_Warnung_ASG 0 "Aus" 1 "Setting_2" 2 "Setting_3" 3 "Setting_4" 4 "Setting_5" 5 "Ein";
VAL_ 1349 SC_PreSense_Modus_Warnung_NV 0 "Aus" 1 "Setting_2" 2 "Setting_3" 3 "Setting_4" 4 "Setting_5" 5 "Ein";
VAL_ 1349 SC_PreSense_Modus_Warnung_MV 0 "Aus" 1 "Setting_2" 2 "Setting_3" 3 "Setting_4" 4 "Setting_5" 5 "Ein";
VAL_ 1349 SC_PreSense_Modus_System_MV 0 "deaktiviert" 1 "aktiviert";
VAL_ 1349 SC_PreSense_Modus_System_NV 0 "deaktiviert" 1 "aktiviert";
VAL_ 1349 SC_PreSense_Modus_System_KAS 0 "deaktiviert" 1 "aktiviert";
VAL_ 2527679722 AB_Gurtschloss_Reihe4_FA 0 "nicht_verbaut" 1 "nicht_verfügbar (Fehler oder Init)" 2 "nicht_gesteckt" 3 "gesteckt";
VAL_ 2527679722 AB_Gurtschloss_Reihe4_BF 0 "nicht_verbaut" 1 "nicht_verfügbar (Fehler oder Init)" 2 "nicht_gesteckt" 3 "gesteckt";
VAL_ 2527679722 AB_Gurtschloss_Reihe4_MI 0 "nicht_verbaut" 1 "nicht_verfügbar (Fehler oder Init)" 2 "nicht_gesteckt" 3 "gesteckt";
VAL_ 1633 AAG_AVS_Fehler_02_inv 0 "Fehler" 1 "kein_Fehler";
VAL_ 1633 AAG_Bremsl_durch_ECD 0 "Bremslicht_ist_aus" 1 "Bremslicht_durch_ECD_aktiv";
VAL_ 1633 AAG_Anhaenger_abgesteckt 1 "Anhaenger_wurde_bei_KL15_aus_abgesteckt";
VAL_ 1633 AAG_NSL_aktiv 1 "Anhaenger_Nebelschusslicht_aktiv";
VAL_ 1633 AAG_Anhaenger_erkannt 0 "kein_Anhaenger_erkannt" 1 "AAG_Anhaenger_erkannt";
VAL_ 1633 AAG_Blinker_H_aktiv 1 "Anhaenger_Blinker_aktiv";
VAL_ 1633 AAG_Blinker_HL_def 1 "Anhaenger_Blinker_links_defekt";
VAL_ 1633 AAG_Blinker_HR_def 1 "Anhaenger_Blinker_rechts_defekt";
VAL_ 1633 AAG_Bremslicht_H_def 1 "Anhaenger_Bremslicht_defekt";
VAL_ 1633 AAG_Schlusslicht_HL_def 1 "Anhaenger_Schlusslicht_links_defekt";
VAL_ 1633 AAG_Schlusslicht_HR_def 1 "Anhaenger_Schlusslicht_rechts_defekt";
VAL_ 1633 AAG_Bremslicht_Reku 0 "inaktiv" 1 "aktiv";
VAL_ 1633 AAG_AVS_Fehler_02 0 "kein_Fehler" 1 "Fehler";
VAL_ 1633 AAG_LED_aktiv 0 "Lampen" 1 "LED";
VAL_ 1633 AAG_AVS_Stati 0 "endlage eingefahren erreicht" 1 "endlage ausgefahren erreicht" 2 "ausfahren automatik " 3 "einfahren automatik" 4 "ausfahren manuell " 5 "einfahren manuell" 6 "zwischenposition" 7 "nicht initialisiert";
VAL_ 345 ARA_Anf_Meldungen 128 "steeringAsAct_brakeByYourself" 0 "keine_Meldung" 129 "trailer_assist_is_finished" 1 "trailer_assist_temp_notAvailable" 130 "SteerIntervenDriverEmergBrakeAct" 2 "pressBrake_toReleaseParkingBrak" 131 "stabilityCtrl_emergencyBrake_act" 3 "trailDetNotFinishedMoveStraight" 132 "maxAngleExeeded_EmergBrakeAct" 4 "trailDetecNotFinishedReducedFctn" 133 "sysErrorEmergBrakeContactService" 5 "parkAsNotFuncRackOnTrailTowHitch" 134 "system_error_contact_service" 6 "aborted_trailNotDetec_emergBrake" 135 "aborted_trailNotDetec_emergBrake" 7 "aborted_trailer_is_not_detected" 136 "aborted_trailerNotDetecRsmeSteer" 8 "standstill_to_act_trailerAssist" 137 "system_error_braking_byYourself" 9 "duringAutomSteering_actNotAvail" 138 "trajectFwdSteerAsActBrakeYourslf" 10 "standstill_time_not_long_enough" 139 "SteeringAs_notAct_resumeSteering" 11 "press_PLA_BTN_toActTrailerAssist" 140 "trailerAs_aborted_resumeSteering" 12 "Temporary_not_available_ESP_off" 13 "traject_forward_path_suggestion" 14 "traject_backing_up_is_possible" 15 "traject_towing_fwd_canB_finished" 16 "trailerAsNotAvail_acivateMirrors" 17 "mirrors_are_closing" 18 "trailerAsNotAvailable_close_door" 19 "trailerAs_aborted_driverDoorOpen" 20 "trailerAsNotAvailable_closeTrunk" 21 "aborted_trunk_door_is_open" 22 "trailerAsNotAvail_cleanRearCam" 23 "aborted_clean_rear_camera" 24 "trailerAs_check_trailerConnector" 25 "trajectory_finished";
VAL_ 345 ARA_Knickwinkel_konfidenz 126 "Init" 127 "Fehler";
VAL_ 345 ARA_Texte 0 "kein Text/Akustik" 63 "Fehler";
VAL_ 345 ARA_Modus 0 "Knickwinkelmodus" 1 "Trajektorienmodus";
VAL_ 345 ARA_Aktiver_Grafikmodus 0 "keine_Grafik" 1 "Grafikmodus_aktiv";
VAL_ 345 ARA_Deaktivierung_sperren 0 "nicht_gesperrt" 1 "gesperrt";
VAL_ 345 ARA_Modus_Anf 0 "ARA Modus nicht im TSG angefordert" 1 "ARA Modus im TSG angefordert";
VAL_ 345 ARA_Bremsfuss 0 "kein Bremsfuss" 1 "Bremsfuss angefordert";
VAL_ 345 ARA_Sensor_Aktivierung 0 "Knickwinkelsensor deaktivieren" 1 "Knickwinkelsensor aktivieren";
VAL_ 345 ARA_Knickwinkel_Komfort 62 "Init" 63 "Fehler";
VAL_ 345 ARA_Status 8 "ARA_Status_betriebsbereit" 0 "ARA_Status_inaktiv" 9 "ARA_Status_Klemmtraeger_erkannt" 1 "ARA_Status_init" 2 "Fehler" 3 "ARA_Status_Start" 4 "ARA_Status_aktiv" 6 "ARA_Status_Regelung_aktiv" 10 "ARA_Status_Abbruch" 11 "ARA_Status_nicht_betriebsbereit";
VAL_ 345 ARA_Knickwinkel_Max 126 "Init" 127 "Fehler";
VAL_ 345 ARA_Knickwinkel_Soll 254 "Init" 255 "Fehler";
VAL_ 345 ARA_Knickwinkel_Ist 254 "Init" 255 "Fehler";
VAL_ 2589283607 AWC_Status_EoHVL 0 "Init" 1 "Keine_offene_HV_Leitung_erkannt" 2 "offene_HV_Leitung_erkannt" 3 "Fehler";
VAL_ 2589283607 AWC_Status_Spgfreiheit 0 "Init" 1 "HV_Komponente_spannungsfrei" 2 "HV_Komp_nicht_spannungsfrei" 3 "Fehler_nicht_spannungsfrei";
VAL_ 2589283607 AWC_IstSpannung 1022 "Init" 1023 "Fehler";
VAL_ 2589283607 AWC_Fehlerstatus 0 "Komponente_IO" 1 "Eingeschr_KompFkt_AWC_Lad_NIO" 2 "Eingeschr_KompFkt_reserve" 3 "Eingeschr_KompFkt_Interlock" 4 "Eingeschr_KompFkt_reserve" 5 "Eingeschr_KompFkt_reserve" 6 "Keine_Komponentenfunktion" 7 "Init";
VAL_ 2589283607 AWC_IstModus 0 "Standby_AWCLaden_inaktiv" 1 "AWCLaden_aktiv" 2 "AWCLaden_Verzoegerung" 3 "AWCLaden_Deaktiviert" 6 "Init" 7 "Ladefehler";
VAL_ 2589283607 AWC_IstStrom 510 "Init" 511 "Fehler";
VAL_ 2589283607 AWC_MaxLadLeistung 510 "Init" 511 "Fehler";
VAL_ 219 PCF_Freigabe 0 "keine_Freigabe_PreCrashFront" 1 "Freigabe_PreCrashFront";
VAL_ 219 SDF_PSF_Objektstatus 0 "kein_relevantes_Obj" 1 "relevantes_Obj_vorausfahrend" 2 "relevantes_Obj_stehend" 3 "relevantes_Obj_angehalten" 4 "relevantes_Obj_entgegenkommend" 5 "relevantes_Obj_querend" 7 "Fehler";
VAL_ 219 SDF_PSF_CU_Status 0 "Kollision_vermeidbar" 1 "Kollision_unvermeidbar";
VAL_ 219 SDF_PSF_CW 126 "Init" 127 "Fehler";
VAL_ 219 SDF_PSF_Fahrer_aktiv 0 "Fahrer_nicht_aktiv" 1 "Fahrer_aktiv";
VAL_ 219 SDF_PSF_Guete 0 "Modellguete_niO_keine_Plausi" 1 "Modellguete_niO_plausibilisiert" 2 "Modellguete_iO_keine_Plausi" 3 "Modellguete_iO_plausibilisiert";
VAL_ 219 SDF_PSF_Kollisionsueberdeckung 0 "Keine_Ueberdeckung" 29 "Ueberdeckung_groesser_Maximalwert" 30 "Init" 31 "Fehler";
VAL_ 219 SDF_PSF_Time_To_Collision 254 "Init" 255 "Fehler";
VAL_ 219 SDF_PSF_v_rel 0 "Objektstatus_0" 254 "Init" 255 "Fehler";
VAL_ 219 AWV_Eingriff_Sendeart 0 "langsamer_Zyklus" 1 "schneller_Zyklus";
VAL_ 219 AWV_Verz_Freigabe 0 "Verzoegerung_nicht_freigeben" 1 "Verzoegerung_freigeben";
VAL_ 219 AWV_Verz_Anf 1023 "keine_Anforderung";
VAL_ 219 AWV_Anf_Prefill 0 "Keine_Anforderung" 1 "Prefill_aktivieren";
VAL_ 219 AWV_Ruckprofil 0 "kein_Ruck" 1 "schwacher_Ruck" 2 "mittlerer_Ruck" 3 "starker_Ruck";
VAL_ 219 AWV_Time_to_collision 253 "Wert_groesser_max" 254 "Unbekannt" 255 "Init";
VAL_ 219 AWV_HBA_Param 0 "Defaultparametersatz" 1 "leicht_erhoeht" 2 "erhoeht" 3 "hoechst";
VAL_ 219 AWV_Verz_Anf_ASIL 0 "QM" 1 "A" 2 "B" 3 "C";
VAL_ 219 AWV_Time_to_brake 125 "Wert_groesser_max" 126 "unbekannt" 127 "Init";
VAL_ 219 AWV_Zielobjekttyp 0 "Unbekannt" 1 "Fussgaenger" 2 "Zweirad" 3 "PKW" 4 "LKW" 5 "reserviert" 6 "reserviert" 7 "reserviert" 8 "reserviert" 9 "reserviert" 10 "reserviert" 11 "reserviert" 12 "reserviert" 13 "reserviert" 14 "reserviert" 15 "init";
VAL_ 219 AWV_QFK_KruemmSoll_VZ 0 "positiv" 1 "negativ";
VAL_ 219 AWV_QFK_AnfStat 1 "Init" 2 "Bereit" 4 "Eingriff";
VAL_ 869 BEM_UBDM 0 "Init" 255 "Fehler";
VAL_ 869 NVEM_Ladefreigabe 0 "kein_Freigabe" 1 "Freigabe_Stufe_1" 2 "Freigabe_Stufe_2" 3 "Uneingeschraenkte_Freigabe";
VAL_ 869 NVEM_FMAus_Info 0 "Motorlauf_langfristig_nicht_notwendig_FMAus_Freigabe" 1 "Motoranlauf_nicht_zwingend_notwendig_Stoppverbot_keine_Startanforderung" 2 "Motoranlauf_zwingend_notwendig_Startanforderung" 3 "Systemfehler";
VAL_ 869 NVEM_PTC_Sollstufe 0 "Aus" 1 "Stufe_1" 2 "Stufe_2" 3 "Stufe_3";
VAL_ 869 NVEM_P_Generator_Status 0 "gefiltert" 1 "ungefiltert";
VAL_ 869 BEM_P_Generator 255 "Fehler";
VAL_ 869 BEM_n_LLA 0 "keine_Erhoehung" 1 "Stufe_1" 2 "Stufe_2" 3 "Stufe_3";
VAL_ 869 BEM_01_Abschaltstufen 0 "Stufe_0_keine_Einschraenkung" 1 "Stufe_1" 2 "Stufe_2" 3 "Stufe_3" 4 "Transportmodus" 7 "Ruhestrommessmodus";
VAL_ 869 BEM_Anf_KL 0 "keine Anforderung" 1 "Anforderung Kühlerlüfter Ansteuerung";
VAL_ 869 BEM_StartStopp_Info 0 "Motorlauf_nicht_notwendig_(Stoppfreigabe)" 1 "Motoranlauf_nicht_zwingend_notwendig_(Stoppverbot,keine_Startanforderung)" 2 "Motoranlauf_zwingend_notwendig_(Startanforderung)" 3 "Systemfehler";
VAL_ 869 BEM_EMLIN_ungueltig 0 "Signale_gueltig" 1 "Signale_ungueltig";
VAL_ 869 BEM_Batt_Ab 0 "verbunden" 1 "nicht_verbunden";
VAL_ 869 NVEM_FMAus_I_Verbrauch 30 "Init" 31 "Fehler";
VAL_ 869 NVEM_Freilauf_Info 0 "Freilauf_freigegeben" 1 "Weiches_Veto_uebertippbar" 2 "Hartes_Veto_Abbruch" 3 "Freilauf_Anforderung";
VAL_ 869 BEM_NV_NachladAnf 0 "keine_Anforderung" 1 "Anforderung_NV_Nachladung" 2 "Wunsch_NV_Nachladung" 3 "Fehler";
VAL_ 869 BEM_Segel_Info 0 "keine_Anforderung" 1 "Mindestdrehzahl_1" 2 "Mindestdrehzahl_2" 3 "Segelveto";
VAL_ 869 BEM_HYB_DC_uMinLV 254 "Init" 255 "Fehler";
VAL_ 1442 BMS_Fehler_Pilot 0 "geschlossen" 1 "Unterbrechung";
VAL_ 1442 BMS_Status_ServiceDisconnect 0 "gesteckt" 1 "gezogen";
VAL_ 1442 BMS_Status_Spgfreiheit 0 "Init" 1 "HV_Komponente_spannungsfrei" 2 "HV_Komp_nicht_spannungsfrei" 3 "Fehler_nicht_spannungsfrei";
VAL_ 1442 BMS_OBD_Lampe_Anf 0 "kein_MIL_Request" 1 "MIL_Request";
VAL_ 1442 BMS_Fehlerstatus 0 "Komponente_IO" 1 "Eingeschr_KompFkt_Isofehler_I" 2 "Eingeschr_KompFkt_Isofehler_II" 3 "Eingeschr_KompFkt_Interlock" 4 "Eingeschr_KompFkt_SD" 5 "Eingeschr_KompFkt_Leistungsred" 6 "Keine_Komponentenfunktion" 7 "Init";
VAL_ 1442 BMS_Kapazitaet_02 2047 "Init";
VAL_ 1442 BMS_Fehlerlampe_Anf 1 "RedLED_Request";
VAL_ 1442 BMS_Warnlampe_Anf 1 "YellowLED_Request";
VAL_ 1442 BMS_Kl30c_Status 0 "Init" 1 "geschlossen" 2 "offen" 3 "Fehler";
VAL_ 2527679654 BMS_IsoZustand 0 "Init" 1 "groesser_Schwelle_1" 2 "kleiner_Schwelle_1_gesamt" 3 "kleiner_Schwelle_1_intern" 4 "kleiner_Schwelle_2_gesamt" 5 "kleiner_Schwelle_2_intern" 6 "kein_Messwert" 7 "Messung_aktiv";
VAL_ 2527679654 BMS_IsoFehler 0 "Init" 1 "kein_IsoFehler" 2 "IsoFehler_Schwelle_1" 3 "IsoFehler_Schwelle_2" 4 "IWU_defekt" 5 "reserviert" 6 "reserviert" 7 "reserviert";
VAL_ 2527679654 BMS_IstTemperatur_hoechste 253 "reserviert" 254 "Init" 255 "Fehler";
VAL_ 2527679654 BMS_IstTemperatur_niedrigste 253 "reserviert" 254 "Init" 255 "Fehler";
VAL_ 2527679654 BMS_IstZellspannung_hoechste 4092 "reserviert" 4093 "reserviert" 4094 "Init" 4095 "Fehler";
VAL_ 2527679654 BMS_IstZellspannung_niedrigste 4092 "reserviert" 4093 "reserviert" 4094 "Init" 4095 "Fehler";
VAL_ 207 BMS_Fehlerstatus_HV_Schuetze 0 "Init_kein_Diagnoseergebnis" 1 "kein_Schuetz_verschweisst" 2 "mind_1_Schuetz_verschweisst" 3 "Fehler_Schuetzstatuserkennung";
VAL_ 207 BMS_ErwGrenzen_aktiv 0 "Init" 1 "extended_Range";
VAL_ 207 BMS_IstModus 0 "HV_inaktiv" 1 "Fahren_HV_aktiv" 2 "stBalancing" 3 "externes_Laden" 4 "AC_Laden" 5 "Error_Batt" 6 "DC_Laden" 7 "Init";
VAL_ 207 BMS_HVIL_Status 0 "Init" 1 "geschlossen" 2 "offen" 3 "Fehler";
VAL_ 207 BMS_Fehler_HVBattAbschaltung 1 "Err_ShutOff";
VAL_ 207 BMS_Fehler_HVBattAbschaltung_Anf 1 "Err_ShutOffRequest";
VAL_ 207 BMS_Fehler_Leistungsred 0 "keine_Leistungseinschraenkung" 1 "Leistungseinschraenkung";
VAL_ 207 BMS_Strom 32765 "nicht_messbar" 32766 "Init" 32767 "Fehler";
VAL_ 207 BMS_Fehler_Notabschaltung_Crash 1 "Err_EmergcyShtOffCrash";
VAL_ 207 BMS_Spannung_Zwischenkreis 4093 "nicht_messbar" 4094 "Init" 4095 "Fehler";
VAL_ 207 BMS_Spannung 4093 "nicht_messbar" 4094 "Init" 4095 "Fehler";
VAL_ 2463978704 BMS_Max_Entladestrom 8190 "Init";
VAL_ 2463978704 BMS_Max_Ladestrom 8190 "Init";
VAL_ 2463978704 BMS_Max_Entladeleistung 8190 "Init";
VAL_ 2463978704 BMS_Max_Ladeleistung 8190 "Init";
VAL_ 2463978705 BMS_Status_EoHVL_Heizer 0 "Init" 1 "Keine_offene_HV_Leitung_erkannt" 2 "offene_HV_Leitung_erkannt" 3 "Fehler";
VAL_ 2463978705 BMS_Ladezustand 2046 "Init" 2047 "Fehler";
VAL_ 2463978705 BMS_PerfInd_Entladen 1022 "Init";
VAL_ 2463978705 BMS_PerfInd_Laden 1022 "Init";
VAL_ 2463978705 BMS_Nutzbare_EntladeEnergie 65534 "Init" 65535 "Fehler";
VAL_ 2589283664 BMS_Balancing_Aktiv 0 "Init" 1 "aktiv" 2 "nicht_aktiv";
VAL_ 2589283664 BMS_Ladevorgang_aktiv 0 "inaktiv" 1 "aktiv";
VAL_ 2589283664 BMS_RIso_Ext 4094 "Init" 4095 "Fehler";
VAL_ 2589283664 BMS_Min_Ladezustand 2046 "Init";
VAL_ 2589283664 BMS_Max_Energie 8190 "Init";
VAL_ 2589283664 BMS_Max_Ladezustand 2046 "Init";
VAL_ 2589283665 BMS_BattHeizung_VerbautStatus 0 "nicht_verbaut" 1 "verbaut";
VAL_ 2589283665 BMS_Fehler_NTKreis 0 "kein_Fehler" 1 "Fehler";
VAL_ 2589283665 BMS_Temperierung_Anf 0 "hoher_Kuehlbedarf" 1 "mittlerer_Kuehlbedarf" 2 "niedriger_Kuehlbedarf" 3 "kein_Temperierungsbedarf_Init" 4 "niedriger_Heizbedarf" 5 "mittlerer_Heizbedarf" 6 "hoher_Heizbedarf" 7 "Umwaelzungsbedarf";
VAL_ 2589283665 BMS_Status_Ventil1 0 "Ventil_nicht_angesteuert" 1 "Ventil_angesteuert" 2 "reserviert" 3 "reserviert" 4 "reserviert" 5 "Ventil_nicht_verbaut" 6 "Init" 7 "Fehler";
VAL_ 2589283665 BMS_Status_Ventil2 0 "Ventil_nicht_angesteuert" 1 "Ventil_angesteuert" 2 "reserviert" 3 "reserviert" 4 "reserviert" 5 "Ventil_nicht_verbaut" 6 "Init" 7 "Fehler";
VAL_ 2589283665 BMS_Pumpe1_Ansteuerung 13 "nicht_verbaut" 14 "Init" 15 "Fehler";
VAL_ 2589283665 BMS_Pumpe2_Ansteuerung 13 "nicht_verbaut" 14 "Init" 15 "Fehler";
VAL_ 2589283665 BMS_VorlaufTemperatur 253 "nicht_verbaut" 254 "Init" 255 "Fehler";
VAL_ 2589283665 BMS_Temperatur 254 "Init" 255 "Fehler";
VAL_ 2589283665 BMS_SollVorlauftemperatur 254 "Init" 255 "Fehler";
VAL_ 2589283665 BMS_RuecklaufTemperatur 253 "nicht_verbaut" 254 "Init" 255 "Fehler";
VAL_ 2589283760 BMS_Max_Spannung 1022 "Init";
VAL_ 2589283760 BMS_Min_Spannung 1022 "Init";
VAL_ 2589283760 BMS_Dauer_Entladeleistung 4094 "Init";
VAL_ 2589283760 BMS_Dauer_Ladeleistung 4094 "Init";
VAL_ 2463978646 CHA_Ziel_FahrPr_AGA 0 "keine_Funktion" 1 "Programm_1" 2 "Programm_2" 3 "Programm_3" 4 "Programm_4" 5 "Programm_5" 6 "Programm_6" 7 "Programm_7" 8 "Programm_8" 9 "Programm_9" 10 "Programm_10" 11 "Programm_11" 12 "Programm_12" 13 "Programm_13" 14 "Programm_14" 15 "Programm_15";
VAL_ 2463978646 CHA_Ziel_FahrPr_ESP 0 "keine_Funktion" 1 "Programm_1" 2 "Programm_2" 3 "Programm_3" 4 "Programm_4" 5 "Programm_5" 6 "Programm_6" 7 "Programm_7" 8 "Programm_8" 9 "Programm_9" 10 "Programm_10" 11 "Programm_11" 12 "Programm_12" 13 "Programm_13" 14 "Programm_14" 15 "Programm_15";
VAL_ 2463978646 CHA_Ziel_FahrPr_Freilauf 0 "keine_Funktion" 1 "Programm_1" 2 "Programm_2" 3 "Programm_3" 4 "Programm_4" 5 "Programm_5" 6 "Programm_6" 7 "Programm_7" 8 "Programm_8" 9 "Programm_9" 10 "Programm_10" 11 "Programm_11" 12 "Programm_12" 13 "Programm_13" 14 "Programm_14" 15 "Programm_15";
VAL_ 2463978646 CHA_Fahrer_Umschaltung 0 "keine_oder_automatische_Umschaltung" 1 "manuelle_Umschaltung";
VAL_ 2463978646 CHA_Fahrer_Umschaltung_BMA 0 "keine_oder_autom_Umschaltung" 1 "manuelle_Umschaltung";
VAL_ 2463978646 CHA_Ziel_FahrPr_MO 0 "keine_Funktion" 1 "Programm_1" 2 "Programm_2" 3 "Programm_3" 4 "Programm_4" 5 "Programm_5" 6 "Programm_6" 7 "Programm_7" 8 "Programm_8" 9 "Programm_9" 10 "Programm_10" 11 "Programm_11" 12 "Programm_12" 13 "Programm_13" 14 "Programm_14" 15 "Programm_15";
VAL_ 2463978646 CHA_Ziel_FahrPr_GE 0 "keine_Funktion" 1 "Programm_1" 2 "Programm_2" 3 "Programm_3" 4 "Programm_4" 5 "Programm_5" 6 "Programm_6" 7 "Programm_7" 8 "Programm_8" 9 "Programm_9" 10 "Programm_10" 11 "Programm_11" 12 "Programm_12" 13 "Programm_13" 14 "Programm_14" 15 "Programm_15";
VAL_ 2463978646 CHA_Ziel_FahrPr_ALR 0 "keine_Funktion" 1 "Programm_1" 2 "Programm_2" 3 "Programm_3" 4 "Programm_4" 5 "Programm_5" 6 "Programm_6" 7 "Programm_7" 8 "Programm_8" 9 "Programm_9" 10 "Programm_10" 11 "Programm_11" 12 "Programm_12" 13 "Programm_13" 14 "Programm_14" 15 "Programm_15";
VAL_ 2463978646 CHA_Ziel_FahrPr_MO_BZS 0 "keine_Funktion" 1 "Programm_1" 2 "Programm_2" 3 "Programm_3" 4 "Programm_4" 5 "Programm_5" 6 "Programm_6" 7 "Programm_7" 8 "Programm_8" 9 "Programm_9" 10 "Programm_10" 11 "Programm_11" 12 "Programm_12" 13 "Programm_13" 14 "Programm_14" 15 "Programm_15";
VAL_ 2463978646 CHA_Ziel_FahrPr_DR 0 "keine_Funktion" 1 "Programm_1" 2 "Programm_2" 3 "Programm_3" 4 "Programm_4" 5 "Programm_5" 6 "Programm_6" 7 "Programm_7" 8 "Programm_8" 9 "Programm_9" 10 "Programm_10" 11 "Programm_11" 12 "Programm_12" 13 "Programm_13" 14 "Programm_14" 15 "Programm_15";
VAL_ 2463978646 CHA_Ziel_FahrPr_VAQ 0 "keine_Funktion" 1 "Programm_1" 2 "Programm_2" 3 "Programm_3" 4 "Programm_4" 5 "Programm_5" 6 "Programm_6" 7 "Programm_7" 8 "Programm_8" 9 "Programm_9" 10 "Programm_10" 11 "Programm_11" 12 "Programm_12" 13 "Programm_13" 14 "Programm_14" 15 "Programm_15";
VAL_ 2463978646 CHA_Ziel_FahrPr_AFS 0 "keine_Funktion" 1 "Programm_1" 2 "Programm_2" 3 "Programm_3" 4 "Programm_4" 5 "Programm_5" 6 "Programm_6" 7 "Programm_7" 8 "Programm_8" 9 "Programm_9" 10 "Programm_10" 11 "Programm_11" 12 "Programm_12" 13 "Programm_13" 14 "Programm_14" 15 "Programm_15";
VAL_ 2463978646 CHA_Ziel_FahrPr_PreCrash 0 "keine_Funktion" 1 "Programm_1" 2 "Programm_2" 3 "Programm_3" 4 "Programm_4" 5 "Programm_5" 6 "Programm_6" 7 "Programm_7" 8 "Programm_8" 9 "Programm_9" 10 "Programm_10" 11 "Programm_11" 12 "Programm_12" 13 "Programm_13" 14 "Programm_14" 15 "Programm_15";
VAL_ 2463978646 CHA_Ziel_FahrPr_EPS 0 "keine_Funktion" 1 "Programm_1" 2 "Programm_2" 3 "Programm_3" 4 "Programm_4" 5 "Programm_5" 6 "Programm_6" 7 "Programm_7" 8 "Programm_8" 9 "Programm_9" 10 "Programm_10" 11 "Programm_11" 12 "Programm_12" 13 "Programm_13" 14 "Programm_14" 15 "Programm_15";
VAL_ 2463978646 CHA_Ziel_FahrPr_ACC 0 "keine_Funktion" 1 "Programm_1" 2 "Programm_2" 3 "Programm_3" 4 "Programm_4" 5 "Programm_5" 6 "Programm_6" 7 "Programm_7" 8 "Programm_8" 9 "Programm_9" 10 "Programm_10" 11 "Programm_11" 12 "Programm_12" 13 "Programm_13" 14 "Programm_14" 15 "Programm_15";
VAL_ 2463978646 CHA_Ziel_FahrPr_SAK 0 "keine_Funktion" 1 "Programm_1" 2 "Programm_2" 3 "Programm_3" 4 "Programm_4" 5 "Programm_5" 6 "Programm_6" 7 "Programm_7" 8 "Programm_8" 9 "Programm_9" 10 "Programm_10" 11 "Programm_11" 12 "Programm_12" 13 "Programm_13" 14 "Programm_14" 15 "Programm_15";
VAL_ 2463978646 CHA_Ziel_FahrPr_MO_StSt 0 "keine_Funktion" 1 "Programm_1" 2 "Programm_2" 3 "Programm_3" 4 "Programm_4" 5 "Programm_5" 6 "Programm_6" 7 "Programm_7" 8 "Programm_8" 9 "Programm_9" 10 "Programm_10" 11 "Programm_11" 12 "Programm_12" 13 "Programm_13" 14 "Programm_14" 15 "Programm_15";
VAL_ 2463978646 CHA_Ziel_FahrPr_EBKV 0 "keine_Funktion" 1 "Programm_1" 2 "Programm_2" 3 "Programm_3" 4 "Programm_4" 5 "Programm_5" 6 "Programm_6" 7 "Programm_7" 8 "Programm_8" 9 "Programm_9" 10 "Programm_10" 11 "Programm_11" 12 "Programm_12" 13 "Programm_13" 14 "Programm_14" 15 "Programm_15";
VAL_ 2463978646 CHA_Ziel_FahrPr_IL 0 "keine_Funktion" 1 "Programm_1" 2 "Programm_2" 3 "Programm_3" 4 "Programm_4" 5 "Programm_5" 6 "Programm_6" 7 "Programm_7" 8 "Programm_8" 9 "Programm_9" 10 "Programm_10" 11 "Programm_11" 12 "Programm_12" 13 "Programm_13" 14 "Programm_14" 15 "Programm_15";
VAL_ 2463978646 CHA_Current_Mode 0 "keine_Funktion" 1 "Programm_1" 2 "Programm_2" 3 "Programm_3" 4 "Programm_4" 5 "Programm_5" 6 "Programm_6" 7 "Programm_7" 8 "Programm_8" 9 "Programm_9" 10 "Programm_10" 11 "Programm_11" 12 "Programm_12" 13 "Programm_13" 14 "Programm_14" 15 "Programm_15";
VAL_ 2463978646 CHA_Ziel_FahrPr_QS 0 "keine_Funktion" 1 "Programm_1" 2 "Programm_2" 3 "Programm_3" 4 "Programm_4" 5 "Programm_5" 6 "Programm_6" 7 "Programm_7" 8 "Programm_8" 9 "Programm_9" 10 "Programm_10" 11 "Programm_11" 12 "Programm_12" 13 "Programm_13" 14 "Programm_14" 15 "Programm_15";
VAL_ 2463978646 CHA_Ziel_FahrPr_SCU 0 "keine_Funktion" 1 "Programm_1" 2 "Programm_2" 3 "Programm_3" 4 "Programm_4" 5 "Programm_5" 6 "Programm_6" 7 "Programm_7" 8 "Programm_8" 9 "Programm_9" 10 "Programm_10" 11 "Programm_11" 12 "Programm_12" 13 "Programm_13" 14 "Programm_14" 15 "Programm_15";
VAL_ 2463978646 CHA_Ziel_FahrPr_HAL 0 "keine_Funktion" 1 "Programm_1" 2 "Programm_2" 3 "Programm_3" 4 "Programm_4" 5 "Programm_5" 6 "Programm_6" 7 "Programm_7" 8 "Programm_8" 9 "Programm_9" 10 "Programm_10" 11 "Programm_11" 12 "Programm_12" 13 "Programm_13" 14 "Programm_14" 15 "Programm_15";
VAL_ 2463978646 CHA_Ziel_FahrPr_NR 0 "keine_Funktion" 1 "Programm_1" 2 "Programm_2" 3 "Programm_3" 4 "Programm_4" 5 "Programm_5" 6 "Programm_6" 7 "Programm_7" 8 "Programm_8" 9 "Programm_9" 10 "Programm_10" 11 "Programm_11" 12 "Programm_12" 13 "Programm_13" 14 "Programm_14" 15 "Programm_15";
VAL_ 2463978646 CHA_Ziel_FahrPr_AV 0 "keine_Funktion" 1 "Programm_1" 2 "Programm_2" 3 "Programm_3" 4 "Programm_4" 5 "Programm_5" 6 "Programm_6" 7 "Programm_7" 8 "Programm_8" 9 "Programm_9" 10 "Programm_10" 11 "Programm_11" 12 "Programm_12" 13 "Programm_13" 14 "Programm_14" 15 "Programm_15";
VAL_ 2463978646 CHA_Ziel_FahrPr_MXB 0 "keine_Funktion" 1 "Programm_1" 2 "Programm_2" 3 "Programm_3" 4 "Programm_4" 5 "Programm_5" 6 "Programm_6" 7 "Programm_7" 8 "Programm_8" 9 "Programm_9" 10 "Programm_10" 11 "Programm_11" 12 "Programm_12" 13 "Programm_13" 14 "Programm_14" 15 "Programm_15";
VAL_ 2463978646 CHA_Ziel_FahrPr_AFR 0 "keine_Funktion" 1 "Programm_1" 2 "Programm_2" 3 "Programm_3" 4 "Programm_4" 5 "Programm_5" 6 "Programm_6" 7 "Programm_7" 8 "Programm_8" 9 "Programm_9" 10 "Programm_10" 11 "Programm_11" 12 "Programm_12" 13 "Programm_13" 14 "Programm_14" 15 "Programm_15";
VAL_ 2463978646 CHA_Ziel_FahrPr_HDC 0 "keine_Funktion" 1 "Programm_1" 2 "Programm_2" 3 "Programm_3" 4 "Programm_4" 5 "Programm_5" 6 "Programm_6" 7 "Programm_7" 8 "Programm_8" 9 "Programm_9" 10 "Programm_10" 11 "Programm_11" 12 "Programm_12" 13 "Programm_13" 14 "Programm_14" 15 "Programm_15";
VAL_ 2463978646 CHA_Ziel_FahrPr_EAR 0 "keine_Funktion" 1 "Programm_1" 2 "Programm_2" 3 "Programm_3" 4 "Programm_4" 5 "Programm_5" 6 "Programm_6" 7 "Programm_7" 8 "Programm_8" 9 "Programm_9" 10 "Programm_10" 11 "Programm_11" 12 "Programm_12" 13 "Programm_13" 14 "Programm_14" 15 "Programm_15";
VAL_ 2463978646 CHA_Ziel_FahrPr_AEB 0 "keine_Funktion" 1 "Programm_1" 2 "Programm_2" 3 "Programm_3" 4 "Programm_4" 5 "Programm_5" 6 "Programm_6" 7 "Programm_7" 8 "Programm_8" 9 "Programm_9" 10 "Programm_10" 11 "Programm_11" 12 "Programm_12" 13 "Programm_13" 14 "Programm_14" 15 "Programm_15";
VAL_ 2463978646 CHA_Ziel_FahrPr_FCWO 0 "keine_Funktion" 1 "Programm_1" 2 "Programm_2" 3 "Programm_3" 4 "Programm_4" 5 "Programm_5" 6 "Programm_6" 7 "Programm_7" 8 "Programm_8" 9 "Programm_9" 10 "Programm_10" 11 "Programm_11" 12 "Programm_12" 13 "Programm_13" 14 "Programm_14" 15 "Programm_15";
VAL_ 2463978646 CHA_Ziel_FahrPr_FCWP 0 "keine_Funktion" 1 "Programm_1" 2 "Programm_2" 3 "Programm_3" 4 "Programm_4" 5 "Programm_5" 6 "Programm_6" 7 "Programm_7" 8 "Programm_8" 9 "Programm_9" 10 "Programm_10" 11 "Programm_11" 12 "Programm_12" 13 "Programm_13" 14 "Programm_14" 15 "Programm_15";
VAL_ 2463978646 CHA_Ziel_FahrPr_ToS_laengs 0 "keine_Funktion" 1 "Programm_1" 2 "Programm_2" 3 "Programm_3" 4 "Programm_4" 5 "Programm_5" 6 "Programm_6" 7 "Programm_7" 8 "Programm_8" 9 "Programm_9" 10 "Programm_10" 11 "Programm_11" 12 "Programm_12" 13 "Programm_13" 14 "Programm_14" 15 "Programm_15";
VAL_ 2463978646 CHA_Ziel_FahrPr_ToS_quer 0 "keine_Funktion" 1 "Programm_1" 2 "Programm_2" 3 "Programm_3" 4 "Programm_4" 5 "Programm_5" 6 "Programm_6" 7 "Programm_7" 8 "Programm_8" 9 "Programm_9" 10 "Programm_10" 11 "Programm_11" 12 "Programm_12" 13 "Programm_13" 14 "Programm_14" 15 "Programm_15";
VAL_ 2463978646 CHA_Ziel_FahrPr_mFDR 0 "keine_Funktion" 1 "Programm_1" 2 "Programm_2" 3 "Programm_3" 4 "Programm_4" 5 "Programm_5" 6 "Programm_6" 7 "Programm_7" 8 "Programm_8" 9 "Programm_9" 10 "Programm_10" 11 "Programm_11" 12 "Programm_12" 13 "Programm_13" 14 "Programm_14" 15 "Programm_15";
VAL_ 2463978646 CHA_Ziel_FahrPr_Reku_ZwGas 0 "kein_Funktion" 1 "Programm_1" 2 "Programm_2" 3 "Programm_3" 4 "Programm_4" 5 "Programm_5" 6 "Programm_6" 7 "Programm_7" 8 "Programm_8" 9 "Programm_9" 10 "Programm_10" 11 "Programm_11" 12 "Programm_12" 13 "Programm_13" 14 "Programm_14" 15 "Programm_15";
VAL_ 2463978646 CHA_Ziel_FahrPr_MO_Freilauf 0 "keine_Funktion" 1 "Programm_1" 2 "Programm_2" 3 "Programm_3" 4 "Programm_4" 5 "Programm_5" 6 "Programm_6" 7 "Programm_7" 8 "Programm_8" 9 "Programm_9" 10 "Programm_10" 11 "Programm_11" 12 "Programm_12" 13 "Programm_13" 14 "Programm_14" 15 "Programm_15";
VAL_ 2463978646 CHA_Ziel_FahrPr_BMS 0 "keine_Funktion" 1 "Programm_1" 2 "Programm_2" 3 "Programm_3" 4 "Programm_4" 5 "Programm_5" 6 "Programm_6" 7 "Programm_7" 8 "Programm_8" 9 "Programm_9" 10 "Programm_10" 11 "Programm_11" 12 "Programm_12" 13 "Programm_13" 14 "Programm_14" 15 "Programm_15";
VAL_ 2463978646 CHA_Current_Mode_BMA 0 "keine_Funktion" 1 "Programm_1" 2 "Programm_2" 3 "Programm_3" 4 "Programm_4" 5 "Programm_5" 6 "Programm_6" 7 "Programm_7" 8 "Programm_8" 9 "Programm_9" 10 "Programm_10" 11 "Programm_11" 12 "Programm_12" 13 "Programm_13" 14 "Programm_14" 15 "Programm_15";
VAL_ 2463978646 CHA_Ziel_FahrPr_PDC 0 "keine_Funktion" 1 "Programm_1" 2 "Programm_2" 3 "Programm_3" 4 "Programm_4" 5 "Programm_5" 6 "Programm_6" 7 "Programm_7" 8 "Programm_8" 9 "Programm_9" 10 "Programm_10" 11 "Programm_11" 12 "Programm_12" 13 "Programm_13" 14 "Programm_14" 15 "Programm_15";
VAL_ 2463978646 CHA_Ziel_FahrPr_HHC 0 "keine_Funktion" 1 "Programm_1" 2 "Programm_2" 3 "Programm_3" 4 "Programm_4" 5 "Programm_5" 6 "Programm_6" 7 "Programm_7" 8 "Programm_8" 9 "Programm_9" 10 "Programm_10" 11 "Programm_11" 12 "Programm_12" 13 "Programm_13" 14 "Programm_14" 15 "Programm_15";
VAL_ 2463978646 CHA_Ziel_FahrPr_EDS 0 "keine_Funktion" 1 "Programm_1" 2 "Programm_2" 3 "Programm_3" 4 "Programm_4" 5 "Programm_5" 6 "Programm_6" 7 "Programm_7" 8 "Programm_8" 9 "Programm_9" 10 "Programm_10" 11 "Programm_11" 12 "Programm_12" 13 "Programm_13" 14 "Programm_14" 15 "Programm_15";
VAL_ 2463978646 CHA_Ziel_FahrPr_PACC 0 "keine_Funktion" 1 "Programm_1" 2 "Programm_2" 3 "Programm_3" 4 "Programm_4" 5 "Programm_5" 6 "Programm_6" 7 "Programm_7" 8 "Programm_8" 9 "Programm_9" 10 "Programm_10" 11 "Programm_11" 12 "Programm_12" 13 "Programm_13" 14 "Programm_14" 15 "Programm_15";
VAL_ 2463978646 CHA_Ziel_FahrPr_AGK 0 "keine_Funktion" 1 "Programm_1" 2 "Programm_2" 3 "Programm_3" 4 "Programm_4" 5 "Programm_5" 6 "Programm_6" 7 "Programm_7" 8 "Programm_8" 9 "Programm_9" 10 "Programm_10" 11 "Programm_11" 12 "Programm_12" 13 "Programm_13" 14 "Programm_14" 15 "Programm_15";
VAL_ 514 DR_Aufbaubeschleunigung_HR 1021 "Sensor_nicht_verbaut" 1022 "Init" 1023 "Fehler";
VAL_ 514 DR_Aufbaubeschleunigung_VR 1021 "Sensor_nicht_verbaut" 1022 "Init" 1023 "Fehler";
VAL_ 514 DR_Aufbaubeschleunigung_VL 1021 "Sensor_nicht_verbaut" 1022 "Init" 1023 "Fehler";
VAL_ 514 DR_Aufbaubeschleunigung_HL 1021 "Sensor_nicht_verbaut" 1022 "Init" 1023 "Fehler";
VAL_ 514 DR_Funktionsstatus 0 "Init" 1 "Funktion_iO" 2 "Fehlerzustand_erkannt" 3 "keine_Inbetriebnahme";
VAL_ 514 DR_Drehwinkelsensortausch_VL 0 "Init";
VAL_ 514 DR_Drehwinkelsensortausch_VR 0 "Init";
VAL_ 514 DR_Drehwinkelsensortausch_HL 0 "Init";
VAL_ 514 DR_Drehwinkelsensortausch_HR 0 "Init";
VAL_ 514 DR_Drehwinkel_VL 4091 "nicht_verwendet" 4092 "nicht_verwendet" 4093 "Sensor_nicht_verbaut" 4094 "Init" 4095 "Fehler";
VAL_ 514 DR_Drehwinkel_VR 4091 "nicht_verwendet" 4092 "nicht_verwendet" 4093 "Sensor_nicht_verbaut" 4094 "Init" 4095 "Fehler";
VAL_ 514 DR_Drehwinkel_HL 4091 "nicht_verwendet" 4092 "nicht_verwendet" 4093 "Sensor_nicht_verbaut" 4094 "Init" 4095 "Fehler";
VAL_ 514 DR_Drehwinkel_HR 4091 "nicht_verwendet" 4092 "nicht_verwendet" 4093 "Sensor_nicht_verbaut" 4094 "Init" 4095 "Fehler";
VAL_ 1485 DC_Temperatur_Alarm 0 "kein_Fehler" 1 "Fehler";
VAL_ 1485 DC_Kl30c_Status 0 "Init" 1 "geschlossen" 2 "offen" 3 "Fehler";
VAL_ 1485 DC_Fehlerstatus 0 "Komponente_IO" 1 "Eingeschr_KompFkt_Entlad_defekt" 3 "Eingeschr_KompFkt_Interlock" 6 "Keine_Komponentenfunktion" 7 "Init";
VAL_ 1485 DC_Peakstrom_verfuegbar 0 "Peakstrom_nicht_verfuegbar" 1 "Peakstrom_verfuegbar";
VAL_ 1485 DC_Abregelung_Temperatur 0 "keine_Abregelung" 1 "Abregelung_Temp";
VAL_ 1485 DC_IstModus_02 0 "Standby" 1 "HV_On_Vorladen" 2 "Tiefsetzen" 3 "Hochsetzen" 4 "Pruefimpuls_12V" 5 "Fehler" 7 "Initialisierung";
VAL_ 1485 DC_Derating 0 "keine_Abregelung" 1 "Abregelung_Ursache_NV" 2 "Abregelung_Ursache_HV" 3 "Abregelung_Ursache_Temp" 4 "Abregelung_Ursache_Intern";
VAL_ 1485 DC_SollVolumenstrom 62 "Init" 63 "Fehler";
VAL_ 1485 DC_Status_Spgfreiheit_HV 0 "Init" 1 "HV_Komponente_spannungsfrei" 2 "HV_Komp_nicht_spannungsfrei" 3 "Fehler_nicht_spannungsfrei";
VAL_ 1485 DC_Temperatur 254 "Init" 255 "Fehler";
VAL_ 247 DC_Vorladung_Status 0 "nicht_abgeschlossen" 1 "abgeschlossen";
VAL_ 247 DC_Fehler_extern 0 "kein_Fehler" 1 "Fehler";
VAL_ 247 DC_Fehler_intern 0 "Init" 1 "interner_Fehler_erkannt";
VAL_ 247 DC_Status_Spgfreiheit 0 "Init" 1 "HV_Komponente_spannungsfrei" 2 "HV_Komp_nicht_spannungsfrei" 3 "Fehler_nicht_spannungsfrei";
VAL_ 247 DC_Status_EoHVL 0 "Init" 1 "Keine_offene_HV_Leitung_erkannt" 2 "offene_HV_Leitung_erkannt" 3 "Fehler";
VAL_ 247 DC_IstModus_02 0 "Standby" 1 "HV_On_Vorladen" 2 "Tiefsetzen" 3 "Hochsetzen" 4 "Pruefimpuls_12V" 5 "Fehler" 7 "Initialisierung";
VAL_ 247 DC_IstStrom_HV 1022 "Init" 1023 "Fehler";
VAL_ 247 DC_IstLeistung_HV 1022 "Init" 1023 "Fehler";
VAL_ 1714 DGN_Verlernzaehler 255 "ungültiger Zählerstand oder kein gültiger Fahrzyklus";
VAL_ 1714 KBI_Kilometerstand 1048574 "Init" 1048575 "Fehler";
VAL_ 1714 UH_Monat 0 "Init" 14 "reserviert" 15 "Fehler";
VAL_ 1714 UH_Tag 0 "Init";
VAL_ 1714 Vehicle_Driving_Cycle 0 "kein_Driving_Cycle_erkannt" 1 "Driving_Cycle_erkannt";
VAL_ 1714 Kombi_02_alt 0 "aktuell" 1 "veraltet";
VAL_ 1714 Uhrzeit_01_alt 0 "aktuell" 1 "veraltet";
VAL_ 851 DiETa_Status 0 "DiETa_betriebsbereit" 2 "Init" 3 "Fehler_oder_defekt";
VAL_ 851 DiETa_ResponseError 0 "normal" 1 "Fehler";
VAL_ 851 DiETa_Car 0 "Init_oder_nicht_verbaut" 1 "Taste_unbetaetigt" 2 "Taste_betaetigt" 3 "Fehler";
VAL_ 851 DiETa_Klima 0 "Init_oder_nicht_verbaut" 1 "Taste_unbetaetigt" 2 "Taste_betaetigt" 3 "Fehler";
VAL_ 851 DiETa_Mode 0 "Init_oder_nicht_verbaut" 1 "Taste_unbetaetigt" 2 "Taste_betaetigt" 3 "Fehler";
VAL_ 851 DiETa_Parken 0 "Init_oder_nicht_verbaut" 1 "Taste_unbetaetigt" 2 "Taste_betaetigt" 3 "Fehler";
VAL_ 851 DiETa_FSH_Taste 0 "Init_oder_nicht_verbaut" 1 "Taste_unbetaetigt" 2 "Taste_betaetigt" 3 "Fehler";
VAL_ 851 DiETa_HSH_Taste 0 "Init_oder_nicht_verbaut" 1 "Taste_unbetaetigt" 2 "Taste_betaetigt" 3 "Fehler";
VAL_ 851 DiETa_Warnblink_Taste 0 "Init_oder_nicht_verbaut" 1 "Taste_unbetaetigt" 2 "Taste_betaetigt" 3 "Fehler";
VAL_ 851 DiETa_FAS_Stufe 0 "Init_oder_nicht_verbaut" 1 "Taste_unbetaetigt" 2 "Taste_betaetigt" 3 "Fehler";
VAL_ 851 DiETa_PAO_ON_Status 0 "LED_Aus" 1 "LED_Ein" 2 "LED_Blinkt" 3 "LED_defekt";
VAL_ 851 DiETa_PAO_OFF_Status 0 "LED_Aus" 1 "LED_Ein" 2 "LED_Blinkt" 3 "LED_defekt";
VAL_ 851 DiETa_Defrost_Taste 0 "Init_oder_nicht_verbaut" 1 "Taste_unbetaetigt" 2 "Taste_betaetigt" 3 "Fehler";
VAL_ 851 DiETa_Lock_Unlock_Taste 0 "Init" 1 "Taste_unbetaetigt" 2 "Taste_betaetigt_unlock" 3 "Taste_betaetigt_lock" 4 "Reserviert" 5 "Reserviert" 6 "Reserviert" 7 "Fehler";
VAL_ 851 DiETa_Mode_roh 0 "Taste_unbetaetigt" 1 "Taste_betaetigt";
VAL_ 1520 DI_KL_58xd 254 "Init" 255 "Fehler";
VAL_ 1520 DI_KL_58xs 126 "Init" 127 "Fehler";
VAL_ 1520 DI_KL_58xt 126 "Init" 127 "Fehler";
VAL_ 1520 BCM1_Stellgroesse_Kl_58s 125 "Nicht_verbaut" 126 "Init" 127 "Fehler";
VAL_ 420 EA_Parken_beibehalten_HMS 0 "Parken_nicht_beibehalten" 1 "Parken_beibehalten" 2 "Init" 3 "Fehler";
VAL_ 420 EA_Ruckstaerke 0 "Keine_Anforderung" 1 "Schwach" 2 "Mittel" 3 "Stark";
VAL_ 420 EA_Warnruckprofil 0 "keine_Ruckanforderung" 1 "Profil_1" 2 "Profil_2" 3 "Profil_3" 4 "Profil_4" 5 "Profil_5" 6 "Profil_6" 7 "Profil_7";
VAL_ 420 EA_aktiv_laengs 0 "nicht_aktiv" 1 "aktiv_Vorstufe" 2 "aktiv_Hauptstufe";
VAL_ 420 EA_Funktionsstatus 0 "EA_INIT" 1 "EA_OFF" 2 "EA_STANDBY" 3 "EA_PHASE0_AKTIV" 4 "EA_PHASE1_AKTIV" 5 "EA_PHASE2_AKTIV" 6 "EA_PHASE3_AKTIV" 7 "EA_REVERSIBLER_FEHLER" 8 "EA_IRREVERSIBLER_FEHLER";
VAL_ 420 EA_Gurtstraffer_Anf 0 "Keine_Anforderung" 1 "Haptik_1" 2 "Haptik_2" 3 "Haptik_3";
VAL_ 420 EA_Anf_Prefill 0 "Prefill_nicht_aktivieren" 1 "Prefill_aktivieren";
VAL_ 420 EA_Anforderung_HMS 0 "keine_Anforderung" 1 "halten" 2 "parken" 3 "halten_Standby" 4 "anfahren" 5 "Loesen_ueber_Rampe" 6 "Parken_mit_P";
VAL_ 420 EA_Ruckfreigabe 0 "keine_Freigabe" 1 "Freigabe";
VAL_ 420 EA_01_Sendestatus 0 "EA_01_im_langsamen_Zyklus" 1 "EA_01_im_schnellen_Zyklus";
VAL_ 420 EA_Sollbeschleunigung 2046 "Neutralwert" 2047 "Fehler";
VAL_ 374 EBKV_Activate_Fallback_ESP 0 "Rueckfallebene_nicht_aktiv" 1 "Rueckfallebene_aktiv";
VAL_ 374 EBKV_Restdruckabsenkung 0 "RPR_Passive" 1 "RPR_Preload" 2 "RPR_Hold" 3 "RPR_Suction" 4 "RPR_HoldLowPressure" 5 "RPR_Abort";
VAL_ 374 EBKV_Status_02 0 "EBKV_nicht_initialisiert" 1 "EBKV_Fehler_Zustand_aus" 2 "EBKV_Diagnose" 3 "EBKV_nicht_belegt" 4 "EBKV_Standalone" 5 "EBKV_degradiert" 6 "EBKV_Nachlauf_degradiert" 7 "EBKV_bereit" 8 "EBKV_Ausfall_Rekukomponente" 9 "EBKV_nicht_belegt" 10 "EBKV_nicht_belegt" 11 "EBKV_nicht_belegt" 12 "EBKV_nicht_belegt" 13 "EBKV_nicht_belegt" 14 "EBKV_nicht_belegt" 15 "EBKV_nicht_belegt";
VAL_ 374 EBKV_Diagnose 0 "Diagnose_inaktiv" 1 "Diagnose_aktiv";
VAL_ 374 EBKV_Fahrer_bremst 0 "Fahrer_bremst_nicht_selbst" 1 "Fahrer_will_selbst_bremsen";
VAL_ 374 EBKV_QBit_Fahrer_bremst 0 "gueltiger_Wert" 1 "Ersatz_Init_oder_Fehlerwert";
VAL_ 374 EBKV_Fahrer_bremst_deutlich 0 "Fahrer_uebertritt_Schwelle_nicht" 1 "Fahrer_uebertritt_Schwelle";
VAL_ 374 EBKV_OBD_Status 0 "MIL_aus" 1 "MIL_ein";
VAL_ 374 EBKV_VMM_Sek_Notstopp_Status 0 "Init" 1 "Verfuegbar" 2 "Passiv_Ueberwachung" 3 "Aktiv_Ausgeloest" 4 "Systemkomponente_Defekt";
VAL_ 374 EBKV_Anforderung_HMS 0 "keine_Anforderung" 1 "halten" 2 "parken" 3 "halten_Standby" 4 "anfahren" 5 "Loesen_ueber_Rampe";
VAL_ 374 SBS_Anforderung_GE 0 "keine_Anforderung" 1 "P_einlegen";
VAL_ 374 EPB_Status_ext 0 "offen" 1 "geschlossen_Parken" 2 "teilgespannt_Halten" 3 "im_Lauf_oeffnen" 4 "im_Lauf_schliessen" 5 "tbd" 6 "Init" 7 "unbekannt";
VAL_ 374 EBKV_Bremspedalweg 0 "Init" 255 "Fehler";
VAL_ 374 EBKV_Kraftblending_Reserve 254 "Init" 255 "Fehler";
VAL_ 374 EBKV_Aussteuerdruck 251 "Aussteuerdruck_VKM_Start" 252 "Aussteuerdruck_Nachlauf_Phase1" 253 "Aussteuerdruck_Nachlauf_Phase2" 254 "Init" 255 "Fehler";
VAL_ 1603 KBI_Einheit_Datum 0 "Tag/Monat/Jahr" 1 "Monat/Tag/Jahr" 2 "Jahr/Monat/Tag" 3 "reserviert";
VAL_ 1603 KBI_Einheit_Druck 0 "Druckangabe in bar" 1 "Druckangabe in psi" 2 "Druckangabe in kPa" 3 "tbd.";
VAL_ 1603 KBI_Einheit_Streckenanz 0 "Kilometer" 1 "Meilen";
VAL_ 1603 KBI_MFA_v_Einheit_02 0 "kmh" 1 "mph";
VAL_ 1603 KBI_Einheit_Temp 0 "Grad Celsius °C" 1 "Grad Fahrenheit °F";
VAL_ 1603 KBI_Einheit_Uhrzeit 0 "24h" 1 " 12h AM/PM";
VAL_ 1603 KBI_Einheit_Verbrauch 0 "mpg UK" 1 "mpg USA" 2 "Liter/100km" 3 "km/Liter";
VAL_ 1603 KBI_Einheit_Volumen 0 "Liter" 1 "Gallonen UK" 2 "Gallonen USA" 3 "reserviert";
VAL_ 1603 KBI_Einheit_Verbrauch_elektr 0 "kWh_pro_100km" 1 "km_pro_kWh" 2 "kWh_pro_100mls" 3 "mls_pro_kWh" 4 "MPGe";
VAL_ 1603 KBI_Einheit_Tacho 0 "km/h" 1 "mph";
VAL_ 1603 KBI_Einheit_Verbrauch_Gas 0 "kg_per_100km" 1 "km_per_kg" 2 "m3_per_100km" 3 "km_per_m3" 4 "miles_per_lbs" 5 "miles_per_yard3" 6 "miles_per_kg" 7 "miles_per_m3" 8 "miles_per_gallon_equivalent_US";
VAL_ 1603 KBI_Einheit_Masse 0 "kg" 1 "lbs" 2 "reserviert";
VAL_ 192 EM1_Istmodus 0 "Standby" 1 "Momentenreg" 2 "Int_Drehzahlreg" 3 "Spannungsreg" 4 "Ext_Drehzahlreg" 5 "Inverter_Fehler" 6 "Kalibrierung" 7 "Sonderbremsbetrieb" 8 "Freilauf" 15 "Initialisierung";
VAL_ 192 EM1_IstMoment 4094 "Init" 4095 "Fehler";
VAL_ 192 EM1_Moment_AR_Eingriff 4094 "Init" 4095 "Fehler";
VAL_ 192 EM1_IstDrehzahl 32766 "Init" 32767 "Fehler";
VAL_ 192 EM1_AR_aktiv 0 "Init" 1 "Ruckeldaempfer_aktiv";
VAL_ 192 EM1_IstSpannung 4094 "Init" 4095 "Fehler";
VAL_ 192 EM1_Strom_HV 4094 "Init" 4095 "Fehler";
VAL_ 192 EM1_Max_Moment 2046 "Init" 2047 "Fehler";
VAL_ 192 EM1_ErwGrenzen_aktiv 0 "kein_extended_Range" 1 "extended_Range";
VAL_ 192 EM1_Min_Moment 2046 "Init" 2047 "Fehler";
VAL_ 192 EM1_Fehler_ElAntriebAbschaltung 0 "Init" 1 "Abschaltung";
VAL_ 192 EM1_Max_Moment_Lim 2046 "Init" 2047 "Fehler";
VAL_ 192 EM1_Fehler_Notabschaltung 0 "kein_Fehler" 1 "Fehler";
VAL_ 192 EM1_Min_Moment_Lim 2046 "Init" 2047 "Fehler";
VAL_ 192 EM1_Status_DrzEingriff 0 "kein_Eingriff" 1 "Eingriff_Max_Drehzahlregler" 2 "Eingriff_Min_Drehzahlregler" 3 "Fehler";
VAL_ 192 EM1_Mom_DrzEingriff 2046 "Init" 2047 "Fehler";
VAL_ 2463978673 EM1_Status_Spgfreiheit 0 "Init" 1 "HV_Komponente_spannungsfrei" 2 "HV_Komp_nicht_spannungsfrei" 3 "Fehler_nicht_spannungsfrei";
VAL_ 2463978673 EM1_Status_EoHVL 0 "Init" 1 "Keine_offene_HV_Leitung_erkannt" 2 "offene_HV_Leitung_erkannt" 3 "Fehler";
VAL_ 2463978673 EM1_Max_LeistungMech_Sockel 8190 "Init" 8191 "Fehler";
VAL_ 2463978673 EM1_Max_Moment_Sockel 2046 "Init" 2047 "Fehler";
VAL_ 2463978673 EM1_Min_LeistungMech_Sockel 8190 "Init" 8191 "Fehler";
VAL_ 2463978673 EM1_Min_Moment_Sockel 2046 "Init" 2047 "Fehler";
VAL_ 2463978673 EM1_PerfInd_MaxLeistung 1022 "Init";
VAL_ 2463978673 EM1_PerfInd_MaxMoment 1022 "Init";
VAL_ 2463978673 EM1_AnlernenElMotor_Anf 0 "kein_Diagnose_Request" 1 "Diagnose_Request";
VAL_ 2463978673 EM1_OBD_Lampe_Anf 0 "kein_MIL_Request" 1 "MIL_Request";
VAL_ 2463978673 EM1_Generator_Moment 1022 "Init" 1023 "Fehler";
VAL_ 2463978673 EM1_PerfInd_Temperatur 254 "Init";
VAL_ 2463978673 EM1_MaxZul_Drehzahl 254 "Init" 255 "Fehler";
VAL_ 2463978673 EM1_Min_Moment_Gesamt 2046 "Init" 2047 "Fehler";
VAL_ 2463978673 EM1_Fehlerlampe_Anf 0 "kein_Fehler" 1 "Anforderung_rote_Lampe";
VAL_ 2463978673 EM1_Max_Moment_Gesamt 2046 "Init" 2047 "Fehler";
VAL_ 2463978673 EM1_Warnlampe_Anf 0 "kein_Fehler" 1 "Anforderung_gelbe_Lampe";
VAL_ 2463978673 EM1_Rekuperation_Ueberlauf 0 "kein_Ueberlauf" 1 "Ueberlauf";
VAL_ 2463978673 EM1_Verbrauch_Ueberlauf 0 "kein_Ueberlauf" 1 "Ueberlauf";
VAL_ 2463978673 EM1_Fehler_AE 0 "kein_Fehler" 1 "Fehler_aktive_Entladung";
VAL_ 2463978673 EM1_Fehler_Leistungsred 0 "Init" 1 "Leistungsreduzierung";
VAL_ 2463978673 EM1_Fehler_ElAntriebFreilauf 0 "Init" 1 "Fehler__EM_im_Freilauf";
VAL_ 2463978673 EM1_PWR_SollVolumenstrom 62 "Init" 63 "Fehler";
VAL_ 2589283657 EM1_SollVorlauftemperatur 254 "Init" 255 "Fehler";
VAL_ 2589283657 EM1_Temperatur_EM 510 "Init" 511 "Fehler";
VAL_ 2589283657 EM1_EM_SollVolumenstrom 62 "Init" 63 "Fehler";
VAL_ 2589283657 EM1_Max_MechLeistung_nom 4094 "Init" 4095 "Fehler";
VAL_ 2589283657 EM1_Max_Moment_nom 1022 "Init" 1023 "Fehler";
VAL_ 2589283657 EM1_Temperatur_PWR 254 "Init" 255 "Fehler";
VAL_ 184 EM1_Freigabe_Info_WFS 0 "ungueltig" 1 "gueltig";
VAL_ 184 EM1_Sperr_Info_WFS 0 "nicht_gesperrt" 1 "gesperrt";
VAL_ 184 EM1_AR_aktiv 0 "Init" 1 "Ruckeldaempfer_aktiv";
VAL_ 184 EM1_Eta_Sys 510 "Init" 511 "Fehler";
VAL_ 184 EM1_IstStrom 2046 "Init" 2047 "Fehler";
VAL_ 184 EM1_Fehler_ElAntriebFreilauf_Anf 0 "Init" 1 "Fehler_EM_im_Freilauf";
VAL_ 184 EM1_Abregelung_Temperatur 0 "Init" 1 "Abregelung_Temperatur";
VAL_ 184 EM1_AnlernenElMotor_Anf 0 "kein_Diagnose_Request" 1 "Diagnose_Request";
VAL_ 184 EM1_Moment_HVVerbraucher 1023 "Init";
VAL_ 184 EM1_Freigabe_Verfallsinfo_WFS 0 "Aus" 1 "Ein";
VAL_ 184 EM1_Parken_WFS_Status 0 "Limitierung_Inaktiv" 1 "Limitierung_Aktiv" 2 "Abbruch";
VAL_ 184 EM1_HV_betriebsbereit 0 "Init" 1 "Ready_HV";
VAL_ 2527679712 EM1_RtmWarnKommunikation 0 "kein_Fehler" 1 "Fehler_Stufe_1" 2 "Fehler_Stufe_2" 3 "Fehler_Stufe_3" 4 "reserviert" 5 "reserviert" 6 "reserviert" 7 "reserviert";
VAL_ 2527679712 EM1_RtmWarnUeberdrehzahl 0 "kein_Fehler" 1 "Fehler_Stufe_1" 2 "Fehler_Stufe_2" 3 "Fehler_Stufe_3" 4 "reserviert" 5 "reserviert" 6 "reserviert" 7 "reserviert";
VAL_ 2527679712 EM1_RtmWarnUeberstrom 0 "kein_Fehler" 1 "Fehler_Stufe_1" 2 "Fehler_Stufe_2" 3 "Fehler_Stufe_3" 4 "reserviert" 5 "reserviert" 6 "reserviert" 7 "reserviert";
VAL_ 2527679712 EM1_RtmWarnTempEM 0 "kein_Fehler" 1 "Fehler_Stufe_1" 2 "Fehler_Stufe_2" 3 "Fehler_Stufe_3" 4 "reserviert" 5 "reserviert" 6 "reserviert" 7 "reserviert";
VAL_ 2527679712 EM1_RtmWarnTempPWR 0 "kein_Fehler" 1 "Fehler_Stufe_1" 2 "Fehler_Stufe_2" 3 "Fehler_Stufe_3" 4 "reserviert" 5 "reserviert" 6 "reserviert" 7 "reserviert";
VAL_ 193 EM2_Istmodus 0 "Standby" 1 "Momentenreg" 2 "Int_Drehzahlreg" 3 "Spannungsreg" 4 "Ext_Drehzahlreg" 5 "Inverter_Fehler" 6 "Kalibrierung" 7 "Sonderbremsbetrieb" 8 "Freilauf" 15 "Initialisierung";
VAL_ 193 EM2_IstMoment 4094 "Init" 4095 "Fehler";
VAL_ 193 EM2_Moment_AR_Eingriff 4094 "Init" 4095 "Fehler";
VAL_ 193 EM2_IstDrehzahl 32766 "Init" 32767 "Fehler";
VAL_ 193 EM2_AR_aktiv 0 "Init";
VAL_ 193 EM2_IstSpannung 4094 "Init" 4095 "Fehler";
VAL_ 193 EM2_Strom_HV 4094 "Init" 4095 "Fehler";
VAL_ 193 EM2_Max_Moment 2046 "Init" 2047 "Fehler";
VAL_ 193 EM2_ErwGrenzen_aktiv 0 "kein_extended_Range" 1 "extended_Range";
VAL_ 193 EM2_Min_Moment 2046 "Init" 2047 "Fehler";
VAL_ 193 EM2_Fehler_ElAntriebAbschaltung 0 "Init" 1 "Abschaltung";
VAL_ 193 EM2_Max_Moment_Lim 2046 "Init" 2047 "Fehler";
VAL_ 193 EM2_Fehler_Notabschaltung 0 "kein_Fehler" 1 "Fehler";
VAL_ 193 EM2_Min_Moment_Lim 2046 "Init" 2047 "Fehler";
VAL_ 193 EM2_Status_DrzEingriff 0 "kein_Eingriff" 1 "Eingriff_Max_Drehzahlregler" 2 "Eingriff_Min_Drehzahlregler" 3 "Fehler";
VAL_ 193 EM2_Mom_DrzEingriff 2046 "Init" 2047 "Fehler";
VAL_ 2463978674 EM2_Status_Spgfreiheit 0 "Init" 1 "HV_Komponente_spannungsfrei" 2 "HV_Komp_nicht_spannungsfrei" 3 "Fehler_nicht_spannungsfrei";
VAL_ 2463978674 EM2_Status_EoHVL 0 "Init" 1 "Keine_offene_HV_Leitung_erkannt" 2 "offene_HV_Leitung_erkannt" 3 "Fehler";
VAL_ 2463978674 EM2_Max_LeistungMech_Sockel 8190 "Init" 8191 "Fehler";
VAL_ 2463978674 EM2_Max_Moment_Sockel 2046 "Init" 2047 "Fehler";
VAL_ 2463978674 EM2_Min_LeistungMech_Sockel 8190 "Init" 8191 "Fehler";
VAL_ 2463978674 EM2_Min_Moment_Sockel 2046 "Init" 2047 "Fehler";
VAL_ 2463978674 EM2_PerfInd_MaxLeistung 1022 "Init";
VAL_ 2463978674 EM2_PerfInd_MaxMoment 1022 "Init";
VAL_ 2463978674 EM2_AnlernenElMotor_Anf 0 "kein_Diagnose_Request" 1 "Diagnose_Request";
VAL_ 2463978674 EM2_OBD_Lampe_Anf 0 "kein_MIL_Request" 1 "MIL_Request";
VAL_ 2463978674 EM2_Generator_Moment 1022 "Init" 1023 "Fehler";
VAL_ 2463978674 EM2_PerfInd_Temperatur 254 "Init";
VAL_ 2463978674 EM2_MaxZul_Drehzahl 254 "Init" 255 "Fehler";
VAL_ 2463978674 EM2_Min_Moment_Gesamt 2046 "Init" 2047 "Fehler";
VAL_ 2463978674 EM2_Fehlerlampe_Anf 0 "kein_Fehler" 1 "Anforderung_rote_Lampe";
VAL_ 2463978674 EM2_Max_Moment_Gesamt 2046 "Init" 2047 "Fehler";
VAL_ 2463978674 EM2_Warnlampe_Anf 0 "kein_Fehler" 1 "Anforderung_gelbe_Lampe";
VAL_ 2463978674 EM2_Rekuperation_Ueberlauf 0 "kein_Ueberlauf" 1 "Ueberlauf";
VAL_ 2463978674 EM2_Verbrauch_Ueberlauf 0 "kein_Ueberlauf" 1 "Ueberlauf";
VAL_ 2463978674 EM2_Fehler_AE 0 "kein_Fehler" 1 "Fehler_aktive_Entladung";
VAL_ 2463978674 EM2_Fehler_Leistungsred 0 "Init" 1 "Leistungsreduzierung";
VAL_ 2463978674 EM2_Fehler_ElAntriebFreilauf 0 "Init" 1 "Fehler__EM_im_Freilauf";
VAL_ 2463978674 EM2_PWR_SollVolumenstrom 62 "Init" 63 "Fehler";
VAL_ 2589283660 EM2_SollVorlauftemperatur 254 "Init" 255 "Fehler";
VAL_ 2589283660 EM2_Temperatur_EM 510 "Init" 511 "Fehler";
VAL_ 2589283660 EM2_EM_SollVolumenstrom 62 "Init" 63 "Fehler";
VAL_ 2589283660 EM2_Max_MechLeistung_nom 4094 "Init" 4095 "Fehler";
VAL_ 2589283660 EM2_Max_Moment_nom 1022 "Init" 1023 "Fehler";
VAL_ 2589283660 EM2_Temperatur_PWR 254 "Init" 255 "Fehler";
VAL_ 199 EM2_Freigabe_Info_WFS 0 "ungueltig" 1 "gueltig";
VAL_ 199 EM2_Sperr_Info_WFS 0 "nicht_gesperrt" 1 "gesperrt";
VAL_ 199 EM2_AR_aktiv 0 "Init";
VAL_ 199 EM2_Eta_Sys 510 "Init" 511 "Fehler";
VAL_ 199 EM2_IstStrom 2046 "Init" 2047 "Fehler";
VAL_ 199 EM2_Fehler_ElAntriebFreilauf_Anf 0 "Init" 1 "Fehler_EM_im_Freilauf";
VAL_ 199 EM2_Abregelung_Temperatur 0 "Init" 1 "Abregelung_Temperatur";
VAL_ 199 EM2_AnlernenElMotor_Anf 0 "kein_Diagnose_Request" 1 "Diagnose_Request";
VAL_ 199 EM2_Freigabe_Verfallsinfo_WFS 0 "Aus" 1 "Ein";
VAL_ 199 EM2_Parken_WFS_Status 0 "Limitierung_Inaktiv" 1 "Limitierung_Aktiv" 2 "Abbruch";
VAL_ 199 EM2_HV_betriebsbereit 0 "Init" 1 "Ready_HV";
VAL_ 2527679713 EM2_RtmWarnKommunikation 0 "kein_Fehler" 1 "Fehler_Stufe_1" 2 "Fehler_Stufe_2" 3 "Fehler_Stufe_3" 4 "reserviert" 5 "reserviert" 6 "reserviert" 7 "reserviert";
VAL_ 2527679713 EM2_RtmWarnUeberdrehzahl 0 "kein_Fehler" 1 "Fehler_Stufe_1" 2 "Fehler_Stufe_2" 3 "Fehler_Stufe_3" 4 "reserviert" 5 "reserviert" 6 "reserviert" 7 "reserviert";
VAL_ 2527679713 EM2_RtmWarnUeberstrom 0 "kein_Fehler" 1 "Fehler_Stufe_1" 2 "Fehler_Stufe_2" 3 "Fehler_Stufe_3" 4 "reserviert" 5 "reserviert" 6 "reserviert" 7 "reserviert";
VAL_ 2527679713 EM2_RtmWarnTempEM 0 "kein_Fehler" 1 "Fehler_Stufe_1" 2 "Fehler_Stufe_2" 3 "Fehler_Stufe_3" 4 "reserviert" 5 "reserviert" 6 "reserviert" 7 "reserviert";
VAL_ 2527679713 EM2_RtmWarnTempPWR 0 "kein_Fehler" 1 "Fehler_Stufe_1" 2 "Fehler_Stufe_2" 3 "Fehler_Stufe_3" 4 "reserviert" 5 "reserviert" 6 "reserviert" 7 "reserviert";
VAL_ 2589283649 EML_ReifenKorrFaktorHL 510 "Init" 511 "Fehler";
VAL_ 2589283649 EML_ReifenKorrFaktorHR 510 "Init" 511 "Fehler";
VAL_ 2589283649 EML_ReifenKorrFaktorVL 510 "Init" 511 "Fehler";
VAL_ 2589283649 EML_ReifenKorrFaktorVR 510 "Init" 511 "Fehler";
VAL_ 2589283649 EML_QBit_Reifenumfang 0 "gueltiger_Wert" 1 "Ersatz_Init_oder_Fehlerwert";
VAL_ 608 EML_AnzeigeGeschw 1022 "Init" 1023 "Fehler";
VAL_ 2527679687 EPS_ASM_Ereignis 0 "No_Event" 255 "ASM_Trigger";
VAL_ 2527679687 EPS_ASM_Zeitstempel 255 "INIT";
VAL_ 258 ESP_QBit_Gierrate 0 "gueltiger_Wert" 1 "Ersatz_Init_oder_Fehlerwert";
VAL_ 258 ESP_QBit_Laengsbeschl 0 "gueltiger_Wert" 1 "Ersatz_Init_oder_Fehlerwert";
VAL_ 258 ESP_QBit_Querb 0 "gueltiger_Wert" 1 "Ersatz_Init_oder_Fehlerwert";
VAL_ 258 ESP_Querbeschleunigung 255 "Fehler";
VAL_ 258 ESP_Laengsbeschl 1022 "Signal_nicht_vorhanden" 1023 "Fehler";
VAL_ 258 ESC_Motorstartverzoegerung 0 "Startfreigabe" 1 "Anforderung_Startverzoegerung";
VAL_ 258 ESC_SeitenwindAssistent_Eingriff 0 "Kein_SWA_Eingriff_und_Init" 1 "SWA_Eingriff_aktiv";
VAL_ 258 ESP_Anschleppstart_Freigabe 0 "kein_Schleppstart_oder_NotSchleppstart_erlaubt" 1 "NotSchleppstart_erlaubt" 2 "Schleppstart_und_NotSchleppStart_erlaubt";
VAL_ 258 ESC_Unterdruckmangel_erkannt 0 "kein_Unterdruckmangel_erkannt" 1 "Unterdruckmangel_erkannt";
VAL_ 258 ESP_Gierrate 16383 "Fehler";
VAL_ 258 ESP_VZ_Gierrate 0 "positiv" 1 "negativ";
VAL_ 258 ESP_Notbremsanzeige 0 "keine_Notbremsung_erkannt" 1 "Notbremsung_erkannt";
VAL_ 258 ESP_SpannungsAnf 0 "keine_Anforderung" 1 "Anforderung_Spannungswert_1";
VAL_ 258 ESP_PLA_Abbruch 0 "Init" 1 "Geschwindigkeitsueberschreitung" 2 "Falscher_PLA_Status" 3 "Deaktivierung_durch_Abbruch_Lenkung" 4 "PLA_Bremsanforderung_nach_Stillstand" 5 "Abbruch_durch_Kl15_aus" 6 "Abbruch_durch_FT_offen";
VAL_ 258 ESP_Status_ESP_PLA 8 "ESP_PLA_funktionsbereit" 0 "ESP_PLA_deaktiv" 9 "ESP_PLA_Neustart" 1 "ESP_PLA_Init" 10 "ESP_PLA_Abbruch" 2 "ESP_PLA_Fehler" 4 "ESP_PLA_aktivierbar" 6 "ESP_PLA_Bremse_aktiv";
VAL_ 258 ESP_QBit_Bremsdruck 0 "gueltiger_Wert" 1 "Ersatz_Init_oder_Fehlerwert";
VAL_ 258 ESP_QBit_Fahrer_bremst 0 "gueltiger_Wert" 1 "Ersatz_Init_oder_Fehlerwert";
VAL_ 258 ESP_Schwelle_Unterdruck 0 "kein_Signal" 1 "Unterdruck_kleiner_gleich_450_mbar" 2 "Unterdruck_groesser_450_mbar" 3 "Fehler_Unterdrucksensor";
VAL_ 258 ESP_Bremsdruck 1023 "Fehler";
VAL_ 258 ESP_Fahrer_bremst 0 "Bremsdruckschwelle_nicht_ueberschritten" 1 "Bremsdruckschwelle_ueberschritten";
VAL_ 258 ESP_Verz_TSK_aktiv 0 "TSK_Verzoegerung_inaktiv" 1 "TSK_Verzoegerung_aktiv";
VAL_ 258 ESP_Lenkeingriff_ADS 0 "kein_Lenkeingriff" 1 "stabilisierender_Lenkeingriff";
VAL_ 258 ESP_Konsistenz_TSK 0 "Botschaft_fuer_Verzoegerungsanforderung_konsistent" 1 "Botschaft_fuer_Verzoegerungsanforderung_nicht_konsistent";
VAL_ 258 ESP_Bremsruck_AWV2 0 "kein_Bremsruck_ausgefuehrt" 1 "Bremsruck_ausgefuehrt";
VAL_ 258 ESP_Konsistenz_AWV2 0 "Botschaft_fuer_AWV2_konsistent" 1 "Botschaft_fuer_AWV2_nicht_konsistent";
VAL_ 258 ECD_Fehler 0 "ECD_iO" 1 "ECD_Fehler";
VAL_ 258 ECD_nicht_verfuegbar 0 "ECD_Funktion_verfuegbar" 1 "ECD_Funktion_nicht_verfuegbar";
VAL_ 258 ESP_Status_Bremsentemp 0 "Bremse_nicht_ueberhitzt" 1 "Bremse_ueberhitzt";
VAL_ 258 ESP_Autohold_Standby 0 "Autohold_nicht_im_Standby" 1 "Autohold_im_Standby";
VAL_ 258 ESP_HDC_Standby 0 "HDC_Funktion_nicht_im_Standby" 1 "HDC_Funktion_im_Standby";
VAL_ 258 ESP_HBA_aktiv 0 "HBA_nicht_aktiv" 1 "HBA_aktiv";
VAL_ 258 ESP_Prefill_ausgeloest 0 "nicht_ausgeloest" 1 "Prefill_ausgeloest";
VAL_ 258 ESP_Rueckwaertsfahrt_erkannt 0 "keine_Rueckwaetsfahrt" 1 "Rueckwaertsfahrt_sicher_erkannt";
VAL_ 258 ESP_Status_Anfahrhilfe 0 "Aus" 1 "Ein";
VAL_ 258 ESP_HDC_aktiv 0 "inaktiv" 1 "aktiv";
VAL_ 258 ESP_StartStopp_Info 0 "Motorlauf_nicht_notwendig_(Stoppfreigabe)" 1 "Motoranlauf_nicht_zwingend_notwendig_(Stoppverbot,keine_Startanforderung)" 2 "Motoranlauf_zwingend_notwendig_(Startanforderung)" 3 "Systemfehler";
VAL_ 258 ESP_Eingr_HL 0 "kein_Eingriff" 1 "ESP_Eingriff_HL";
VAL_ 258 ESP_Eingr_HR 0 "kein_Eingriff" 1 "ESP_Eingriff_HR";
VAL_ 258 ESP_Eingr_VL 0 "kein_Eingriff" 1 "ESP_Eingriff_VL";
VAL_ 258 ESP_Eingr_VR 0 "kein_Eingriff" 1 "ESP_Eingriff_VR";
VAL_ 258 ESP_BKV_Unterdruck 0 "nicht_verbaut_oder_nicht_kodiert" 254 "Init" 255 "Fehler";
VAL_ 258 ESP_Autohold_aktiv 0 "Autohold_inaktiv" 1 "Autohold_aktiv";
VAL_ 258 ESP_FStatus_Anfahrhilfe 0 "kein_Fehler" 1 "Fehler";
VAL_ 258 ESP_Verz_EPB_aktiv 0 "nicht_aktiviert" 1 "aktiviert";
VAL_ 258 ECD_Bremslicht 0 "Aus" 1 "Ein";
VAL_ 258 ESP_Verzoeg_EPB_verf 0 "nicht_verfuegbar" 1 "System_verfuegbar";
VAL_ 258 ESP_Status_Bremsdruck 0 "Bremse_drucklos" 1 "mit_Bremsdruck";
VAL_ 258 ESP_Anforderung_EPB 0 "keine_Anforderung" 1 "Anforderung_Oeffnen" 2 "Anforderung_Schliessen" 3 "reserviert";
VAL_ 258 ESP_ANB_CM_Rueckk_Umsetz 0 "keine_Ausfuehrung" 1 "Ausfuehrung";
VAL_ 258 ESP_Konsistenz_ACC_Botschaft 0 "Botschaft_fuer_ACC_konsistent" 1 "Botschaft_fuer_ACC_nicht_konsistent";
VAL_ 258 ESP_Stillstandsphase_erschoepft 0 "sicheres_Halten_moeglich" 1 "kein_sicheres_Halten_moeglich";
VAL_ 258 ESP_ZT_Rueckk_Umsetz 0 "keine_Ausfuehrung" 1 "Ausfuehrung";
VAL_ 258 ESP_Tuerkontakt_Fahrertuer 0 "Schalter_geschlossen" 1 "Schalter_offen";
VAL_ 258 ESP_Abrutschen_Stillstand 0 "kein_Abrutschen_erkannt" 1 "Abrutschen_erkannt";
VAL_ 258 ESP_Fahrer_tritt_ZBR_Schw 0 "Fahrer_uebertritt_ZBR_Schwelle_nicht" 1 "Fahrer_uebertritt_ZBR_Schwelle";
VAL_ 258 ESP_QBit_v_ref 0 "gueltiger_Wert" 1 "Ersatz_Init_oder_Fehlerwert";
VAL_ 258 ESP_v_ref_Fahrtrichtung 0 "Fahrtrichtung_nicht_definiert" 1 "Vorwaerts" 2 "Rueckwaerts" 3 "Stillstand";
VAL_ 258 ESC_Bremsdruckgradient 251 "groesser_2500_bar_per_sec" 254 "Init" 255 "Fehler";
VAL_ 258 ESP_v_ref 4093 "Unterspannung" 4094 "Init" 4095 "Fehler";
VAL_ 258 ESC_Hydr_Fkt_aktiv 0 "keine_Aktivitaet" 1 "ESC_Druckaufbau_HBx_HFC_aktiv" 2 "Warnrucklevel_Summand_1" 3 "Warnrucklevel_Summand_3";
VAL_ 258 ESC_QBit_Fahrerbremswunsch 0 "gueltiger_Wert" 1 "Ersatz_Init_oder_Fehlerwert";
VAL_ 258 ESC_Fahrerbremswunsch 1023 "Fehler";
VAL_ 258 ESCGeneratorSollMoment 4094 "Init" 4095 "Fehler";
VAL_ 258 ESC_Raddruck_max 254 "Init" 255 "Fehler";
VAL_ 258 EPB_QBit_Pedalweg_Kuppl 0 "gültiger Wert" 1 "Ersatz-, Init- oder Fehlerwert";
VAL_ 258 EPB_Freig_Verzoeg_Anf 0 "nicht freigegeben" 1 "freigegeben";
VAL_ 258 EPB_Pedalweg_Kuppl 0 "Init" 255 "Fehler";
VAL_ 258 EPB_DAA_Randbed_erf 0 "Randbed_nicht_erfuellt" 1 "Randbed_erfuellt";
VAL_ 258 EPB_Fehlerstatus_02 0 "kein_Fehler" 1 "Fehler_ausserhalb_apply_release" 2 "Fehler_einseitig_apply_release" 3 "Fehler_beidseitig_apply_release";
VAL_ 258 EPB_Schalterposition 0 "keine Fahreranforderung" 1 "Fahreranforderung Öffnen" 2 "Fahreranforderung Schließen" 3 "Fehler";
VAL_ 258 EPB_QBit_Schalterpos 0 "gültiger Wert (volle Funktion)" 1 " Ersatz-, Init- oder Fehlerwert (Schalter ausser Funktion)";
VAL_ 258 EPB_Spannkraft 30 "Init" 31 "Fehler";
VAL_ 258 EPB_Status_02 0 "offen" 1 "geschlossen_Parken" 2 "teilgespannt_Halten" 3 "im_Lauf_oeffnen" 4 "im_Lauf_schliessen" 5 "tbd" 6 "Init" 7 "unbekannt";
VAL_ 258 EPB_Status 0 "offen" 1 "Bremse_geschl_(Spannkraft_voll/reduziert)" 2 "Aktuator_im_Lauf" 3 "Fehler_oder_unbekannt";
VAL_ 258 ESP_Status_Bremsentemp_02 0 "nicht_erhoeht" 1 "Schwelle_1" 2 "Schwelle_2";
VAL_ 252 ESC_aktBr_Modus 0 "Aktivbremsung_Aus" 1 "Aktivbremsung_Volumenkompensation" 2 "Aktivbremsung_Aktiv" 3 "Aktivbremsung_Runout";
VAL_ 252 ESC_Blending_Solldruck 1022 "Init" 1023 "Fehler";
VAL_ 252 ESC_EBKV_Kraftblending_Modus 0 "Inactive" 1 "Hold" 2 "Active";
VAL_ 252 ESC_Bremsdruck_Modell 1022 "Init" 1023 "Fehler";
VAL_ 252 ESC_Bremsdruck_02 1023 "Fehler";
VAL_ 252 ESC_QBit_Bremsdruck_02 0 "gueltiger_Wert" 1 "Ersatz_Init_oder_Fehlerwert";
VAL_ 252 ESP_HL_Radgeschw_02 65533 "Unterspannung" 65534 "Init" 65535 "Fehler";
VAL_ 252 ESP_HR_Radgeschw_02 65533 "Unterspannung" 65534 "Init" 65535 "Fehler";
VAL_ 252 ESP_VL_Radgeschw_02 65533 "Unterspannung" 65534 "Init" 65535 "Fehler";
VAL_ 252 ESP_VR_Radgeschw_02 65533 "Unterspannung" 65534 "Init" 65535 "Fehler";
VAL_ 252 ESP_FZR_uebersteuern 254 "Init" 255 "Fehler";
VAL_ 252 ESP_FZR_untersteuern 254 "Init" 255 "Fehler";
VAL_ 252 ESC_Anf_Mindestreku 0 "nicht_angefordert" 1 "angefordert";
VAL_ 252 ESC_GMV_aktiv 0 "keine_Aktivitaet" 1 "Aktivitaet_durch_AWA";
VAL_ 252 ESC_GMV_nicht_verfuegbar 0 "verfuegbar" 1 "nicht_verfuegbar";
VAL_ 252 ESC_Status_vRef_Stuetzeingriff 0 "kein_Eingriff" 1 "Stuetzungseingriff";
VAL_ 252 FDR_Allradverteilung_aktiv 0 "kein_Eingriff" 1 "Allradeingriff_aktiv";
VAL_ 252 FDR_Anf_Allradbetrieb 0 "keine_Anforderung" 1 "Kraftschluss_an_beiden_Achsen_herstellen";
VAL_ 252 ESP_HL_Bremsmoment 254 "Init" 255 "Fehler";
VAL_ 252 ESP_HR_Bremsmoment 254 "Init" 255 "Fehler";
VAL_ 252 ESP_VR_Bremsmoment 254 "Init" 255 "Fehler";
VAL_ 252 ESP_VL_Bremsmoment 254 "Init" 255 "Fehler";
VAL_ 252 ESP_FDR_uebersteuern 254 "Init" 255 "Fehler";
VAL_ 252 ESP_FDR_untersteuern 254 "Init" 255 "Fehler";
VAL_ 252 TSMomBegrenzung 4094 "Init" 4095 "Fehler";
VAL_ 252 ESC_Allrad_Anteil_max_sek 510 "Init" 511 "Fehler";
VAL_ 252 ESC_Allrad_Anteil_min_sek 510 "Init" 511 "Fehler";
VAL_ 252 ESC_Status_Eingriff 0 "kein Eingriff" 1 "ASR-Eingriff" 2 "MSR-Eingriff" 3 "nicht belegt ";
VAL_ 252 ESC_Status_Eingriff_sek 0 "kein Eingriff" 1 "ASR-Eingriff" 2 "MSR-Eingriff" 3 "nicht belegt ";
VAL_ 252 ESC_MomRad_Eingriff 8190 "Init" 8191 "Fehler";
VAL_ 252 ESC_MomRad_Eingriff_sek 8190 "Init" 8191 "Fehler";
VAL_ 252 ESC_Achsdrehzahl_Max 16382 "Init" 16383 "Fehler";
VAL_ 252 ESC_Achsdrehzahl_Min 16382 "Init" 16383 "Fehler";
VAL_ 252 ESC_Achsdrehzahl_Max_sek 16382 "Init" 16383 "Fehler";
VAL_ 252 ESC_Achsdrehzahl_Min_sek 16382 "Init" 16383 "Fehler";
VAL_ 2463978647 ESP_ACC_LDE 0 "Lebensdauerende_nicht_erreicht" 1 "Lebensdauerende_erreicht";
VAL_ 2463978647 ESP_Allrad_Antrieb 0 "Front" 1 "Allrad";
VAL_ 2463978647 ESP_Codierung_ADS 0 "Init" 1 "ESP_nicht_ADS_codiert" 2 "ADS_codiert" 3 "tbd";
VAL_ 2463978647 ESP_RTA_HL 254 "Abgleich_nocht_nicht_genuegend_konvergent" 255 "Fehler";
VAL_ 2463978647 ESP_RTA_HR 254 "Abgleich_nocht_nicht_genuegend_konvergent" 255 "Fehler";
VAL_ 2463978647 ESP_RTA_VR 254 "Abgleich_nocht_nicht_genuegend_konvergent" 255 "Fehler";
VAL_ 2463978647 OBD_Fehler_Radsensor_HL 0 "kein Fehler / Init / nicht verbaut" 1 "KS- (Kurzschluss nach minus)" 2 "KS+ (Kurzschluss nach plus)" 3 "OC (Leitungsunterbrechung)" 4 "OOR+ (Signal zu gross)" 5 "OOR- (Signal zu klein)" 6 "RC+ (Signal unplausibel zu gross)" 7 "RC- (Signal unplausibel zu klein)" 8 "KS+/OC (Kurzschluss nach plus/Unterbrechung)" 9 "KS-/OC  (Kurzschluss nach minus/Unterbrechung)" 10 "KS-/KS+  (Kurzschluss nach minus/plus)" 11 "KS-/KS+/OC (Kurzschluss nach minus/plus/Unterbrechung)" 12 "frei" 13 "frei" 14 "frei" 15 "frei";
VAL_ 2463978647 OBD_Fehler_Radsensor_HR 0 "kein Fehler / Init / nicht verbaut" 1 "KS- (Kurzschluss nach minus)" 2 "KS+ (Kurzschluss nach plus)" 3 "OC (Leitungsunterbrechung)" 4 "OOR+ (Signal zu gross)" 5 "OOR- (Signal zu klein)" 6 "RC+ (Signal unplausibel zu gross)" 7 "RC- (Signal unplausibel zu klein)" 8 "KS+/OC (Kurzschluss nach plus/Unterbrechung)" 9 "KS-/OC  (Kurzschluss nach minus/Unterbrechung)" 10 "KS-/KS+  (Kurzschluss nach minus/plus)" 11 "KS-/KS+/OC (Kurzschluss nach minus/plus/Unterbrechung)" 12 "frei" 13 "frei" 14 "frei" 15 "frei";
VAL_ 2463978647 OBD_Fehler_Radsensor_VL 0 "kein Fehler / Init / nicht verbaut" 1 "KS- (Kurzschluss nach minus)" 2 "KS+ (Kurzschluss nach plus)" 3 "OC (Leitungsunterbrechung)" 4 "OOR+ (Signal zu gross)" 5 "OOR- (Signal zu klein)" 6 "RC+ (Signal unplausibel zu gross)" 7 "RC- (Signal unplausibel zu klein)" 8 "KS+/OC (Kurzschluss nach plus/Unterbrechung)" 9 "KS-/OC  (Kurzschluss nach minus/Unterbrechung)" 10 "KS-/KS+  (Kurzschluss nach minus/plus)" 11 "KS-/KS+/OC (Kurzschluss nach minus/plus/Unterbrechung)" 12 "frei" 13 "frei" 14 "frei" 15 "frei";
VAL_ 2463978647 OBD_Fehler_Radsensor_VR 0 "kein Fehler / Init / nicht verbaut" 1 "KS- (Kurzschluss nach minus)" 2 "KS+ (Kurzschluss nach plus)" 3 "OC (Leitungsunterbrechung)" 4 "OOR+ (Signal zu gross)" 5 "OOR- (Signal zu klein)" 6 "RC+ (Signal unplausibel zu gross)" 7 "RC- (Signal unplausibel zu klein)" 8 "KS+/OC (Kurzschluss nach plus/Unterbrechung)" 9 "KS-/OC  (Kurzschluss nach minus/Unterbrechung)" 10 "KS-/KS+  (Kurzschluss nach minus/plus)" 11 "KS-/KS+/OC (Kurzschluss nach minus/plus/Unterbrechung)" 12 "frei" 13 "frei" 14 "frei" 15 "frei";
VAL_ 2463978647 ESP_Qualifizierung_Antriebsart 0 "alte_Bedeutung_Bit_ESP_Allrad_Antrieb" 1 "neue_Bedeutung_Bit_ESP_Allrad_Antrieb";
VAL_ 2463978647 ESP_Offroad_Modus 0 "kein_ESP_Offroadmodus" 1 "ESP_Offroadmodus";
VAL_ 2463978647 ESP_MKB_ausloesbar 0 "Multikollisionsbremsung_nicht_freigeschaltet" 1 "Multikollisionsbremsung_freigeschaltet";
VAL_ 2463978647 ESP_Stat_FallBack_eBKV 0 "Rueckfallebene_nicht_vorhanden" 1 "Rueckfallebene_vorhanden";
VAL_ 2463978647 ESP_CM_Variante 0 "Standard" 1 "Erweitert";
VAL_ 2463978647 ESP_OBD_Status 0 "MIL_aus" 1 "MIL_ein";
VAL_ 2463978647 ESP_Rollenmodus_Deaktivieren 0 "keine_Aenderung" 1 "Abbruch";
VAL_ 2463978647 ESP_nachtr_Stopp_Anf 0 "nicht_angefordert" 1 "angefordert";
VAL_ 2527679683 ESC_ASM_Ereignis 0 "No_Event" 255 "ASM_Trigger";
VAL_ 2527679683 ESC_ASM_Zeitstempel 255 "Init";
VAL_ 278 ESP_QBit_Wegimpuls_VL 0 "gueltiger_Wert" 1 "Ersatz_Init_oder_Fehlerwert";
VAL_ 278 ESP_QBit_Wegimpuls_VR 0 "gueltiger_Wert" 1 "Ersatz_Init_oder_Fehlerwert";
VAL_ 278 ESP_QBit_Wegimpuls_HL 0 "gueltiger_Wert" 1 "Ersatz_Init_oder_Fehlerwert";
VAL_ 278 ESP_QBit_Wegimpuls_HR 0 "gueltiger_Wert" 1 "Ersatz_Init_oder_Fehlerwert";
VAL_ 278 ESP_Wegimpuls_VL 1021 "Init" 1022 "Unterspannung" 1023 "Fehler";
VAL_ 278 ESP_Wegimpuls_VR 1021 "Init" 1022 "Unterspannung" 1023 "Fehler";
VAL_ 278 ESP_Wegimpuls_HL 1021 "Init" 1022 "Unterspannung" 1023 "Fehler";
VAL_ 278 ESP_Wegimpuls_HR 1021 "Init" 1022 "Unterspannung" 1023 "Fehler";
VAL_ 278 ESP_VL_Fahrtrichtung 0 "Vorwaerts" 1 "Rueckwaerts" 2 "Init" 3 "ungueltig_oder_nicht_verbaut";
VAL_ 278 ESP_VR_Fahrtrichtung 0 "Vorwaerts" 1 "Rueckwaerts" 2 "Init" 3 "ungueltig_oder_nicht_verbaut";
VAL_ 278 ESP_HL_Fahrtrichtung 0 "Vorwaerts" 1 "Rueckwaerts" 2 "Init" 3 "ungueltig_oder_nicht_verbaut";
VAL_ 278 ESP_HR_Fahrtrichtung 0 "Vorwaerts" 1 "Rueckwaerts" 2 "Init" 3 "ungueltig_oder_nicht_verbaut";
